VERSION ""

NS_ :

BS_:

BU_: TM

BO_ 1158 BRAKE_SF: 8 Vector__XXX
 SG_ EPAS_Invalid_Failure_Status : 33|2@0+ (1,0) [0|3] ""  TM
 SG_ SAS_MTO_Failure_Status : 29|2@0+ (1,0) [0|3] ""  TM
 SG_ EPAS_MRC_Failure_Status : 63|2@0+ (1,0) [0|3] ""  TM
 SG_ EPAS_CRC_Failure_Status : 49|2@0+ (1,0) [0|3] ""  TM
 SG_ EPAS_MTO_Failure_Status : 53|2@0+ (1,0) [0|3] ""  TM
 SG_ ESP_SW_Version : 7|8@0+ (1,0) [0|255] ""  TM
 SG_ ESP_Err_State_Trans_Cntr : 15|8@0+ (1,0) [0|255] ""  TM
 SG_ BattVolt_ESP : 23|8@0+ (0.1,0) [0|25] "V"  TM
 SG_ ESP_BO_Failure_Status : 25|2@0+ (1,0) [0|3] ""  TM
 SG_ ESP_EP_Failure_Status : 27|2@0+ (1,0) [0|3] ""  TM
 SG_ DCS_MTO_Failure_Status : 31|2@0+ (1,0) [0|3] ""  TM
 SG_ AMT_AT_DCT_MTO_Failure_Status : 35|2@0+ (1,0) [0|3] ""  TM
 SG_ DCS_Invalid_Failure_Status : 37|2@0+ (1,0) [0|3] ""  TM
 SG_ AMT_AT_DCT_Invalid_Failure__0000 : 39|2@0+ (1,0) [0|3] ""  TM
 SG_ EMsMToFailureStatus : 41|2@0+ (1,0) [0|3] ""  TM
 SG_ ESClMToFailureStatus : 43|2@0+ (1,0) [0|3] ""  TM
 SG_ EMsInvalidFailureStatus : 45|2@0+ (1,0) [0|3] ""  TM
 SG_ BCmMToFailureStatus : 47|2@0+ (1,0) [0|3] ""  TM
 SG_ BCM_Invalid_Status_Failure : 51|2@0+ (1,0) [0|3] ""  TM
 SG_ IPcInvalidFailureStatus : 55|2@0+ (1,0) [0|3] ""  TM
 SG_ IPcMToFailureStatus : 57|2@0+ (1,0) [0|3] ""  TM
 SG_ EMsCRcFailureStatus : 59|2@0+ (1,0) [0|3] ""  TM
 SG_ EMsMRcFailureStatus : 61|2@0+ (1,0) [0|3] ""  TM

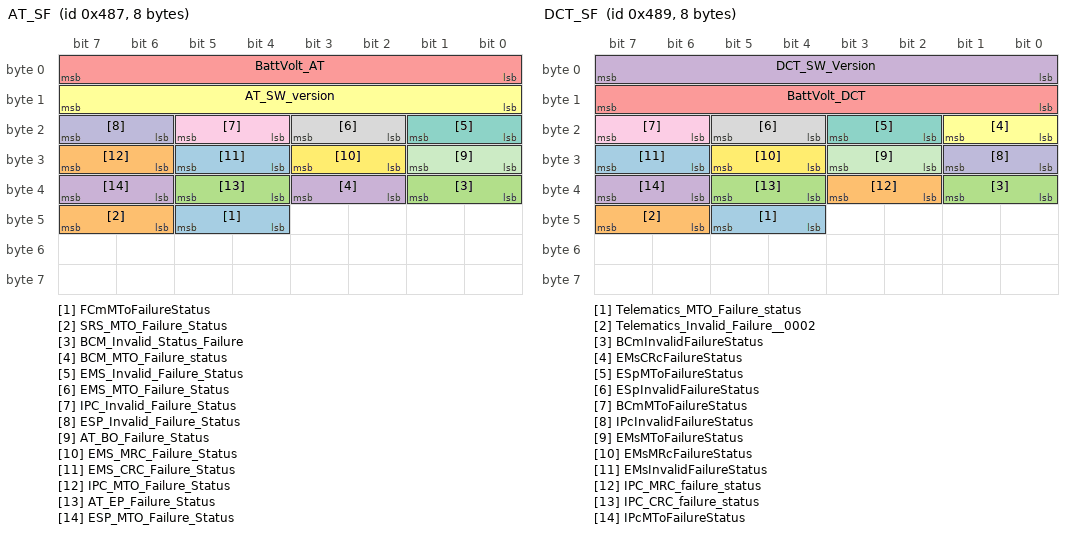
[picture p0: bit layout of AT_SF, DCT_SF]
BO_ 1159 AT_SF: 8 Vector__XXX
 SG_ FCmMToFailureStatus : 45|2@0+ (1,0) [0|3] ""  TM
 SG_ SRS_MTO_Failure_Status : 47|2@0+ (1,0) [0|3] ""  TM
 SG_ BCM_Invalid_Status_Failure : 33|2@0+ (1,0) [0|3] ""  TM
 SG_ BCM_MTO_Failure_status : 35|2@0+ (1,0) [0|3] ""  TM
 SG_ BattVolt_AT : 7|8@0+ (0.1,0) [0|25] ""  TM
 SG_ AT_SW_version : 15|8@0+ (1,0) [0|255] ""  TM
 SG_ EMS_Invalid_Failure_Status : 17|2@0+ (1,0) [0|3] ""  TM
 SG_ EMS_MTO_Failure_Status : 19|2@0+ (1,0) [0|3] ""  TM
 SG_ IPC_Invalid_Failure_Status : 21|2@0+ (1,0) [0|3] ""  TM
 SG_ ESP_Invalid_Failure_Status : 23|2@0+ (1,0) [0|3] ""  TM
 SG_ AT_BO_Failure_Status : 25|2@0+ (1,0) [0|3] ""  TM
 SG_ EMS_MRC_Failure_Status : 27|2@0+ (1,0) [0|3] ""  TM
 SG_ EMS_CRC_Failure_Status : 29|2@0+ (1,0) [0|3] ""  TM
 SG_ IPC_MTO_Failure_Status : 31|2@0+ (1,0) [0|3] ""  TM
 SG_ AT_EP_Failure_Status : 37|2@0+ (1,0) [0|3] ""  TM
 SG_ ESP_MTO_Failure_Status : 39|2@0+ (1,0) [0|3] ""  TM

BO_ 1160 AMT_SF: 8 Vector__XXX
 SG_ Telematics_MTO_Failure_status : 21|2@0+ (1,0) [0|3] ""  TM
 SG_ Telematics_Invalid_Failure__0001 : 23|2@0+ (1,0) [0|3] ""  TM
 SG_ BCmMToFailureStatus : 29|2@0+ (1,0) [0|3] ""  TM
 SG_ BCmInvalidFailureStatus : 31|2@0+ (1,0) [0|3] ""  TM
 SG_ AMT_DCT_SW_Version : 7|8@0+ (1,0) [0|255] ""  TM
 SG_ AMT_DCT_HW_Version : 15|8@0+ (1,0) [0|255] ""  TM
 SG_ DCS_MTO_Failure_Status : 25|2@0+ (1,0) [0|3] ""  TM
 SG_ DCS_Invalid_Failure_Status : 27|2@0+ (1,0) [0|3] ""  TM
 SG_ AMT_DCT_EP_Failure_Status : 33|2@0+ (1,0) [0|3] ""  TM
 SG_ AMT_DCT_BO_Failure_Status : 35|2@0+ (1,0) [0|3] ""  TM
 SG_ EMsMToFailureStatus : 37|2@0+ (1,0) [0|3] ""  TM
 SG_ EMsInvalidFailureStatus : 39|2@0+ (1,0) [0|3] ""  TM
 SG_ BattVolt_TCU : 47|8@0+ (0.1,0) [0|25] "v"  TM
 SG_ IPC_MRC_failure_status : 49|2@0+ (1,0) [0|3] ""  TM
 SG_ IPcMToFailureStatus : 51|2@0+ (1,0) [0|3] ""  TM
 SG_ IPcInvalidFailureStatus : 53|2@0+ (1,0) [0|3] ""  TM
 SG_ ESP_Invalid_Failure_Status : 55|2@0+ (1,0) [0|3] ""  TM
 SG_ EMsMRcFailureStatus : 57|2@0+ (1,0) [0|3] ""  TM
 SG_ EMsCRcFailureStatus : 59|2@0+ (1,0) [0|3] ""  TM
 SG_ IPC_CRC_failure_status : 61|2@0+ (1,0) [0|3] ""  TM
 SG_ ESpMToFailureStatus : 63|2@0+ (1,0) [0|3] ""  TM

BO_ 1161 DCT_SF: 8 Vector__XXX
 SG_ Telematics_MTO_Failure_status : 45|2@0+ (1,0) [0|3] ""  TM
 SG_ Telematics_Invalid_Failure__0002 : 47|2@0+ (1,0) [0|3] ""  TM
 SG_ BCmInvalidFailureStatus : 33|2@0+ (1,0) [0|3] ""  TM
 SG_ DCT_SW_Version : 7|8@0+ (1,0) [0|255] ""  TM
 SG_ BattVolt_DCT : 15|8@0+ (0.1,0) [0|25] "V"  TM
 SG_ EMsCRcFailureStatus : 17|2@0+ (1,0) [0|3] ""  TM
 SG_ ESpMToFailureStatus : 19|2@0+ (1,0) [0|3] ""  TM
 SG_ ESpInvalidFailureStatus : 21|2@0+ (1,0) [0|3] ""  TM
 SG_ BCmMToFailureStatus : 23|2@0+ (1,0) [0|3] ""  TM
 SG_ IPcInvalidFailureStatus : 25|2@0+ (1,0) [0|3] ""  TM
 SG_ EMsMToFailureStatus : 27|2@0+ (1,0) [0|3] ""  TM
 SG_ EMsMRcFailureStatus : 29|2@0+ (1,0) [0|3] ""  TM
 SG_ EMsInvalidFailureStatus : 31|2@0+ (1,0) [0|3] ""  TM
 SG_ IPC_MRC_failure_status : 35|2@0+ (1,0) [0|3] ""  TM
 SG_ IPC_CRC_failure_status : 37|2@0+ (1,0) [0|3] ""  TM
 SG_ IPcMToFailureStatus : 39|2@0+ (1,0) [0|3] ""  TM

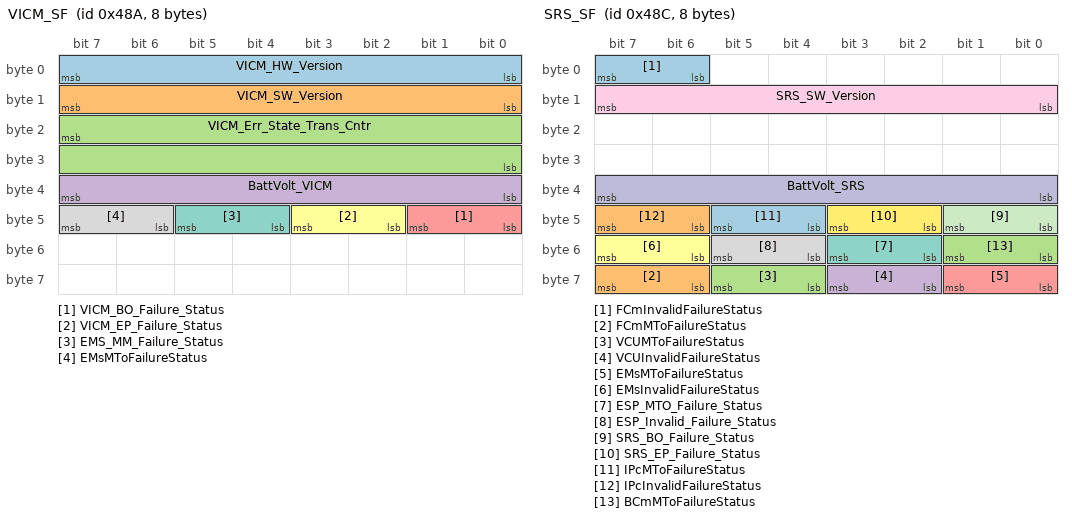
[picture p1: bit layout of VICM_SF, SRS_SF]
BO_ 1162 VICM_SF: 8 Vector__XXX
 SG_ VICM_HW_Version : 7|8@0+ (1,0) [0|255] ""  TM
 SG_ VICM_SW_Version : 15|8@0+ (1,0) [0|99] ""  TM
 SG_ VICM_Err_State_Trans_Cntr : 23|16@0+ (1,0) [0|65535] ""  TM
 SG_ BattVolt_VICM : 39|8@0+ (0.1,0) [0|25] "Volts"  TM
 SG_ VICM_BO_Failure_Status : 41|2@0+ (1,0) [0|3] ""  TM
 SG_ VICM_EP_Failure_Status : 43|2@0+ (1,0) [0|3] ""  TM
 SG_ EMS_MM_Failure_Status : 45|2@0+ (1,0) [0|3] ""  TM
 SG_ EMsMToFailureStatus : 47|2@0+ (1,0) [0|3] ""  TM

BO_ 1164 SRS_SF: 8 Vector__XXX
 SG_ FCmInvalidFailureStatus : 7|2@0+ (1,0) [0|3] ""  TM
 SG_ FCmMToFailureStatus : 63|2@0+ (1,0) [0|3] ""  TM
 SG_ VCUMToFailureStatus : 61|2@0+ (1,0) [0|3] ""  TM
 SG_ VCUInvalidFailureStatus : 59|2@0+ (1,0) [0|3] ""  TM
 SG_ EMsMToFailureStatus : 57|2@0+ (1,0) [0|3] ""  TM
 SG_ EMsInvalidFailureStatus : 55|2@0+ (1,0) [0|3] ""  TM
 SG_ ESP_MTO_Failure_Status : 51|2@0+ (1,0) [0|3] ""  TM
 SG_ ESP_Invalid_Failure_Status : 53|2@0+ (1,0) [0|3] ""  TM
 SG_ SRS_SW_Version : 15|8@0+ (1,0) [0|255] ""  TM
 SG_ BattVolt_SRS : 39|8@0+ (0.1,0) [0|25] "Volts"  TM
 SG_ SRS_BO_Failure_Status : 41|2@0+ (1,0) [0|3] ""  TM
 SG_ SRS_EP_Failure_Status : 43|2@0+ (1,0) [0|3] ""  TM
 SG_ IPcMToFailureStatus : 45|2@0+ (1,0) [0|3] ""  TM
 SG_ IPcInvalidFailureStatus : 47|2@0+ (1,0) [0|3] ""  TM
 SG_ BCmMToFailureStatus : 49|2@0+ (1,0) [0|3] ""  TM

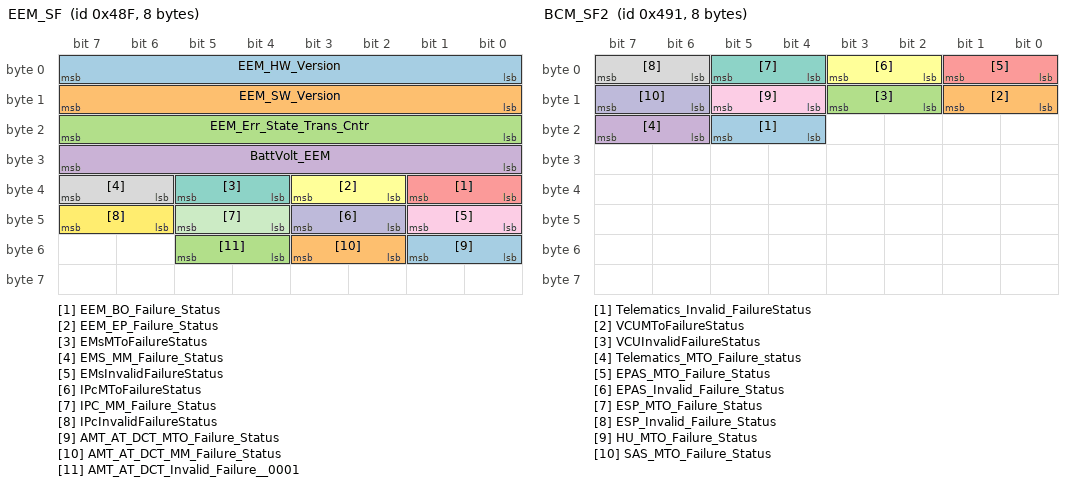
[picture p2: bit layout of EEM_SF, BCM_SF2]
BO_ 1167 EEM_SF: 8 Vector__XXX
 SG_ EEM_HW_Version : 7|8@0+ (1,0) [0|99] ""  TM
 SG_ EEM_SW_Version : 15|8@0+ (1,0) [0|255] ""  TM
 SG_ EEM_Err_State_Trans_Cntr : 23|8@0+ (1,0) [0|255] ""  TM
 SG_ BattVolt_EEM : 31|8@0+ (0.1,0) [0|25] "Volts"  TM
 SG_ EEM_BO_Failure_Status : 33|2@0+ (1,0) [0|3] ""  TM
 SG_ EEM_EP_Failure_Status : 35|2@0+ (1,0) [0|3] ""  TM
 SG_ EMsMToFailureStatus : 37|2@0+ (1,0) [0|3] ""  TM
 SG_ EMS_MM_Failure_Status : 39|2@0+ (1,0) [0|3] ""  TM
 SG_ EMsInvalidFailureStatus : 41|2@0+ (1,0) [0|3] ""  TM
 SG_ IPcMToFailureStatus : 43|2@0+ (1,0) [0|3] ""  TM
 SG_ IPC_MM_Failure_Status : 45|2@0+ (1,0) [0|3] ""  TM
 SG_ IPcInvalidFailureStatus : 47|2@0+ (1,0) [0|3] ""  TM
 SG_ AMT_AT_DCT_MTO_Failure_Status : 49|2@0+ (1,0) [0|3] ""  TM
 SG_ AMT_AT_DCT_MM_Failure_Status : 51|2@0+ (1,0) [0|3] ""  TM
 SG_ AMT_AT_DCT_Invalid_Failure__0001 : 53|2@0+ (1,0) [0|3] ""  TM

BO_ 1168 BCM_SF: 8 Vector__XXX
 SG_ SRR_MTO_Failure_Status : 35|2@0+ (1,0) [0|3] ""  TM
 SG_ FCmMToFailureStatus : 31|2@0+ (1,0) [0|3] ""  TM
 SG_ BCM_SW_Version : 7|8@0+ (1,0) [0|255] ""  TM
 SG_ AMT_AT_DCT_MTO_Failure_Status : 9|2@0+ (1,0) [0|3] ""  TM
 SG_ PEPS_MRC_Failure_Status : 11|2@0+ (1,0) [0|3] ""  TM
 SG_ AMT_AT_DCT_Invalid_Failure__0002 : 13|2@0+ (1,0) [0|3] ""  TM
 SG_ PEPS_CRC_Failure_Status : 15|2@0+ (1,0) [0|3] ""  TM
 SG_ BCM_Err_State_Trans_Cntr : 23|8@0+ (1,0) [0|255] ""  TM
 SG_ BCM_EP_Failure_Status : 25|2@0+ (1,0) [0|3] ""  TM
 SG_ EMsInvalidFailureStatus : 27|2@0+ (1,0) [0|3] ""  TM
 SG_ EMsMToFailureStatus : 29|2@0+ (1,0) [0|3] ""  TM
 SG_ BCM_BO_Failure_Status : 33|2@0+ (1,0) [0|3] ""  TM
 SG_ IPcMToFailureStatus : 37|2@0+ (1,0) [0|3] ""  TM
 SG_ IPcInvalidFailureStatus : 39|2@0+ (1,0) [0|3] ""  TM
 SG_ SRS_MTO_Failure_Status : 41|2@0+ (1,0) [0|3] ""  TM
 SG_ VICM_Invalid_Failure_Status : 45|2@0+ (1,0) [0|3] ""  TM
 SG_ CCM_MTO_Failure_Status : 49|2@0+ (1,0) [0|3] ""  TM
 SG_ CCM_Invalid_Failure_Status : 51|2@0+ (1,0) [0|3] ""  TM
 SG_ VICM_MTO_Failure_Status : 53|2@0+ (1,0) [0|3] ""  TM
 SG_ PEPS_Invalid_failure_status : 57|2@0+ (1,0) [0|3] ""  TM
 SG_ PEPS_MTO_Failure_Status : 59|2@0+ (1,0) [0|3] ""  TM
 SG_ Trailer_MTO_Failure_Status : 61|2@0+ (1,0) [0|3] ""  TM
 SG_ TPMS_MTO_Failure_status : 63|2@0+ (1,0) [0|3] ""  TM

BO_ 1169 BCM_SF2: 8 Vector__XXX
 SG_ Telematics_Invalid_FailureStatus : 21|2@0+ (1,0) [0|3] ""  TM
 SG_ VCUMToFailureStatus : 9|2@0+ (1,0) [0|3] ""  TM
 SG_ VCUInvalidFailureStatus : 11|2@0+ (1,0) [0|3] ""  TM
 SG_ Telematics_MTO_Failure_status : 23|2@0+ (1,0) [0|3] ""  TM
 SG_ EPAS_MTO_Failure_Status : 1|2@0+ (1,0) [0|3] ""  TM
 SG_ EPAS_Invalid_Failure_Status : 3|2@0+ (1,0) [0|3] ""  TM
 SG_ ESP_MTO_Failure_Status : 5|2@0+ (1,0) [0|3] ""  TM
 SG_ ESP_Invalid_Failure_Status : 7|2@0+ (1,0) [0|3] ""  TM
 SG_ HU_MTO_Failure_Status : 13|2@0+ (1,0) [0|3] ""  TM
 SG_ SAS_MTO_Failure_Status : 15|2@0+ (1,0) [0|3] ""  TM

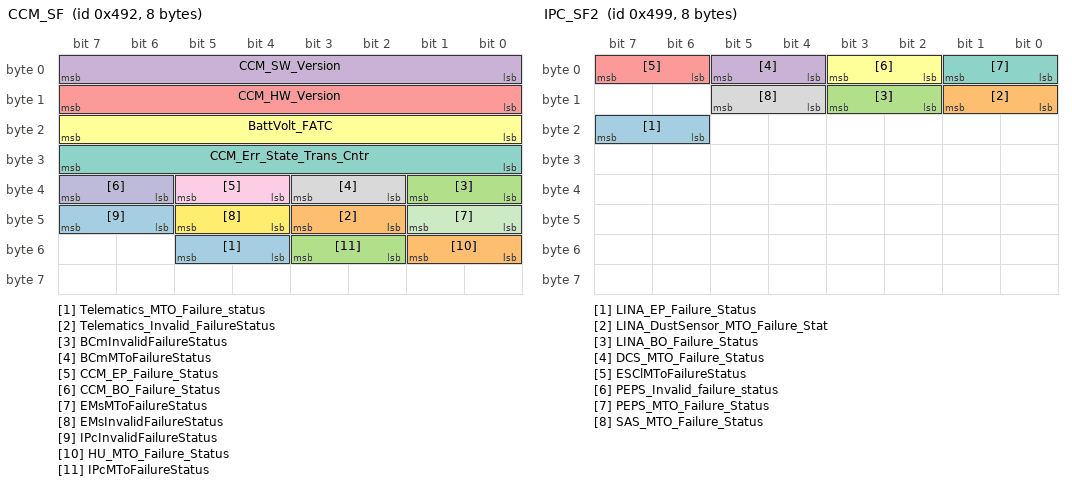
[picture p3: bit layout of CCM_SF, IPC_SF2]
BO_ 1170 CCM_SF: 8 Vector__XXX
 SG_ Telematics_MTO_Failure_status : 53|2@0+ (1,0) [0|3] ""  TM
 SG_ Telematics_Invalid_FailureStatus : 43|2@0+ (1,0) [0|3] ""  TM
 SG_ BCmInvalidFailureStatus : 33|2@0+ (1,0) [0|3] ""  TM
 SG_ CCM_SW_Version : 7|8@0+ (1,0) [0|255] ""  TM
 SG_ CCM_HW_Version : 15|8@0+ (1,0) [0|255] ""  TM
 SG_ BattVolt_FATC : 23|8@0+ (0.1,0) [0|25] "Volts"  TM
 SG_ CCM_Err_State_Trans_Cntr : 31|8@0+ (1,0) [0|255] ""  TM
 SG_ BCmMToFailureStatus : 35|2@0+ (1,0) [0|3] ""  TM
 SG_ CCM_EP_Failure_Status : 37|2@0+ (1,0) [0|3] ""  TM
 SG_ CCM_BO_Failure_Status : 39|2@0+ (1,0) [0|3] ""  TM
 SG_ EMsMToFailureStatus : 41|2@0+ (1,0) [0|3] ""  TM
 SG_ EMsInvalidFailureStatus : 45|2@0+ (1,0) [0|3] ""  TM
 SG_ IPcInvalidFailureStatus : 47|2@0+ (1,0) [0|3] ""  TM
 SG_ HU_MTO_Failure_Status : 49|2@0+ (1,0) [0|3] ""  TM
 SG_ IPcMToFailureStatus : 51|2@0+ (1,0) [0|3] ""  TM

BO_ 1173 HU_SF: 8 Vector__XXX
 SG_ SRR_MTO_Failure_Status : 63|2@0+ (1,0) [0|3] ""  TM
 SG_ FCmMToFailureStatus : 35|2@0+ (1,0) [0|3] ""  TM
 SG_ Telematics_Invalid_FailureStatus : 29|2@0+ (1,0) [0|3] ""  TM
 SG_ VCUMToFailureStatus : 19|2@0+ (1,0) [0|3] ""  TM
 SG_ VCUInvalidFailureStatus : 23|2@0+ (1,0) [0|3] ""  TM
 SG_ Telematics_MTO_Failure_status : 13|2@0+ (1,0) [0|3] ""  TM
 SG_ HU_SW_Version : 7|8@0+ (1,0) [0|255] ""  TM
 SG_ EMsInvalidFailureStatus : 9|2@0+ (1,0) [0|3] ""  TM
 SG_ AMT_AT_DCT_MTO_Failure_Status : 11|2@0+ (1,0) [0|3] ""  TM
 SG_ AMT_AT_DCT_Invalid_Failure__0003 : 15|2@0+ (1,0) [0|3] ""  TM
 SG_ ESpMToFailureStatus : 17|2@0+ (1,0) [0|3] ""  TM
 SG_ ESpInvalidFailureStatus : 21|2@0+ (1,0) [0|3] ""  TM
 SG_ CCM_Invalid_Failure_Status : 25|2@0+ (1,0) [0|3] ""  TM
 SG_ SRS_MTO_Failure_Status : 27|2@0+ (1,0) [0|3] ""  TM
 SG_ EMsMToFailureStatus : 31|2@0+ (1,0) [0|3] ""  TM
 SG_ PDC_MTO_Failure_Status : 33|2@0+ (1,0) [0|3] ""  TM
 SG_ IPcMToFailureStatus : 37|2@0+ (1,0) [0|3] ""  TM
 SG_ IPcInvalidFailureStatus : 39|2@0+ (1,0) [0|3] ""  TM
 SG_ PDC_Invalid_Failure_Status : 41|2@0+ (1,0) [0|3] ""  TM
 SG_ SAS_Invalid_Failure_Status : 43|2@0+ (1,0) [0|3] ""  TM
 SG_ SAS_MTO_Failure_Status : 45|2@0+ (1,0) [0|3] ""  TM
 SG_ EPAS_MTO_Failure_Status : 47|2@0+ (1,0) [0|3] ""  TM
 SG_ EPAS_Invalid_Failure_Status : 49|2@0+ (1,0) [0|3] ""  TM
 SG_ TPMS_MTO_Failure_status : 51|2@0+ (1,0) [0|3] ""  TM
 SG_ CCM_MTO_Failure_Status : 53|2@0+ (1,0) [0|3] ""  TM
 SG_ HU_EP_Failure_Status : 55|2@0+ (1,0) [0|3] ""  TM
 SG_ PEPS_MTO_Failure_Status : 57|2@0+ (1,0) [0|3] ""  TM
 SG_ BCmMToFailureStatus : 59|2@0+ (1,0) [0|3] ""  TM
 SG_ HU_BO_Failure_Status : 61|2@0+ (1,0) [0|3] ""  TM

BO_ 1174 HU_SF2: 8 Vector__XXX
 SG_ PEPS_Invalid_failure_status : 5|2@0+ (1,0) [0|3] ""  TM
 SG_ BCM_Invalid_Status_Failure : 7|2@0+ (1,0) [0|3] ""  TM

BO_ 1176 IPC_SF: 8 Vector__XXX
 SG_ FCmInvalidFailureStatus : 31|2@0+ (1,0) [0|3] ""  TM
 SG_ SRR_MTO_Failure_Status : 17|2@0+ (1,0) [0|3] ""  TM
 SG_ FCmMToFailureStatus : 19|2@0+ (1,0) [0|3] ""  TM
 SG_ BCM_Invalid_Status_Failure : 29|2@0+ (1,0) [0|3] ""  TM
 SG_ BCmMToFailureStatus : 25|2@0+ (1,0) [0|3] ""  TM
 SG_ CCM_Invalid_Failure_Status : 15|2@0+ (1,0) [0|3] ""  TM
 SG_ CCM_MTO_Failure_Status : 59|2@0+ (1,0) [0|3] ""  TM
 SG_ EMsInvalidFailureStatus : 35|2@0+ (1,0) [0|3] ""  TM
 SG_ EMsMToFailureStatus : 33|2@0+ (1,0) [0|3] ""  TM
 SG_ EPAS_Invalid_Failure_Status : 11|2@0+ (1,0) [0|3] ""  TM
 SG_ EPAS_MTO_Failure_Status : 45|2@0+ (1,0) [0|3] ""  TM
 SG_ ESpInvalidFailureStatus : 55|2@0+ (1,0) [0|3] ""  TM
 SG_ ESpMToFailureStatus : 51|2@0+ (1,0) [0|3] ""  TM
 SG_ HU_MTO_Failure_Status : 39|2@0+ (1,0) [0|3] ""  TM
 SG_ IPC_BO_Failure_Status : 23|2@0+ (1,0) [0|3] ""  TM
 SG_ IPC_EP_Failure_Status : 21|2@0+ (1,0) [0|3] ""  TM
 SG_ IPC_Err_State_Trans_Cntr : 47|2@0+ (1,0) [0|3] ""  TM
 SG_ IPC_SW_Version : 7|8@0+ (1,0) [0|99] ""  TM
 SG_ SRS_MTO_Failure_Status : 61|2@0+ (1,0) [0|3] ""  TM
 SG_ AMT_AT_DCT_Invalid_Failure__0004 : 13|2@0+ (1,0) [0|3] ""  TM
 SG_ AMT_AT_DCT_MTO_Failure_Status : 9|2@0+ (1,0) [0|3] ""  TM
 SG_ TPMS_MTO_Failure_status : 63|2@0+ (1,0) [0|3] ""  TM

BO_ 1177 IPC_SF2: 8 Vector__XXX
 SG_ LINA_EP_Failure_Status : 23|2@0+ (1,0) [0|3] ""  TM
 SG_ LINA_DustSensor_MTO_Failure_Stat : 9|2@0+ (1,0) [0|3] ""  TM
 SG_ LINA_BO_Failure_Status : 11|2@0+ (1,0) [0|3] ""  TM
 SG_ DCS_MTO_Failure_Status : 5|2@0+ (1,0) [0|3] ""  TM
 SG_ ESClMToFailureStatus : 7|2@0+ (1,0) [0|3] ""  TM
 SG_ PEPS_Invalid_failure_status : 3|2@0+ (1,0) [0|3] ""  TM
 SG_ PEPS_MTO_Failure_Status : 1|2@0+ (1,0) [0|3] ""  TM
 SG_ SAS_MTO_Failure_Status : 13|2@0+ (1,0) [0|3] ""  TM

BO_ 1178 PEPS_SF: 8 Vector__XXX
 SG_ Telematics_Invalid_Failure__0003 : 61|2@0+ (1,0) [0|3] ""  TM
 SG_ Telematics_MTO_Failure : 49|2@0+ (1,0) [0|3] ""  TM
 SG_ VCUInvalidFailureStatus : 51|2@0+ (1,0) [0|3] ""  TM
 SG_ VCUMToFailureStatus : 63|2@0+ (1,0) [0|3] ""  TM
 SG_ PEPsSwVersion : 7|8@0+ (1,0) [0|255] ""  TM
 SG_ BattVoltPEPS : 15|8@0+ (0.1,0) [0|25] "Volts"  TM
 SG_ PEPsEpFailureStatus : 17|2@0+ (1,0) [0|3] ""  TM
 SG_ PEPsBoFailureStatus : 19|2@0+ (1,0) [0|3] ""  TM
 SG_ ESClInvalidFailureStatus : 21|2@0+ (1,0) [0|3] ""  TM
 SG_ ESClMToFailureStatus : 23|2@0+ (1,0) [0|3] ""  TM
 SG_ BCmCRcFailureStatus : 25|2@0+ (1,0) [0|3] ""  TM
 SG_ BCmMRcFailureStatus : 27|2@0+ (1,0) [0|3] ""  TM
 SG_ BCmInvalidFailureStatus : 29|2@0+ (1,0) [0|3] ""  TM
 SG_ BCmMToFailureStatus : 31|2@0+ (1,0) [0|3] ""  TM
 SG_ ESpCRcFailureStatus : 33|2@0+ (1,0) [0|3] ""  TM
 SG_ ESpMRcFailureStutus : 35|2@0+ (1,0) [0|3] ""  TM
 SG_ ESpInvalidFailureStatus : 37|2@0+ (1,0) [0|3] ""  TM
 SG_ ESpMToFailureStatus : 39|2@0+ (1,0) [0|3] ""  TM
 SG_ EMsCRcFailureStatus : 41|2@0+ (1,0) [0|3] ""  TM
 SG_ EMsMRcFailureStatus : 43|2@0+ (1,0) [0|3] ""  TM
 SG_ EMsInvalidFailureStatus : 45|2@0+ (1,0) [0|3] ""  TM
 SG_ EMsMToFailureStatus : 47|2@0+ (1,0) [0|3] ""  TM
 SG_ AMT_AT_DCT_MTO_Failure_Status : 53|2@0+ (1,0) [0|3] ""  TM
 SG_ AMT_AT_DCT_Invalid_Failure__0005 : 55|2@0+ (1,0) [0|3] ""  TM

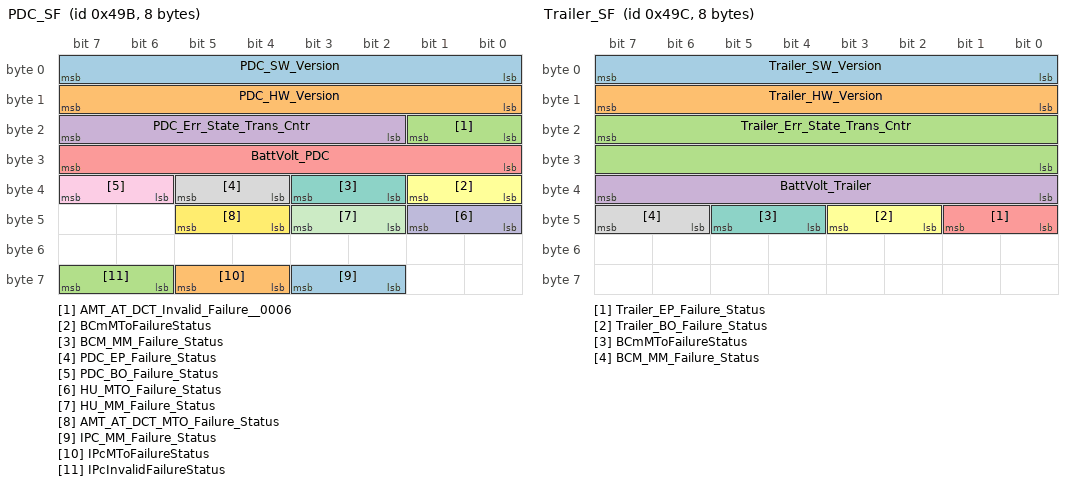
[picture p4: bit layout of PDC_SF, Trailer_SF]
BO_ 1179 PDC_SF: 8 Vector__XXX
 SG_ PDC_SW_Version : 7|8@0+ (1,0) [0|255] ""  TM
 SG_ PDC_HW_Version : 15|8@0+ (1,0) [0|255] ""  TM
 SG_ AMT_AT_DCT_Invalid_Failure__0006 : 17|2@0+ (1,0) [0|3] ""  TM
 SG_ PDC_Err_State_Trans_Cntr : 23|6@0+ (1,0) [0|63] ""  TM
 SG_ BattVolt_PDC : 31|8@0+ (1,0) [0|255] ""  TM
 SG_ BCmMToFailureStatus : 33|2@0+ (1,0) [0|3] ""  TM
 SG_ BCM_MM_Failure_Status : 35|2@0+ (1,0) [0|3] ""  TM
 SG_ PDC_EP_Failure_Status : 37|2@0+ (1,0) [0|3] ""  TM
 SG_ PDC_BO_Failure_Status : 39|2@0+ (1,0) [0|3] ""  TM
 SG_ HU_MTO_Failure_Status : 41|2@0+ (1,0) [0|3] ""  TM
 SG_ HU_MM_Failure_Status : 43|2@0+ (1,0) [0|3] ""  TM
 SG_ AMT_AT_DCT_MTO_Failure_Status : 45|2@0+ (1,0) [0|3] ""  TM
 SG_ IPC_MM_Failure_Status : 59|2@0+ (1,0) [0|3] ""  TM
 SG_ IPcMToFailureStatus : 61|2@0+ (1,0) [0|3] ""  TM
 SG_ IPcInvalidFailureStatus : 63|2@0+ (1,0) [0|3] ""  TM

BO_ 1180 Trailer_SF: 8 Vector__XXX
 SG_ Trailer_SW_Version : 7|8@0+ (1,0) [0|255] ""  TM
 SG_ Trailer_HW_Version : 15|8@0+ (1,0) [0|255] ""  TM
 SG_ Trailer_Err_State_Trans_Cntr : 23|16@0+ (1,0) [0|65535] ""  TM
 SG_ BattVolt_Trailer : 39|8@0+ (0.1,0) [0|25] "v"  TM
 SG_ Trailer_EP_Failure_Status : 41|2@0+ (1,0) [0|3] ""  TM
 SG_ Trailer_BO_Failure_Status : 43|2@0+ (1,0) [0|3] ""  TM
 SG_ BCmMToFailureStatus : 45|2@0+ (1,0) [0|3] ""  TM
 SG_ BCM_MM_Failure_Status : 47|2@0+ (1,0) [0|3] ""  TM

CM_ BO_ 1158 "Supervsion frame transmitted by ABS/ESP";
CM_ SG_ 1158 EPAS_Invalid_Failure_Status "Status of the EPAS signal implausible  failure detected    as per  communication layer spec";
CM_ SG_ 1158 SAS_MTO_Failure_Status "Status of the SAS  Message timeout  failure detected as per Tata-IVN_Specification_Network_Management.";
CM_ SG_ 1158 EPAS_MTO_Failure_Status "Status of the EPAS  Message timeout failure detected as per Tata-IVN_Specification_Network_Management.";
CM_ SG_ 1158 ESP_SW_Version "SW Version of ESP ECU";
CM_ SG_ 1158 ESP_Err_State_Trans_Cntr "Number of state transitions from bus ON to bus OFF state. Reset this value to Zero in each new Ignition cycle. Freeze this value to 255 if number of state transitions are more than this value in a given Ignition cycle. ";
CM_ SG_ 1158 BattVolt_ESP "Battery voltage of EPAS.";
CM_ SG_ 1158 ESP_BO_Failure_Status "Bus off failure flag of ESP ECU";
CM_ SG_ 1158 ESP_EP_Failure_Status "Status of the error-passive failure detected by  ESPECU as per Tata-IVN_Specification_Network_Management.  ";
CM_ SG_ 1158 DCS_MTO_Failure_Status "Status of the DCS messege timeout";
CM_ SG_ 1158 AMT_AT_DCT_MTO_Failure_Status "Status of the TCM Message Timeout  failure detected as per Tata-IVN_Specification_Network_Management.";
CM_ SG_ 1158 DCS_Invalid_Failure_Status "Status of the  DCS Invalid  signal  failure detected as per Tata-IVN_Specification_Network_Management.Status of the  DCS Invalid  signal  failure detected as per Tata-IVN_Specification_Network_Management.";
CM_ SG_ 1158 AMT_AT_DCT_Invalid_Failure__0000 "Status of the TCM invalid failure detected as per Tata-IVN_Specification_Network_Management.";
CM_ SG_ 1158 EMsMToFailureStatus "Status of the EMS message timeout failure detected as per Tata-IVN_Specification_Network_Management.";
CM_ SG_ 1158 EMsInvalidFailureStatus "status of the EMS Invalid  signal  failure detected as per Tata-IVN_Specification_Network_Management.";
CM_ SG_ 1158 BCmMToFailureStatus "Status of the BCM Message timeout  failure detected as per Tata-IVN_Specification_Network_Management.";
CM_ SG_ 1158 BCM_Invalid_Status_Failure "Invalid data reception from BCM ECU failure flag";
CM_ SG_ 1158 IPcInvalidFailureStatus "Status of the IC Invalid  signal  failure detected as per Tata-IVN_Specification_Network_Management.";
CM_ SG_ 1158 IPcMToFailureStatus "Status of the IPC Message Timeout  failure detected as per Tata-IVN_Specification_Network_Management.";
CM_ SG_ 1159 FCmMToFailureStatus "Status of the FCM Message timeout  failure detected as per Tata-IVN_Specification_Network_Management.";
CM_ SG_ 1159 SRS_MTO_Failure_Status "Status of the SRS  Message timeout  failure detected as per Tata-IVN_Specification_Network_Management.";
CM_ SG_ 1159 BCM_Invalid_Status_Failure "Invalid data reception from BCM ECU failure flag";
CM_ SG_ 1159 BCM_MTO_Failure_status "Message timeout failure flag against BCM ECU";
CM_ SG_ 1159 BattVolt_AT "Battery voltage evaluated by AT";
CM_ SG_ 1159 AT_SW_version "Software version of AT ECU";
CM_ SG_ 1159 EMS_Invalid_Failure_Status "status of the EMS Invalid  signal  failure detected as per Tata-IVN_Specification_Network_Management.";
CM_ SG_ 1159 EMS_MTO_Failure_Status "Status of the EMS message timeout failure detected as per Tata-IVN_Specification_Network_Management.";
CM_ SG_ 1159 IPC_Invalid_Failure_Status "Status of the IC Invalid  signal  failure detected ";
CM_ SG_ 1159 ESP_Invalid_Failure_Status "Status of the ESP  Message timeout failure detected as per Tata-IVN_Specification_Network_Management.";
CM_ SG_ 1159 AT_BO_Failure_Status "Status of the bus-off failure detected by AT ECU as per Tata-IVN_Specification_Network_Management.";
CM_ SG_ 1159 EMS_MRC_Failure_Status "Status of the message rolling counter failure detected by IC ECU as per communication layer spec";
CM_ SG_ 1159 EMS_CRC_Failure_Status "Status of the cyclic reduntancy failure detected by IC ECU as per communication layer spec.";
CM_ SG_ 1159 IPC_MTO_Failure_Status "Status of the IPC  messege timeout";
CM_ SG_ 1159 AT_EP_Failure_Status "Status of the error-passive failure detected by AT ECU as per Tata-IVN_Specification_Network_Management.";
CM_ SG_ 1159 ESP_MTO_Failure_Status "Status of the ESP  Message timeout failure detected as per Tata-IVN_Specification_Network_Management.";
CM_ BO_ 1160 "supervision frame transmitted by AMT";
CM_ SG_ 1160 Telematics_MTO_Failure_status "Status of the Telematics Message timeout failure detected as per Tata-IVN_Specification_Network_Management.";
CM_ SG_ 1160 Telematics_Invalid_Failure__0001 "Status of the Telematics Invalid failure detected as per Tata-IVN_Specification_Network_Management.";
CM_ SG_ 1160 BCmMToFailureStatus "Status of the BCM Message timeout  failure detected as per Tata-IVN_Specification_Network_Management.";
CM_ SG_ 1160 AMT_DCT_SW_Version "SW version of AMT ECU.
";
CM_ SG_ 1160 AMT_DCT_HW_Version "HW version of AMT ECU.
";
CM_ SG_ 1160 DCS_MTO_Failure_Status "Status of the DCS messege timeout";
CM_ SG_ 1160 DCS_Invalid_Failure_Status "Status of the  DCS Invalid  signal  failure detected as per Tata-IVN_Specification_Network_Management.Status of the  DCS Invalid  signal  failure detected as per Tata-IVN_Specification_Network_Management.";
CM_ SG_ 1160 AMT_DCT_EP_Failure_Status "Status of the error-passive failure detected by AMT ECU as per Tata-IVN_Specification_Network_Management.
";
CM_ SG_ 1160 AMT_DCT_BO_Failure_Status "Status of the bus-off failure detected by AMT ECU as per Tata-IVN_Specification_Network_Management.

";
CM_ SG_ 1160 EMsMToFailureStatus "Status of the EMS message timeout failure detected as per Tata-IVN_Specification_Network_Management.";
CM_ SG_ 1160 EMsInvalidFailureStatus "status of the EMS Invalid  signal  failure detected as per Tata-IVN_Specification_Network_Management.";
CM_ SG_ 1160 BattVolt_TCU "Battery voltage evaluated by AMT

";
CM_ SG_ 1160 IPcMToFailureStatus "Status of the IPC Message Timeout  failure detected as per Tata-IVN_Specification_Network_Management.";
CM_ SG_ 1160 IPcInvalidFailureStatus "Status of the IC Invalid  signal  failure detected as per Tata-IVN_Specification_Network_Management.";
CM_ SG_ 1160 ESP_Invalid_Failure_Status "Status of the ESP signal implausible  failure detected  by EPAS  as per  communication layer spec";
CM_ SG_ 1160 ESpMToFailureStatus "Status of the ESP  Message timeout failure detected as per Tata-IVN_Specification_Network_Management.";
CM_ BO_ 1161 "2nd Supervision Frame for TCU";
CM_ SG_ 1161 Telematics_MTO_Failure_status "Status of the Telematics Message timeout failure detected as per Tata-IVN_Specification_Network_Management.";
CM_ SG_ 1161 Telematics_Invalid_Failure__0002 "Status of the Telematics Invalid failure detected as per Tata-IVN_Specification_Network_Management.";
CM_ SG_ 1161 DCT_SW_Version "SW version of DCT ECU.
";
CM_ SG_ 1161 BattVolt_DCT "Battery voltage evaluated by DCT

";
CM_ SG_ 1161 ESpMToFailureStatus "Status of the ESP  Message timeout failure detected as per Tata-IVN_Specification_Network_Management.";
CM_ SG_ 1161 ESpInvalidFailureStatus "Status of the ESP signal implausible  failure detected  by EPAS  as per  communication layer spec";
CM_ SG_ 1161 BCmMToFailureStatus "Status of the BCM Message timeout  failure detected as per Tata-IVN_Specification_Network_Management.";
CM_ SG_ 1161 IPcInvalidFailureStatus "Status of the IC Invalid  signal  failure detected as per Tata-IVN_Specification_Network_Management.";
CM_ SG_ 1161 EMsMToFailureStatus "Status of the EMS message timeout failure detected as per Tata-IVN_Specification_Network_Management.";
CM_ SG_ 1161 EMsInvalidFailureStatus "status of the EMS Invalid  signal  failure detected as per Tata-IVN_Specification_Network_Management.";
CM_ SG_ 1161 IPcMToFailureStatus "Status of the IPC Message Timeout  failure detected as per Tata-IVN_Specification_Network_Management.";
CM_ BO_ 1162 "Supervision frame transmitted by VICM";
CM_ SG_ 1162 VICM_HW_Version "HW Version of the VICM  ECU";
CM_ SG_ 1162 VICM_SW_Version "SW version of VICM ECU.";
CM_ SG_ 1162 VICM_Err_State_Trans_Cntr "Number of state transitions from bus ON to bus OFF state. Reset this value to Zero in each new Ignition cycle. Freeze this value to 65535 if number of state transitions are more than this value in a given Ignition cycle.
";
CM_ SG_ 1162 BattVolt_VICM "Battery voltage evaluated by BCM";
CM_ SG_ 1162 VICM_BO_Failure_Status "Status of the bus-off failure detected by VICM ECU as per Tata-IVN_Specification_Network_Management.

";
CM_ SG_ 1162 VICM_EP_Failure_Status "Status of the error-passive failure detected by VICM ECU as per Tata-IVN_Specification_Network_Management.
";
CM_ SG_ 1162 EMS_MM_Failure_Status "Status of the EMS missing message failure detected as per Tata-IVN_Specification_Network_Management.";
CM_ SG_ 1162 EMsMToFailureStatus "Status of the EMS message timeout failure detected as per Tata-IVN_Specification_Network_Management.";
CM_ BO_ 1164 "Supervision frame transmitted by SRS";
CM_ SG_ 1164 FCmInvalidFailureStatus "Status of the FCM signal implausible  failure detected  by SRS  as per  communication layer spec";
CM_ SG_ 1164 FCmMToFailureStatus "Status of the FCM Message timeout  failure detected as per Tata-IVN_Specification_Network_Management.";
CM_ SG_ 1164 VCUMToFailureStatus "VCUMTO failure status";
CM_ SG_ 1164 VCUInvalidFailureStatus "VCU invalid failure status";
CM_ SG_ 1164 EMsMToFailureStatus "Status of the EMS message timeout failure detected as per Tata-IVN_Specification_Network_Management.";
CM_ SG_ 1164 EMsInvalidFailureStatus "status of the EMS Invalid  signal  failure detected as per Tata-IVN_Specification_Network_Management.";
CM_ SG_ 1164 ESP_MTO_Failure_Status "Status of the ESP  Message timeout failure detected as per Tata-IVN_Specification_Network_Management.";
CM_ SG_ 1164 ESP_Invalid_Failure_Status "Status of the ESP signal implausible  failure as per Tata-IVN_Specification_Network_Management.";
CM_ SG_ 1164 SRS_SW_Version "SW version of SRS ECU.
";
CM_ SG_ 1164 BattVolt_SRS "Battery voltage evaluated by SRS";
CM_ SG_ 1164 SRS_BO_Failure_Status "Status of the bus-off failure detected by SRS ECU as per Tata-IVN_Specification_Network_Management.

";
CM_ SG_ 1164 SRS_EP_Failure_Status "Status of the error-passive failure detected by SRS ECU as per Tata-IVN_Specification_Network_Management.
";
CM_ SG_ 1164 IPcMToFailureStatus "Status of the IPC Message Timeout  failure detected as per Tata-IVN_Specification_Network_Management.";
CM_ SG_ 1164 IPcInvalidFailureStatus "Status of the IC Invalid  signal  failure detected as per Tata-IVN_Specification_Network_Management.";
CM_ SG_ 1164 BCmMToFailureStatus "Status of the BCM Message timeout  failure detected as per Tata-IVN_Specification_Network_Management.";
CM_ BO_ 1167 "Supervision frame transmitted by EEM";
CM_ SG_ 1167 EEM_HW_Version "SW version of EEM ECU.";
CM_ SG_ 1167 EEM_SW_Version "SW version of EEM ECU.
";
CM_ SG_ 1167 EEM_Err_State_Trans_Cntr "Number of state transitions from bus ON to bus OFF state. Reset this value to Zero in each new Ignition cycle. Freeze this value to 65535 if number of state transitions are more than this value in a given Ignition cycle.
";
CM_ SG_ 1167 BattVolt_EEM "Battery voltage evaluated by BCM";
CM_ SG_ 1167 EEM_BO_Failure_Status "Status of the bus-off failure detected by EEM ECU as per Tata-IVN_Specification_Network_Management.

";
CM_ SG_ 1167 EEM_EP_Failure_Status "Status of the error-passive failure detected by EEM ECU as per Tata-IVN_Specification_Network_Management.
";
CM_ SG_ 1167 EMsMToFailureStatus "Status of the EMS message timeout failure detected as per Tata-IVN_Specification_Network_Management.";
CM_ SG_ 1167 EMS_MM_Failure_Status "Status of the EMS missing message failure detected as per Tata-IVN_Specification_Network_Management.";
CM_ SG_ 1167 EMsInvalidFailureStatus "status of the EMS Invalid  signal  failure detected as per Tata-IVN_Specification_Network_Management.";
CM_ SG_ 1167 IPcMToFailureStatus "Status of the IPC Message Timeout  failure detected as per Tata-IVN_Specification_Network_Management.";
CM_ SG_ 1167 IPC_MM_Failure_Status "Status of the IPC Missing Message failure detected as per Tata-IVN_Specification_Network_Management.Status of the IPC Missing Message failure detected as per Tata-IVN_Specification_Network_Management.Status of the IPC Missing Message failure detected as per Tata-IVN_Specification_Network_Management.Status of the IPC Missing Message failure detected as per Tata-IVN_Specification_Network_Management.Status of the IPC Missing Message failure detected as per Tata-IVN_Specification_Network_Management.";
CM_ SG_ 1167 IPcInvalidFailureStatus "Status of the IC Invalid  signal  failure detected as per Tata-IVN_Specification_Network_Management.";
CM_ SG_ 1167 AMT_AT_DCT_MTO_Failure_Status "Status of the TCM Message Timeout  failure detected as per Tata-IVN_Specification_Network_Management.";
CM_ SG_ 1167 AMT_AT_DCT_MM_Failure_Status "Status of the TCM Missing Message failure detected as per Tata-IVN_Specification_Network_Management.";
CM_ SG_ 1167 AMT_AT_DCT_Invalid_Failure__0001 "Status of the TCM invalid failure detected as per Tata-IVN_Specification_Network_Management.";
CM_ BO_ 1168 "Supervision frame transmitted by BCM";
CM_ SG_ 1168 SRR_MTO_Failure_Status "Status of the SRR  Message timeout  failure detected as per Tata-IVN_Specification_Network_Management.";
CM_ SG_ 1168 FCmMToFailureStatus "Status of the FCM Message timeout  failure detected as per Tata-IVN_Specification_Network_Management.";
CM_ SG_ 1168 BCM_SW_Version "SW version of BCM ECU.  ";
CM_ SG_ 1168 AMT_AT_DCT_MTO_Failure_Status "Status of the TCM Message Timeout  failure detected as per Tata-IVN_Specification_Network_Management.";
CM_ SG_ 1168 PEPS_MRC_Failure_Status "Status of the message rolling counter failure detected by IC ECU as per communication layer spec";
CM_ SG_ 1168 AMT_AT_DCT_Invalid_Failure__0002 "Status of the TCM invalid failure detected as per Tata-IVN_Specification_Network_Management.";
CM_ SG_ 1168 PEPS_CRC_Failure_Status "Status of the cyclic reduntancy failure detected by IC ECU as per communication layer spec.";
CM_ SG_ 1168 BCM_Err_State_Trans_Cntr "Number of state transitions from bus ON to bus OFF state. Reset this value to Zero in each new Ignition cycle. Freeze this value to 255 if number of state transitions are more than this value in a given Ignition cycle. ";
CM_ SG_ 1168 BCM_EP_Failure_Status "Status of the error-passive failure detected by BCM ECU as per Tata-IVN_Specification_Network_Management.  ";
CM_ SG_ 1168 EMsInvalidFailureStatus "status of the EMS Invalid  signal  failure detected as per Tata-IVN_Specification_Network_Management.";
CM_ SG_ 1168 EMsMToFailureStatus "Status of the EMS message timeout failure detected as per Tata-IVN_Specification_Network_Management.";
CM_ SG_ 1168 BCM_BO_Failure_Status "Status of the bus-off failure detected by BCM ECU as per Tata-IVN_Specification_Network_Management.";
CM_ SG_ 1168 IPcMToFailureStatus "Status of the IPC Message Timeout  failure detected as per Tata-IVN_Specification_Network_Management.";
CM_ SG_ 1168 IPcInvalidFailureStatus "Status of the IC Invalid  signal  failure detected as per Tata-IVN_Specification_Network_Management.";
CM_ SG_ 1168 SRS_MTO_Failure_Status "Status of the SRS  Message timeout  failure detected as per Tata-IVN_Specification_Network_Management.";
CM_ SG_ 1168 VICM_Invalid_Failure_Status "Status of the VICM  invalid failure detected as per Tata-IVN_Specification_Network_Management.";
CM_ SG_ 1168 CCM_MTO_Failure_Status "Status of the FATC Message timeout failure detected as per Tata-IVN_Specification_Network_Management.";
CM_ SG_ 1168 CCM_Invalid_Failure_Status "Status of the  FATC Invalid  signal  failure detected as per Tata-IVN_Specification_Network_Management.";
CM_ SG_ 1168 VICM_MTO_Failure_Status "Status of the VICM  Message timeout  failure detected as per Tata-IVN_Specification_Network_Management.";
CM_ SG_ 1168 PEPS_Invalid_failure_status "Status of the PEPS invalid failure detected as per Tata-IVN_Specification_Network_Management.";
CM_ SG_ 1168 PEPS_MTO_Failure_Status "Status of the PEPS  Message timeout  failure detected as per Tata-IVN_Specification_Network_Management.";
CM_ SG_ 1168 Trailer_MTO_Failure_Status "Status of the Trailer  Message timeout  failure detected as per Tata-IVN_Specification_Network_Management.";
CM_ SG_ 1168 TPMS_MTO_Failure_status "Message timeout failure flag against TPMS ECU";
CM_ SG_ 1169 Telematics_Invalid_FailureStatus "Status of the Telematics Invalid failure detected as per Tata-IVN_Specification_Network_Management.";
CM_ SG_ 1169 VCUMToFailureStatus "VCUMTO failure status";
CM_ SG_ 1169 VCUInvalidFailureStatus "VCU invalid failure status";
CM_ SG_ 1169 Telematics_MTO_Failure_status "Status of the Telematics Message timeout failure detected as per Tata-IVN_Specification_Network_Management.";
CM_ SG_ 1169 EPAS_MTO_Failure_Status "Status of the EPAS  Message timeout failure detected as per Tata-IVN_Specification_Network_Management.";
CM_ SG_ 1169 EPAS_Invalid_Failure_Status "Status of the EPAS signal implausible  failure detected    as per  communication layer spec";
CM_ SG_ 1169 ESP_MTO_Failure_Status "Status of the ESP  Message timeout failure detected as per Tata-IVN_Specification_Network_Management.";
CM_ SG_ 1169 ESP_Invalid_Failure_Status "Status of the ESP signal implausible  failure detected  by EPAS  as per  communication layer spec";
CM_ SG_ 1169 HU_MTO_Failure_Status "Status of the HU Message timeout failure detected as per Tata-IVN_Specification_Network_Management.";
CM_ SG_ 1169 SAS_MTO_Failure_Status "Status of the SAS  Message timeout  failure detected as per Tata-IVN_Specification_Network_Management.";
CM_ BO_ 1170 "Supervision frame transmitted by FATC";
CM_ SG_ 1170 Telematics_MTO_Failure_status "Status of the Telematics Message timeout failure detected as per Tata-IVN_Specification_Network_Management.";
CM_ SG_ 1170 Telematics_Invalid_FailureStatus "Status of the Telematics Invalid failure detected as per Tata-IVN_Specification_Network_Management.";
CM_ SG_ 1170 CCM_SW_Version "SW Version of the FATC ECU";
CM_ SG_ 1170 CCM_HW_Version "HW Version of the FATC  ECU";
CM_ SG_ 1170 BattVolt_FATC "Battery voltage evaluated by FATC";
CM_ SG_ 1170 CCM_Err_State_Trans_Cntr "Number of state transitions from bus ON to bus OFF state. Reset this value to Zero in each new Ignition cycle. Freeze this value to 255 if number of state transitions are more than this value in a given Ignition cycle.";
CM_ SG_ 1170 BCmMToFailureStatus "Status of the BCM Message timeout  failure detected as per Tata-IVN_Specification_Network_Management.";
CM_ SG_ 1170 CCM_EP_Failure_Status "Status of the error passive detected by FATC ECU as per Tata-IVN_Specification_Network_Management.";
CM_ SG_ 1170 CCM_BO_Failure_Status "Status of the bus-off failure detected by FATC ECU as per Tata-IVN_Specification_Network_Management";
CM_ SG_ 1170 EMsMToFailureStatus "Status of the EMS message timeout failure detected as per Tata-IVN_Specification_Network_Management.";
CM_ SG_ 1170 EMsInvalidFailureStatus "status of the EMS Invalid  signal  failure detected as per Tata-IVN_Specification_Network_Management.";
CM_ SG_ 1170 IPcInvalidFailureStatus "Status of the IC Invalid  signal  failure detected as per Tata-IVN_Specification_Network_Management.";
CM_ SG_ 1170 HU_MTO_Failure_Status "Status of the HU Message timeout failure detected as per Tata-IVN_Specification_Network_Management.";
CM_ SG_ 1170 IPcMToFailureStatus "Status of the IPC Message Timeout  failure detected as per Tata-IVN_Specification_Network_Management.";
CM_ BO_ 1173 "Supervision frame transmitted by HU";
CM_ SG_ 1173 SRR_MTO_Failure_Status "Status of the SRR  Message timeout  failure detected as per Tata-IVN_Specification_Network_Management.";
CM_ SG_ 1173 FCmMToFailureStatus "Status of the FCM Message timeout  failure detected as per Tata-IVN_Specification_Network_Management.";
CM_ SG_ 1173 Telematics_Invalid_FailureStatus "Status of the Telematics Invalid failure detected as per Tata-IVN_Specification_Network_Management.";
CM_ SG_ 1173 VCUMToFailureStatus "VCUMTO failure status";
CM_ SG_ 1173 VCUInvalidFailureStatus "VCU invalid failure status";
CM_ SG_ 1173 Telematics_MTO_Failure_status "Status of the Telematics Message timeout failure detected as per Tata-IVN_Specification_Network_Management.";
CM_ SG_ 1173 HU_SW_Version "SW Version of the HU ECU";
CM_ SG_ 1173 EMsInvalidFailureStatus "status of the EMS Invalid  signal  failure detected as per Tata-IVN_Specification_Network_Management.";
CM_ SG_ 1173 AMT_AT_DCT_MTO_Failure_Status "Status of the TCM Message Timeout  failure detected as per Tata-IVN_Specification_Network_Management.";
CM_ SG_ 1173 AMT_AT_DCT_Invalid_Failure__0003 "Status of the TCM invalid failure detected as per Tata-IVN_Specification_Network_Management.";
CM_ SG_ 1173 ESpMToFailureStatus "Status of the ESP  Message timeout failure detected as per Tata-IVN_Specification_Network_Management.";
CM_ SG_ 1173 ESpInvalidFailureStatus "Status of the ESP signal implausible  failure detected  by EPAS  as per  communication layer spec";
CM_ SG_ 1173 CCM_Invalid_Failure_Status "Status of the  FATC Invalid  signal  failure detected as per Tata-IVN_Specification_Network_Management.";
CM_ SG_ 1173 SRS_MTO_Failure_Status "Status of the SRS  Message timeout  failure detected as per Tata-IVN_Specification_Network_Management.";
CM_ SG_ 1173 EMsMToFailureStatus "Status of the EMS message timeout failure detected as per Tata-IVN_Specification_Network_Management.";
CM_ SG_ 1173 PDC_MTO_Failure_Status "Status of the PDC Message timeout failure detected as per Tata-IVN_Specification_Network_Management.";
CM_ SG_ 1173 IPcMToFailureStatus "Status of the IPC Message Timeout  failure detected as per Tata-IVN_Specification_Network_Management.";
CM_ SG_ 1173 IPcInvalidFailureStatus "Status of the IC Invalid  signal  failure detected as per Tata-IVN_Specification_Network_Management.";
CM_ SG_ 1173 PDC_Invalid_Failure_Status "status of the PDC Invalid  signal  failure detected as per communication layer specification.";
CM_ SG_ 1173 SAS_Invalid_Failure_Status "status of the SAS Invalid  signal  failure detected as per Tata-IVN_Specification_Network_Management.";
CM_ SG_ 1173 SAS_MTO_Failure_Status "Status of the SAS  Message timeout  failure detected as per Tata-IVN_Specification_Network_Management.";
CM_ SG_ 1173 EPAS_MTO_Failure_Status "Status of the EPAS  Message timeout failure detected as per Tata-IVN_Specification_Network_Management.";
CM_ SG_ 1173 EPAS_Invalid_Failure_Status "Status of the EPAS signal implausible  failure detected    as per  communication layer spec";
CM_ SG_ 1173 TPMS_MTO_Failure_status "Message timeout failure flag against TPMS ECU";
CM_ SG_ 1173 CCM_MTO_Failure_Status "Status of the FATC Message timeout failure detected as per Tata-IVN_Specification_Network_Management.";
CM_ SG_ 1173 HU_EP_Failure_Status "Status of the error passive detected by HU ECU as per Tata-IVN_Specification_Network_Management.";
CM_ SG_ 1173 PEPS_MTO_Failure_Status "Status of the PEPS  Message timeout  failure detected as per Tata-IVN_Specification_Network_Management.";
CM_ SG_ 1173 BCmMToFailureStatus "Status of the BCM Message timeout  failure detected as per Tata-IVN_Specification_Network_Management.";
CM_ SG_ 1173 HU_BO_Failure_Status "Status of the bus-off failure detected by HU ECU as per Tata-IVN_Specification_Network_Management";
CM_ SG_ 1174 PEPS_Invalid_failure_status "Status of the PEPS invalid failure detected as per Tata-IVN_Specification_Network_Management.";
CM_ SG_ 1174 BCM_Invalid_Status_Failure "Invalid data reception from BCM ECU failure flag";
CM_ BO_ 1176 "Supervision frame transmitted by IPC";
CM_ SG_ 1176 FCmInvalidFailureStatus "Status of the FCM signal implausible  failure detected  by CDC as per  communication layer spec";
CM_ SG_ 1176 SRR_MTO_Failure_Status "Status of the SRR  Message timeout  failure detected as per Tata-IVN_Specification_Network_Management.";
CM_ SG_ 1176 FCmMToFailureStatus "Status of the FCM Message timeout  failure detected as per Tata-IVN_Specification_Network_Management.";
CM_ SG_ 1176 BCM_Invalid_Status_Failure "Invalid data reception from BCM ECU failure flag";
CM_ SG_ 1176 BCmMToFailureStatus "Status of the BCM Message timeout  failure detected as per Tata-IVN_Specification_Network_Management.";
CM_ SG_ 1176 CCM_Invalid_Failure_Status "Status of the  FATC Invalid  signal  failure detected as per Tata-IVN_Specification_Network_Management.";
CM_ SG_ 1176 CCM_MTO_Failure_Status "Status of the FATC Message timeout failure detected as per Tata-IVN_Specification_Network_Management.";
CM_ SG_ 1176 EMsInvalidFailureStatus "status of the EMS Invalid  signal  failure detected as per Tata-IVN_Specification_Network_Management.";
CM_ SG_ 1176 EMsMToFailureStatus "Status of the EMS message timeout failure detected as per Tata-IVN_Specification_Network_Management.";
CM_ SG_ 1176 EPAS_Invalid_Failure_Status "Status of the EPAS signal implausible  failure detected    as per  communication layer spec";
CM_ SG_ 1176 EPAS_MTO_Failure_Status "Status of the EPAS  Message timeout failure detected as per Tata-IVN_Specification_Network_Management.";
CM_ SG_ 1176 ESpInvalidFailureStatus "Status of the ESP signal implausible  failure detected  by EPAS  as per  communication layer spec";
CM_ SG_ 1176 ESpMToFailureStatus "Status of the ESP  Message timeout failure detected as per Tata-IVN_Specification_Network_Management.";
CM_ SG_ 1176 HU_MTO_Failure_Status "Status of the HU Message timeout failure detected as per Tata-IVN_Specification_Network_Management.";
CM_ SG_ 1176 IPC_BO_Failure_Status "Status of the bus-off failure detected by IC ECU as per Tata-IVN_Specification_Network_Management";
CM_ SG_ 1176 IPC_EP_Failure_Status "Status of the error-passive failure detected by IC ECU as per Tata-IVN_Specification_Network_Management";
CM_ SG_ 1176 IPC_Err_State_Trans_Cntr "Number of state transitions from bus ON to bus OFF state. Reset this value to Zero in each new Ignition cycle. Freeze this value to 3 if number of state transitions are more than this value in a given Ignition cycle.";
CM_ SG_ 1176 IPC_SW_Version "SW version of IC ECU.";
CM_ SG_ 1176 SRS_MTO_Failure_Status "Status of the SRS  Message timeout  failure detected as per Tata-IVN_Specification_Network_Management.";
CM_ SG_ 1176 AMT_AT_DCT_Invalid_Failure__0004 "Status of the TCM invalid failure detected as per Tata-IVN_Specification_Network_Management.";
CM_ SG_ 1176 AMT_AT_DCT_MTO_Failure_Status "Status of the TCM Message Timeout  failure detected as per Tata-IVN_Specification_Network_Management.";
CM_ SG_ 1176 TPMS_MTO_Failure_status "Message timeout failure flag against TPMS ECU";
CM_ SG_ 1177 LINA_EP_Failure_Status "Status of the error-passive failure detected by  IPC LINA as per Tata-IVN_Specification_Network_Management.  ";
CM_ SG_ 1177 LINA_DustSensor_MTO_Failure_Stat "Status of the DustSensor Message timeout  failure detected as per Tata-IVN_Specification_Network_Management.";
CM_ SG_ 1177 LINA_BO_Failure_Status "Bus off failure flag of IPC LINA";
CM_ SG_ 1177 DCS_MTO_Failure_Status "Status of the DCS messege timeout";
CM_ SG_ 1177 PEPS_Invalid_failure_status "Status of the PEPS invalid failure detected as per Tata-IVN_Specification_Network_Management.";
CM_ SG_ 1177 PEPS_MTO_Failure_Status "Status of the PEPS  Message timeout  failure detected as per Tata-IVN_Specification_Network_Management.";
CM_ SG_ 1177 SAS_MTO_Failure_Status "Status of the SAS  Message timeout  failure detected as per Tata-IVN_Specification_Network_Management.";
CM_ SG_ 1178 Telematics_Invalid_Failure__0003 "Status of the Telematics Invalid failure detected as per Tata-IVN_Specification_Network_Management.";
CM_ SG_ 1178 Telematics_MTO_Failure "Status of the Telematics Message timeout failure detected as per Tata-IVN_Specification_Network_Management.";
CM_ SG_ 1178 VCUInvalidFailureStatus "VCU invalid failure status";
CM_ SG_ 1178 VCUMToFailureStatus "VCUMTO failure status";
CM_ SG_ 1178 PEPsSwVersion "SW version of PEPS ECU.
";
CM_ SG_ 1178 BattVoltPEPS "Battery voltage evaluated by PEPS";
CM_ SG_ 1178 PEPsEpFailureStatus "Status of the error-passive failure detected by AMT ECU as per Tata-IVN_Specification_Network_Management.
";
CM_ SG_ 1178 PEPsBoFailureStatus "Status of the bus-off failure detected by PEPS ECU as per Tata-IVN_Specification_Network_Management.

";
CM_ SG_ 1178 BCmMToFailureStatus "Status of the BCM Message timeout  failure detected as per Tata-IVN_Specification_Network_Management.";
CM_ SG_ 1178 ESpInvalidFailureStatus "Status of the ESP signal implausible  failure detected  by EPAS  as per  communication layer spec";
CM_ SG_ 1178 ESpMToFailureStatus "Status of the ESP  Message timeout failure detected as per Tata-IVN_Specification_Network_Management.";
CM_ SG_ 1178 EMsInvalidFailureStatus "status of the EMS Invalid  signal  failure detected as per Tata-IVN_Specification_Network_Management.";
CM_ SG_ 1178 EMsMToFailureStatus "Status of the EMS message timeout failure detected as per Tata-IVN_Specification_Network_Management.";
CM_ SG_ 1178 AMT_AT_DCT_MTO_Failure_Status "Status of the TCM Message Timeout  failure detected as per Tata-IVN_Specification_Network_Management.";
CM_ SG_ 1178 AMT_AT_DCT_Invalid_Failure__0005 "Status of the TCM invalid failure detected as per Tata-IVN_Specification_Network_Management.";
CM_ BO_ 1179 "Supervision frame transmitted by PDC";
CM_ SG_ 1179 PDC_SW_Version "SW Version of the PDC ECU";
CM_ SG_ 1179 PDC_HW_Version "HW Version of the PDC ECU";
CM_ SG_ 1179 AMT_AT_DCT_Invalid_Failure__0006 "Status of the TCM invalid failure detected as per Tata-IVN_Specification_Network_Management.";
CM_ SG_ 1179 PDC_Err_State_Trans_Cntr "Number of state transitions from bus ON to bus OFF state. Reset this value to Zero in each new Ignition cycle. Freeze this value to 63 if number of state transitions are more than this value in a given Ignition cycle.";
CM_ SG_ 1179 BattVolt_PDC "Battery voltage of PDC.";
CM_ SG_ 1179 BCmMToFailureStatus "Status of the BCM Message timeout  failure detected as per Tata-IVN_Specification_Network_Management.";
CM_ SG_ 1179 BCM_MM_Failure_Status "Status of the BCM Missing Message failure detected as per Tata-IVN_Specification_Network_Management.";
CM_ SG_ 1179 PDC_EP_Failure_Status "Status of the error passive detected by PDC ECU as per Tata-IVN_Specification_Network_Management.";
CM_ SG_ 1179 PDC_BO_Failure_Status "Status of the bus-off failure detected by PDC ECU as per Tata-IVN_Specification_Network_Management";
CM_ SG_ 1179 HU_MTO_Failure_Status "Status of the HU Message timeout failure detected as per Tata-IVN_Specification_Network_Management.";
CM_ SG_ 1179 HU_MM_Failure_Status "Status of the HU Missing message failure detected by  as per Tata-IVN_Specification_Network_Management.  ";
CM_ SG_ 1179 AMT_AT_DCT_MTO_Failure_Status "Status of the TCM Message Timeout  failure detected as per Tata-IVN_Specification_Network_Management.";
CM_ SG_ 1179 IPC_MM_Failure_Status "Status of the IPC Missing Message failure detected as per Tata-IVN_Specification_Network_Management.Status of the IPC Missing Message failure detected as per Tata-IVN_Specification_Network_Management.Status of the IPC Missing Message failure detected as per Tata-IVN_Specification_Network_Management.Status of the IPC Missing Message failure detected as per Tata-IVN_Specification_Network_Management.Status of the IPC Missing Message failure detected as per Tata-IVN_Specification_Network_Management.";
CM_ SG_ 1179 IPcMToFailureStatus "Status of the IPC Message Timeout  failure detected as per Tata-IVN_Specification_Network_Management.";
CM_ SG_ 1179 IPcInvalidFailureStatus "Status of the IC Invalid  signal  failure detected as per Tata-IVN_Specification_Network_Management.";
CM_ BO_ 1180 "Supervision frame transmitted by trailer";
CM_ SG_ 1180 Trailer_SW_Version "SW Version of the trailer  ECU";
CM_ SG_ 1180 Trailer_HW_Version "HW version of trailer  ECU.
";
CM_ SG_ 1180 Trailer_Err_State_Trans_Cntr "Number of state transitions from bus ON to bus OFF state. Reset this value to Zero in each new Ignition cycle. Freeze this value to 65535 if number of state transitions are more than this value in a given Ignition cycle.
";
CM_ SG_ 1180 BattVolt_Trailer "Battery voltage evaluated by Trailer

";
CM_ SG_ 1180 Trailer_EP_Failure_Status "Status of the error-passive failure detected by Trailer ECU as per Tata-IVN_Specification_Network_Management.
";
CM_ SG_ 1180 Trailer_BO_Failure_Status "Status of the bus-off failure detected by Trailer ECU as per Tata-IVN_Specification_Network_Management.

";
CM_ SG_ 1180 BCmMToFailureStatus "Status of the BCM Message timeout  failure detected as per Tata-IVN_Specification_Network_Management.";
CM_ SG_ 1180 BCM_MM_Failure_Status "Status of the BCM Missing Message failure detected as per Tata-IVN_Specification_Network_Management.";
BA_DEF_ SG_  "Remarks" STRING ;
BA_DEF_ SG_  "NWM_WakeupAllowed" ENUM  "No","Yes";
BA_DEF_ SG_  "GenSigTimeoutTime_HU_Mid_X451" INT 0 65535;
BA_DEF_ SG_  "GenSigTimeoutTime_HU_High_X451" INT 0 65535;
BA_DEF_ SG_  "GenSigTimeoutTime_HU_B" INT 0 65535;
BA_DEF_ SG_  "GenSigTimeoutTime_HU_A" INT 0 65535;
BA_DEF_ SG_  "GenSigTimeoutTime_BCM_Mid" INT 0 65535;
BA_DEF_ SG_  "GenSigTimeoutMsg_HU_Mid_X451" INT 0 65535;
BA_DEF_ SG_  "GenSigTimeoutMsg_HU_High_X451" INT 0 65535;
BA_DEF_ SG_  "GenSigTimeoutMsg_HU_B" INT 0 65535;
BA_DEF_ SG_  "GenSigTimeoutMsg_HU_A" INT 0 65535;
BA_DEF_ SG_  "GenSigStartValue" INT 0 0;
BA_DEF_ SG_  "GenSigSendType" ENUM  "Cyclic","OnWrite","OnWriteWithRepetition","OnChange","OnChangeWithRepetition","IfActive","IfActiveWithRepetition","NoSigSendType","NotUsed","NotUsed","NotUsed","NotUsed","NotUsed";
BA_DEF_ SG_  "GenSigInactiveValue" INT 0 0;
BA_DEF_ SG_  "GenSigEnvVarType" ENUM  "int","float","undef";
BA_DEF_ SG_  "GenSigCycleTimeActive" INT 0 0;
BA_DEF_ SG_  "GenSigCycleTime" INT 0 0;
BA_DEF_ SG_  "GenSigTimeoutMsg_HU_High_X445" INT 0 65535;
BA_DEF_ SG_  "GenSigTimeoutMsg_HU_Mid_X445" INT 0 65535;
BA_DEF_ SG_  "GenSigTimeoutTime_HU_High_X445" INT 0 65535;
BA_DEF_ SG_  "GenSigTimeoutTime_HU_Mid_X445" INT 0 65535;
BA_DEF_ SG_  "GenSigTimeoutMsg_IVI" INT 0 65535;
BA_DEF_ SG_  "GenSigTimeoutTime_IVI" INT 0 65535;
BA_DEF_ BO_  "NmMessage" ENUM  "no","yes";
BA_DEF_ BO_  "NmAsrMessage" ENUM  "<n.a.>","No","Yes";
BA_DEF_ BO_  "MessageTimeout" INT 0 65535;
BA_DEF_ BO_  "Me" INT 0 0;
BA_DEF_ BO_  "GenMsgStartDelayTime" INT 0 0;
BA_DEF_ BO_  "GenMsgSendType" ENUM  "Cyclic","NotUsed","NotUsed","NotUsed","NotUsed","NotUsed","NotUsed","IfActive","NoMsgSendType","NotUsed";
BA_DEF_ BO_  "GenMsgNrOfRepetition" INT 0 0;
BA_DEF_ BO_  "GenMsgILSupport" ENUM  "No","Yes";
BA_DEF_ BO_  "GenMsgDelayTime" INT 0 0;
BA_DEF_ BO_  "GenMsgCycleTimeFast" INT 0 0;
BA_DEF_ BO_  "GenMsgCycleTime" INT 0 0;
BA_DEF_ BO_  "DiagUudtResponse" ENUM  "false","true";
BA_DEF_ BO_  "DiagUsdtResponse" ENUM  "false","true";
BA_DEF_ BO_  "DiagState" ENUM  "No","Yes";
BA_DEF_ BO_  "DiagResponse" ENUM  "No","Yes";
BA_DEF_ BO_  "DiagRequest" ENUM  "No","Yes";
BA_DEF_ BO_  "MsgType" ENUM  "Application","NM","NMH";
BA_DEF_ SG_  "SystemSignalLongSymbol" STRING ;
BA_DEF_DEF_  "Remarks" "null";
BA_DEF_DEF_  "NWM_WakeupAllowed" "No";
BA_DEF_DEF_  "GenSigTimeoutTime_HU_Mid_X451" 500;
BA_DEF_DEF_  "GenSigTimeoutTime_HU_High_X451" 500;
BA_DEF_DEF_  "GenSigTimeoutTime_HU_B" 500;
BA_DEF_DEF_  "GenSigTimeoutTime_HU_A" 500;
BA_DEF_DEF_  "GenSigTimeoutTime_BCM_Mid" 0;
BA_DEF_DEF_  "GenSigTimeoutMsg_HU_Mid_X451" 500;
BA_DEF_DEF_  "GenSigTimeoutMsg_HU_High_X451" 500;
BA_DEF_DEF_  "GenSigTimeoutMsg_HU_B" 500;
BA_DEF_DEF_  "GenSigTimeoutMsg_HU_A" 500;
BA_DEF_DEF_  "GenSigStartValue" 0;
BA_DEF_DEF_  "GenSigSendType" "Cyclic";
BA_DEF_DEF_  "GenSigInactiveValue" 0;
BA_DEF_DEF_  "GenSigEnvVarType" "undef";
BA_DEF_DEF_  "GenSigCycleTimeActive" 0;
BA_DEF_DEF_  "GenSigCycleTime" 0;
BA_DEF_DEF_  "GenSigTimeoutMsg_HU_High_X445" 500;
BA_DEF_DEF_  "GenSigTimeoutMsg_HU_Mid_X445" 500;
BA_DEF_DEF_  "GenSigTimeoutTime_HU_High_X445" 500;
BA_DEF_DEF_  "GenSigTimeoutTime_HU_Mid_X445" 500;
BA_DEF_DEF_  "GenSigTimeoutMsg_IVI" 500;
BA_DEF_DEF_  "GenSigTimeoutTime_IVI" 500;
BA_DEF_DEF_  "NmMessage" "no";
BA_DEF_DEF_  "NmAsrMessage" "<n.a.>";
BA_DEF_DEF_  "MessageTimeout" 500;
BA_DEF_DEF_  "Me" 0;
BA_DEF_DEF_  "GenMsgStartDelayTime" 0;
BA_DEF_DEF_  "GenMsgSendType" "Cyclic";
BA_DEF_DEF_  "GenMsgNrOfRepetition" 0;
BA_DEF_DEF_  "GenMsgILSupport" "Yes";
BA_DEF_DEF_  "GenMsgDelayTime" 0;
BA_DEF_DEF_  "GenMsgCycleTimeFast" 0;
BA_DEF_DEF_  "GenMsgCycleTime" 0;
BA_DEF_DEF_  "DiagUudtResponse" "false";
BA_DEF_DEF_  "DiagUsdtResponse" "false";
BA_DEF_DEF_  "DiagState" "No";
BA_DEF_DEF_  "DiagResponse" "No";
BA_DEF_DEF_  "DiagRequest" "No";
BA_DEF_DEF_  "MsgType" "Application";
BA_DEF_DEF_  "SystemSignalLongSymbol" "";
BA_ "MessageTimeout" BO_ 1158 0;
BA_ "GenMsgCycleTime" BO_ 1158 100;
BA_ "MessageTimeout" BO_ 1159 0;
BA_ "GenMsgCycleTime" BO_ 1159 100;
BA_ "MessageTimeout" BO_ 1160 0;
BA_ "GenMsgStartDelayTime" BO_ 1160 15;
BA_ "GenMsgCycleTime" BO_ 1160 100;
BA_ "MessageTimeout" BO_ 1161 0;
BA_ "GenMsgCycleTime" BO_ 1161 100;
BA_ "MessageTimeout" BO_ 1162 0;
BA_ "GenMsgCycleTime" BO_ 1162 100;
BA_ "MessageTimeout" BO_ 1164 0;
BA_ "GenMsgCycleTime" BO_ 1164 100;
BA_ "MessageTimeout" BO_ 1167 0;
BA_ "GenMsgCycleTime" BO_ 1167 100;
BA_ "MessageTimeout" BO_ 1168 0;
BA_ "GenMsgCycleTime" BO_ 1168 100;
BA_ "MessageTimeout" BO_ 1169 0;
BA_ "GenMsgCycleTime" BO_ 1169 100;
BA_ "MessageTimeout" BO_ 1170 0;
BA_ "GenMsgCycleTime" BO_ 1170 100;
BA_ "MessageTimeout" BO_ 1173 0;
BA_ "GenMsgCycleTime" BO_ 1173 100;
BA_ "MessageTimeout" BO_ 1174 0;
BA_ "GenMsgCycleTime" BO_ 1174 100;
BA_ "MessageTimeout" BO_ 1176 0;
BA_ "GenMsgStartDelayTime" BO_ 1176 35;
BA_ "GenMsgCycleTime" BO_ 1176 100;
BA_ "MessageTimeout" BO_ 1177 0;
BA_ "GenMsgCycleTime" BO_ 1177 100;
BA_ "MessageTimeout" BO_ 1178 0;
BA_ "GenMsgStartDelayTime" BO_ 1178 15;
BA_ "GenMsgCycleTime" BO_ 1178 100;
BA_ "MessageTimeout" BO_ 1179 0;
BA_ "GenMsgStartDelayTime" BO_ 1179 20;
BA_ "GenMsgCycleTime" BO_ 1179 100;
BA_ "MessageTimeout" BO_ 1180 0;
BA_ "GenMsgCycleTime" BO_ 1180 100;
BA_ "GenSigSendType" SG_ 1158 EPAS_Invalid_Failure_Status 7;
BA_ "GenSigCycleTimeActive" SG_ 1158 EPAS_Invalid_Failure_Status 100;
BA_ "GenSigCycleTime" SG_ 1158 EPAS_Invalid_Failure_Status 100;
BA_ "GenSigTimeoutTime_HU_B" SG_ 1158 SAS_MTO_Failure_Status 0;
BA_ "GenSigTimeoutTime_HU_A" SG_ 1158 SAS_MTO_Failure_Status 0;
BA_ "GenSigTimeoutMsg_HU_B" SG_ 1158 SAS_MTO_Failure_Status 0;
BA_ "GenSigTimeoutMsg_HU_A" SG_ 1158 SAS_MTO_Failure_Status 0;
BA_ "GenSigSendType" SG_ 1158 SAS_MTO_Failure_Status 7;
BA_ "GenSigCycleTimeActive" SG_ 1158 SAS_MTO_Failure_Status 100;
BA_ "GenSigCycleTime" SG_ 1158 SAS_MTO_Failure_Status 100;
BA_ "GenSigTimeoutTime_HU_B" SG_ 1158 EPAS_MRC_Failure_Status 0;
BA_ "GenSigTimeoutTime_HU_A" SG_ 1158 EPAS_MRC_Failure_Status 0;
BA_ "GenSigTimeoutMsg_HU_B" SG_ 1158 EPAS_MRC_Failure_Status 0;
BA_ "GenSigTimeoutMsg_HU_A" SG_ 1158 EPAS_MRC_Failure_Status 0;
BA_ "GenSigSendType" SG_ 1158 EPAS_MRC_Failure_Status 7;
BA_ "GenSigCycleTimeActive" SG_ 1158 EPAS_MRC_Failure_Status 100;
BA_ "GenSigCycleTime" SG_ 1158 EPAS_MRC_Failure_Status 100;
BA_ "GenSigTimeoutTime_HU_B" SG_ 1158 EPAS_CRC_Failure_Status 0;
BA_ "GenSigTimeoutTime_HU_A" SG_ 1158 EPAS_CRC_Failure_Status 0;
BA_ "GenSigTimeoutMsg_HU_B" SG_ 1158 EPAS_CRC_Failure_Status 0;
BA_ "GenSigTimeoutMsg_HU_A" SG_ 1158 EPAS_CRC_Failure_Status 0;
BA_ "GenSigSendType" SG_ 1158 EPAS_CRC_Failure_Status 7;
BA_ "GenSigCycleTimeActive" SG_ 1158 EPAS_CRC_Failure_Status 100;
BA_ "GenSigCycleTime" SG_ 1158 EPAS_CRC_Failure_Status 100;
BA_ "GenSigTimeoutTime_HU_B" SG_ 1158 EPAS_MTO_Failure_Status 0;
BA_ "GenSigTimeoutTime_HU_A" SG_ 1158 EPAS_MTO_Failure_Status 0;
BA_ "GenSigTimeoutMsg_HU_B" SG_ 1158 EPAS_MTO_Failure_Status 0;
BA_ "GenSigTimeoutMsg_HU_A" SG_ 1158 EPAS_MTO_Failure_Status 0;
BA_ "GenSigSendType" SG_ 1158 EPAS_MTO_Failure_Status 7;
BA_ "GenSigCycleTimeActive" SG_ 1158 EPAS_MTO_Failure_Status 100;
BA_ "GenSigCycleTime" SG_ 1158 EPAS_MTO_Failure_Status 100;
BA_ "GenSigTimeoutTime_HU_B" SG_ 1158 ESP_SW_Version 0;
BA_ "GenSigTimeoutTime_HU_A" SG_ 1158 ESP_SW_Version 0;
BA_ "GenSigTimeoutMsg_HU_B" SG_ 1158 ESP_SW_Version 0;
BA_ "GenSigTimeoutMsg_HU_A" SG_ 1158 ESP_SW_Version 0;
BA_ "GenSigSendType" SG_ 1158 ESP_SW_Version 7;
BA_ "GenSigCycleTimeActive" SG_ 1158 ESP_SW_Version 100;
BA_ "GenSigCycleTime" SG_ 1158 ESP_SW_Version 100;
BA_ "GenSigTimeoutTime_HU_B" SG_ 1158 ESP_Err_State_Trans_Cntr 0;
BA_ "GenSigTimeoutTime_HU_A" SG_ 1158 ESP_Err_State_Trans_Cntr 0;
BA_ "GenSigTimeoutMsg_HU_B" SG_ 1158 ESP_Err_State_Trans_Cntr 0;
BA_ "GenSigTimeoutMsg_HU_A" SG_ 1158 ESP_Err_State_Trans_Cntr 0;
BA_ "GenSigSendType" SG_ 1158 ESP_Err_State_Trans_Cntr 7;
BA_ "GenSigCycleTimeActive" SG_ 1158 ESP_Err_State_Trans_Cntr 100;
BA_ "GenSigCycleTime" SG_ 1158 ESP_Err_State_Trans_Cntr 100;
BA_ "GenSigTimeoutTime_HU_B" SG_ 1158 BattVolt_ESP 0;
BA_ "GenSigTimeoutTime_HU_A" SG_ 1158 BattVolt_ESP 0;
BA_ "GenSigTimeoutMsg_HU_B" SG_ 1158 BattVolt_ESP 0;
BA_ "GenSigTimeoutMsg_HU_A" SG_ 1158 BattVolt_ESP 0;
BA_ "GenSigSendType" SG_ 1158 BattVolt_ESP 7;
BA_ "GenSigCycleTimeActive" SG_ 1158 BattVolt_ESP 100;
BA_ "GenSigCycleTime" SG_ 1158 BattVolt_ESP 100;
BA_ "GenSigTimeoutTime_HU_B" SG_ 1158 ESP_BO_Failure_Status 0;
BA_ "GenSigTimeoutTime_HU_A" SG_ 1158 ESP_BO_Failure_Status 0;
BA_ "GenSigTimeoutMsg_HU_B" SG_ 1158 ESP_BO_Failure_Status 0;
BA_ "GenSigTimeoutMsg_HU_A" SG_ 1158 ESP_BO_Failure_Status 0;
BA_ "GenSigSendType" SG_ 1158 ESP_BO_Failure_Status 7;
BA_ "GenSigCycleTimeActive" SG_ 1158 ESP_BO_Failure_Status 100;
BA_ "GenSigCycleTime" SG_ 1158 ESP_BO_Failure_Status 100;
BA_ "GenSigTimeoutTime_HU_B" SG_ 1158 ESP_EP_Failure_Status 0;
BA_ "GenSigTimeoutTime_HU_A" SG_ 1158 ESP_EP_Failure_Status 0;
BA_ "GenSigTimeoutMsg_HU_B" SG_ 1158 ESP_EP_Failure_Status 0;
BA_ "GenSigTimeoutMsg_HU_A" SG_ 1158 ESP_EP_Failure_Status 0;
BA_ "GenSigSendType" SG_ 1158 ESP_EP_Failure_Status 7;
BA_ "GenSigCycleTimeActive" SG_ 1158 ESP_EP_Failure_Status 100;
BA_ "GenSigCycleTime" SG_ 1158 ESP_EP_Failure_Status 100;
BA_ "GenSigTimeoutTime_HU_B" SG_ 1158 DCS_MTO_Failure_Status 0;
BA_ "GenSigTimeoutTime_HU_A" SG_ 1158 DCS_MTO_Failure_Status 0;
BA_ "GenSigTimeoutMsg_HU_B" SG_ 1158 DCS_MTO_Failure_Status 0;
BA_ "GenSigTimeoutMsg_HU_A" SG_ 1158 DCS_MTO_Failure_Status 0;
BA_ "GenSigSendType" SG_ 1158 DCS_MTO_Failure_Status 7;
BA_ "GenSigCycleTimeActive" SG_ 1158 DCS_MTO_Failure_Status 100;
BA_ "GenSigCycleTime" SG_ 1158 DCS_MTO_Failure_Status 100;
BA_ "GenSigTimeoutTime_HU_B" SG_ 1158 AMT_AT_DCT_MTO_Failure_Status 0;
BA_ "GenSigTimeoutTime_HU_A" SG_ 1158 AMT_AT_DCT_MTO_Failure_Status 0;
BA_ "GenSigTimeoutMsg_HU_B" SG_ 1158 AMT_AT_DCT_MTO_Failure_Status 0;
BA_ "GenSigTimeoutMsg_HU_A" SG_ 1158 AMT_AT_DCT_MTO_Failure_Status 0;
BA_ "GenSigSendType" SG_ 1158 AMT_AT_DCT_MTO_Failure_Status 7;
BA_ "GenSigCycleTimeActive" SG_ 1158 AMT_AT_DCT_MTO_Failure_Status 100;
BA_ "GenSigCycleTime" SG_ 1158 AMT_AT_DCT_MTO_Failure_Status 100;
BA_ "GenSigTimeoutTime_HU_B" SG_ 1158 DCS_Invalid_Failure_Status 0;
BA_ "GenSigTimeoutTime_HU_A" SG_ 1158 DCS_Invalid_Failure_Status 0;
BA_ "GenSigTimeoutMsg_HU_B" SG_ 1158 DCS_Invalid_Failure_Status 0;
BA_ "GenSigTimeoutMsg_HU_A" SG_ 1158 DCS_Invalid_Failure_Status 0;
BA_ "GenSigSendType" SG_ 1158 DCS_Invalid_Failure_Status 7;
BA_ "GenSigCycleTimeActive" SG_ 1158 DCS_Invalid_Failure_Status 100;
BA_ "GenSigCycleTime" SG_ 1158 DCS_Invalid_Failure_Status 100;
BA_ "GenSigTimeoutTime_HU_B" SG_ 1158 AMT_AT_DCT_Invalid_Failure__0000 0;
BA_ "GenSigTimeoutTime_HU_A" SG_ 1158 AMT_AT_DCT_Invalid_Failure__0000 0;
BA_ "GenSigTimeoutMsg_HU_B" SG_ 1158 AMT_AT_DCT_Invalid_Failure__0000 0;
BA_ "GenSigTimeoutMsg_HU_A" SG_ 1158 AMT_AT_DCT_Invalid_Failure__0000 0;
BA_ "GenSigSendType" SG_ 1158 AMT_AT_DCT_Invalid_Failure__0000 7;
BA_ "GenSigCycleTimeActive" SG_ 1158 AMT_AT_DCT_Invalid_Failure__0000 100;
BA_ "GenSigCycleTime" SG_ 1158 AMT_AT_DCT_Invalid_Failure__0000 100;
BA_ "SystemSignalLongSymbol" SG_ 1158 AMT_AT_DCT_Invalid_Failure__0000 "AMT_AT_DCT_Invalid_Failure_Status";
BA_ "GenSigTimeoutTime_HU_B" SG_ 1158 EMsMToFailureStatus 0;
BA_ "GenSigTimeoutTime_HU_A" SG_ 1158 EMsMToFailureStatus 0;
BA_ "GenSigTimeoutMsg_HU_B" SG_ 1158 EMsMToFailureStatus 0;
BA_ "GenSigTimeoutMsg_HU_A" SG_ 1158 EMsMToFailureStatus 0;
BA_ "GenSigSendType" SG_ 1158 EMsMToFailureStatus 7;
BA_ "GenSigCycleTimeActive" SG_ 1158 EMsMToFailureStatus 100;
BA_ "GenSigCycleTime" SG_ 1158 EMsMToFailureStatus 100;
BA_ "GenSigTimeoutTime_HU_B" SG_ 1158 ESClMToFailureStatus 0;
BA_ "GenSigTimeoutTime_HU_A" SG_ 1158 ESClMToFailureStatus 0;
BA_ "GenSigTimeoutMsg_HU_B" SG_ 1158 ESClMToFailureStatus 0;
BA_ "GenSigTimeoutMsg_HU_A" SG_ 1158 ESClMToFailureStatus 0;
BA_ "GenSigSendType" SG_ 1158 ESClMToFailureStatus 7;
BA_ "GenSigCycleTimeActive" SG_ 1158 ESClMToFailureStatus 100;
BA_ "GenSigCycleTime" SG_ 1158 ESClMToFailureStatus 100;
BA_ "GenSigTimeoutTime_HU_B" SG_ 1158 EMsInvalidFailureStatus 0;
BA_ "GenSigTimeoutTime_HU_A" SG_ 1158 EMsInvalidFailureStatus 0;
BA_ "GenSigTimeoutMsg_HU_B" SG_ 1158 EMsInvalidFailureStatus 0;
BA_ "GenSigTimeoutMsg_HU_A" SG_ 1158 EMsInvalidFailureStatus 0;
BA_ "GenSigSendType" SG_ 1158 EMsInvalidFailureStatus 7;
BA_ "GenSigCycleTimeActive" SG_ 1158 EMsInvalidFailureStatus 100;
BA_ "GenSigCycleTime" SG_ 1158 EMsInvalidFailureStatus 100;
BA_ "GenSigTimeoutTime_HU_B" SG_ 1158 BCmMToFailureStatus 0;
BA_ "GenSigTimeoutTime_HU_A" SG_ 1158 BCmMToFailureStatus 0;
BA_ "GenSigTimeoutMsg_HU_B" SG_ 1158 BCmMToFailureStatus 0;
BA_ "GenSigTimeoutMsg_HU_A" SG_ 1158 BCmMToFailureStatus 0;
BA_ "GenSigSendType" SG_ 1158 BCmMToFailureStatus 7;
BA_ "GenSigCycleTimeActive" SG_ 1158 BCmMToFailureStatus 100;
BA_ "GenSigCycleTime" SG_ 1158 BCmMToFailureStatus 100;
BA_ "GenSigTimeoutTime_HU_B" SG_ 1158 BCM_Invalid_Status_Failure 0;
BA_ "GenSigTimeoutTime_HU_A" SG_ 1158 BCM_Invalid_Status_Failure 0;
BA_ "GenSigTimeoutMsg_HU_B" SG_ 1158 BCM_Invalid_Status_Failure 0;
BA_ "GenSigTimeoutMsg_HU_A" SG_ 1158 BCM_Invalid_Status_Failure 0;
BA_ "GenSigSendType" SG_ 1158 BCM_Invalid_Status_Failure 7;
BA_ "GenSigCycleTimeActive" SG_ 1158 BCM_Invalid_Status_Failure 100;
BA_ "GenSigCycleTime" SG_ 1158 BCM_Invalid_Status_Failure 100;
BA_ "GenSigTimeoutTime_HU_B" SG_ 1158 IPcInvalidFailureStatus 0;
BA_ "GenSigTimeoutTime_HU_A" SG_ 1158 IPcInvalidFailureStatus 0;
BA_ "GenSigTimeoutMsg_HU_B" SG_ 1158 IPcInvalidFailureStatus 0;
BA_ "GenSigTimeoutMsg_HU_A" SG_ 1158 IPcInvalidFailureStatus 0;
BA_ "GenSigSendType" SG_ 1158 IPcInvalidFailureStatus 7;
BA_ "GenSigCycleTimeActive" SG_ 1158 IPcInvalidFailureStatus 100;
BA_ "GenSigCycleTime" SG_ 1158 IPcInvalidFailureStatus 100;
BA_ "GenSigTimeoutTime_HU_B" SG_ 1158 IPcMToFailureStatus 0;
BA_ "GenSigTimeoutTime_HU_A" SG_ 1158 IPcMToFailureStatus 0;
BA_ "GenSigTimeoutMsg_HU_B" SG_ 1158 IPcMToFailureStatus 0;
BA_ "GenSigTimeoutMsg_HU_A" SG_ 1158 IPcMToFailureStatus 0;
BA_ "GenSigSendType" SG_ 1158 IPcMToFailureStatus 7;
BA_ "GenSigCycleTimeActive" SG_ 1158 IPcMToFailureStatus 100;
BA_ "GenSigCycleTime" SG_ 1158 IPcMToFailureStatus 100;
BA_ "GenSigTimeoutTime_HU_B" SG_ 1158 EMsCRcFailureStatus 0;
BA_ "GenSigTimeoutTime_HU_A" SG_ 1158 EMsCRcFailureStatus 0;
BA_ "GenSigTimeoutMsg_HU_B" SG_ 1158 EMsCRcFailureStatus 0;
BA_ "GenSigTimeoutMsg_HU_A" SG_ 1158 EMsCRcFailureStatus 0;
BA_ "GenSigSendType" SG_ 1158 EMsCRcFailureStatus 7;
BA_ "GenSigCycleTimeActive" SG_ 1158 EMsCRcFailureStatus 100;
BA_ "GenSigCycleTime" SG_ 1158 EMsCRcFailureStatus 100;
BA_ "GenSigTimeoutTime_HU_B" SG_ 1158 EMsMRcFailureStatus 0;
BA_ "GenSigTimeoutTime_HU_A" SG_ 1158 EMsMRcFailureStatus 0;
BA_ "GenSigTimeoutMsg_HU_B" SG_ 1158 EMsMRcFailureStatus 0;
BA_ "GenSigTimeoutMsg_HU_A" SG_ 1158 EMsMRcFailureStatus 0;
BA_ "GenSigSendType" SG_ 1158 EMsMRcFailureStatus 7;
BA_ "GenSigCycleTimeActive" SG_ 1158 EMsMRcFailureStatus 100;
BA_ "GenSigCycleTime" SG_ 1158 EMsMRcFailureStatus 100;
BA_ "GenSigTimeoutTime_HU_B" SG_ 1159 FCmMToFailureStatus 0;
BA_ "GenSigTimeoutTime_HU_A" SG_ 1159 FCmMToFailureStatus 0;
BA_ "GenSigTimeoutMsg_HU_B" SG_ 1159 FCmMToFailureStatus 0;
BA_ "GenSigTimeoutMsg_HU_A" SG_ 1159 FCmMToFailureStatus 0;
BA_ "GenSigSendType" SG_ 1159 FCmMToFailureStatus 7;
BA_ "GenSigCycleTimeActive" SG_ 1159 FCmMToFailureStatus 100;
BA_ "GenSigCycleTime" SG_ 1159 FCmMToFailureStatus 100;
BA_ "GenSigSendType" SG_ 1159 SRS_MTO_Failure_Status 7;
BA_ "GenSigCycleTimeActive" SG_ 1159 SRS_MTO_Failure_Status 100;
BA_ "GenSigCycleTime" SG_ 1159 SRS_MTO_Failure_Status 100;
BA_ "GenSigTimeoutTime_HU_B" SG_ 1159 BCM_Invalid_Status_Failure 0;
BA_ "GenSigTimeoutTime_HU_A" SG_ 1159 BCM_Invalid_Status_Failure 0;
BA_ "GenSigTimeoutMsg_HU_B" SG_ 1159 BCM_Invalid_Status_Failure 0;
BA_ "GenSigTimeoutMsg_HU_A" SG_ 1159 BCM_Invalid_Status_Failure 0;
BA_ "GenSigSendType" SG_ 1159 BCM_Invalid_Status_Failure 7;
BA_ "GenSigCycleTimeActive" SG_ 1159 BCM_Invalid_Status_Failure 100;
BA_ "GenSigCycleTime" SG_ 1159 BCM_Invalid_Status_Failure 100;
BA_ "GenSigTimeoutTime_HU_B" SG_ 1159 BCM_MTO_Failure_status 0;
BA_ "GenSigTimeoutTime_HU_A" SG_ 1159 BCM_MTO_Failure_status 0;
BA_ "GenSigTimeoutMsg_HU_B" SG_ 1159 BCM_MTO_Failure_status 0;
BA_ "GenSigTimeoutMsg_HU_A" SG_ 1159 BCM_MTO_Failure_status 0;
BA_ "GenSigSendType" SG_ 1159 BCM_MTO_Failure_status 7;
BA_ "GenSigCycleTimeActive" SG_ 1159 BCM_MTO_Failure_status 100;
BA_ "GenSigCycleTime" SG_ 1159 BCM_MTO_Failure_status 100;
BA_ "GenSigTimeoutTime_HU_Mid_X451" SG_ 1159 BattVolt_AT 0;
BA_ "GenSigTimeoutTime_HU_High_X451" SG_ 1159 BattVolt_AT 0;
BA_ "GenSigTimeoutTime_HU_B" SG_ 1159 BattVolt_AT 0;
BA_ "GenSigTimeoutTime_HU_A" SG_ 1159 BattVolt_AT 0;
BA_ "GenSigTimeoutMsg_HU_Mid_X451" SG_ 1159 BattVolt_AT 0;
BA_ "GenSigTimeoutMsg_HU_High_X451" SG_ 1159 BattVolt_AT 0;
BA_ "GenSigTimeoutMsg_HU_B" SG_ 1159 BattVolt_AT 0;
BA_ "GenSigTimeoutMsg_HU_A" SG_ 1159 BattVolt_AT 0;
BA_ "GenSigSendType" SG_ 1159 BattVolt_AT 7;
BA_ "GenSigCycleTimeActive" SG_ 1159 BattVolt_AT 100;
BA_ "GenSigCycleTime" SG_ 1159 BattVolt_AT 100;
BA_ "GenSigTimeoutTime_HU_Mid_X451" SG_ 1159 AT_SW_version 0;
BA_ "GenSigTimeoutTime_HU_High_X451" SG_ 1159 AT_SW_version 0;
BA_ "GenSigTimeoutTime_HU_B" SG_ 1159 AT_SW_version 0;
BA_ "GenSigTimeoutTime_HU_A" SG_ 1159 AT_SW_version 0;
BA_ "GenSigTimeoutMsg_HU_Mid_X451" SG_ 1159 AT_SW_version 0;
BA_ "GenSigTimeoutMsg_HU_High_X451" SG_ 1159 AT_SW_version 0;
BA_ "GenSigTimeoutMsg_HU_B" SG_ 1159 AT_SW_version 0;
BA_ "GenSigTimeoutMsg_HU_A" SG_ 1159 AT_SW_version 0;
BA_ "GenSigSendType" SG_ 1159 AT_SW_version 7;
BA_ "GenSigCycleTimeActive" SG_ 1159 AT_SW_version 100;
BA_ "GenSigCycleTime" SG_ 1159 AT_SW_version 100;
BA_ "GenSigTimeoutTime_HU_Mid_X451" SG_ 1159 EMS_Invalid_Failure_Status 0;
BA_ "GenSigTimeoutTime_HU_High_X451" SG_ 1159 EMS_Invalid_Failure_Status 0;
BA_ "GenSigTimeoutTime_HU_B" SG_ 1159 EMS_Invalid_Failure_Status 0;
BA_ "GenSigTimeoutTime_HU_A" SG_ 1159 EMS_Invalid_Failure_Status 0;
BA_ "GenSigTimeoutMsg_HU_Mid_X451" SG_ 1159 EMS_Invalid_Failure_Status 0;
BA_ "GenSigTimeoutMsg_HU_High_X451" SG_ 1159 EMS_Invalid_Failure_Status 0;
BA_ "GenSigTimeoutMsg_HU_B" SG_ 1159 EMS_Invalid_Failure_Status 0;
BA_ "GenSigTimeoutMsg_HU_A" SG_ 1159 EMS_Invalid_Failure_Status 0;
BA_ "GenSigSendType" SG_ 1159 EMS_Invalid_Failure_Status 7;
BA_ "GenSigCycleTimeActive" SG_ 1159 EMS_Invalid_Failure_Status 100;
BA_ "GenSigCycleTime" SG_ 1159 EMS_Invalid_Failure_Status 100;
BA_ "GenSigTimeoutTime_HU_Mid_X451" SG_ 1159 EMS_MTO_Failure_Status 0;
BA_ "GenSigTimeoutTime_HU_High_X451" SG_ 1159 EMS_MTO_Failure_Status 0;
BA_ "GenSigTimeoutTime_HU_B" SG_ 1159 EMS_MTO_Failure_Status 0;
BA_ "GenSigTimeoutTime_HU_A" SG_ 1159 EMS_MTO_Failure_Status 0;
BA_ "GenSigTimeoutMsg_HU_Mid_X451" SG_ 1159 EMS_MTO_Failure_Status 0;
BA_ "GenSigTimeoutMsg_HU_High_X451" SG_ 1159 EMS_MTO_Failure_Status 0;
BA_ "GenSigTimeoutMsg_HU_B" SG_ 1159 EMS_MTO_Failure_Status 0;
BA_ "GenSigTimeoutMsg_HU_A" SG_ 1159 EMS_MTO_Failure_Status 0;
BA_ "GenSigSendType" SG_ 1159 EMS_MTO_Failure_Status 7;
BA_ "GenSigCycleTimeActive" SG_ 1159 EMS_MTO_Failure_Status 100;
BA_ "GenSigCycleTime" SG_ 1159 EMS_MTO_Failure_Status 100;
BA_ "GenSigTimeoutTime_HU_Mid_X451" SG_ 1159 IPC_Invalid_Failure_Status 0;
BA_ "GenSigTimeoutTime_HU_High_X451" SG_ 1159 IPC_Invalid_Failure_Status 0;
BA_ "GenSigTimeoutTime_HU_B" SG_ 1159 IPC_Invalid_Failure_Status 0;
BA_ "GenSigTimeoutTime_HU_A" SG_ 1159 IPC_Invalid_Failure_Status 0;
BA_ "GenSigTimeoutMsg_HU_Mid_X451" SG_ 1159 IPC_Invalid_Failure_Status 0;
BA_ "GenSigTimeoutMsg_HU_High_X451" SG_ 1159 IPC_Invalid_Failure_Status 0;
BA_ "GenSigTimeoutMsg_HU_B" SG_ 1159 IPC_Invalid_Failure_Status 0;
BA_ "GenSigTimeoutMsg_HU_A" SG_ 1159 IPC_Invalid_Failure_Status 0;
BA_ "GenSigSendType" SG_ 1159 IPC_Invalid_Failure_Status 7;
BA_ "GenSigCycleTimeActive" SG_ 1159 IPC_Invalid_Failure_Status 100;
BA_ "GenSigCycleTime" SG_ 1159 IPC_Invalid_Failure_Status 100;
BA_ "GenSigTimeoutTime_HU_Mid_X451" SG_ 1159 ESP_Invalid_Failure_Status 0;
BA_ "GenSigTimeoutTime_HU_High_X451" SG_ 1159 ESP_Invalid_Failure_Status 0;
BA_ "GenSigTimeoutTime_HU_B" SG_ 1159 ESP_Invalid_Failure_Status 0;
BA_ "GenSigTimeoutTime_HU_A" SG_ 1159 ESP_Invalid_Failure_Status 0;
BA_ "GenSigTimeoutMsg_HU_Mid_X451" SG_ 1159 ESP_Invalid_Failure_Status 0;
BA_ "GenSigTimeoutMsg_HU_High_X451" SG_ 1159 ESP_Invalid_Failure_Status 0;
BA_ "GenSigTimeoutMsg_HU_B" SG_ 1159 ESP_Invalid_Failure_Status 0;
BA_ "GenSigTimeoutMsg_HU_A" SG_ 1159 ESP_Invalid_Failure_Status 0;
BA_ "GenSigSendType" SG_ 1159 ESP_Invalid_Failure_Status 7;
BA_ "GenSigCycleTimeActive" SG_ 1159 ESP_Invalid_Failure_Status 100;
BA_ "GenSigCycleTime" SG_ 1159 ESP_Invalid_Failure_Status 100;
BA_ "GenSigTimeoutTime_HU_Mid_X451" SG_ 1159 AT_BO_Failure_Status 0;
BA_ "GenSigTimeoutTime_HU_High_X451" SG_ 1159 AT_BO_Failure_Status 0;
BA_ "GenSigTimeoutTime_HU_B" SG_ 1159 AT_BO_Failure_Status 0;
BA_ "GenSigTimeoutTime_HU_A" SG_ 1159 AT_BO_Failure_Status 0;
BA_ "GenSigTimeoutMsg_HU_Mid_X451" SG_ 1159 AT_BO_Failure_Status 0;
BA_ "GenSigTimeoutMsg_HU_High_X451" SG_ 1159 AT_BO_Failure_Status 0;
BA_ "GenSigTimeoutMsg_HU_B" SG_ 1159 AT_BO_Failure_Status 0;
BA_ "GenSigTimeoutMsg_HU_A" SG_ 1159 AT_BO_Failure_Status 0;
BA_ "GenSigSendType" SG_ 1159 AT_BO_Failure_Status 7;
BA_ "GenSigCycleTimeActive" SG_ 1159 AT_BO_Failure_Status 100;
BA_ "GenSigCycleTime" SG_ 1159 AT_BO_Failure_Status 100;
BA_ "GenSigTimeoutTime_HU_Mid_X451" SG_ 1159 EMS_MRC_Failure_Status 0;
BA_ "GenSigTimeoutTime_HU_High_X451" SG_ 1159 EMS_MRC_Failure_Status 0;
BA_ "GenSigTimeoutTime_HU_B" SG_ 1159 EMS_MRC_Failure_Status 0;
BA_ "GenSigTimeoutTime_HU_A" SG_ 1159 EMS_MRC_Failure_Status 0;
BA_ "GenSigTimeoutMsg_HU_Mid_X451" SG_ 1159 EMS_MRC_Failure_Status 0;
BA_ "GenSigTimeoutMsg_HU_High_X451" SG_ 1159 EMS_MRC_Failure_Status 0;
BA_ "GenSigTimeoutMsg_HU_B" SG_ 1159 EMS_MRC_Failure_Status 0;
BA_ "GenSigTimeoutMsg_HU_A" SG_ 1159 EMS_MRC_Failure_Status 0;
BA_ "GenSigSendType" SG_ 1159 EMS_MRC_Failure_Status 7;
BA_ "GenSigCycleTimeActive" SG_ 1159 EMS_MRC_Failure_Status 100;
BA_ "GenSigCycleTime" SG_ 1159 EMS_MRC_Failure_Status 100;
BA_ "GenSigTimeoutTime_HU_Mid_X451" SG_ 1159 EMS_CRC_Failure_Status 0;
BA_ "GenSigTimeoutTime_HU_High_X451" SG_ 1159 EMS_CRC_Failure_Status 0;
BA_ "GenSigTimeoutTime_HU_B" SG_ 1159 EMS_CRC_Failure_Status 0;
BA_ "GenSigTimeoutTime_HU_A" SG_ 1159 EMS_CRC_Failure_Status 0;
BA_ "GenSigTimeoutMsg_HU_Mid_X451" SG_ 1159 EMS_CRC_Failure_Status 0;
BA_ "GenSigTimeoutMsg_HU_High_X451" SG_ 1159 EMS_CRC_Failure_Status 0;
BA_ "GenSigTimeoutMsg_HU_B" SG_ 1159 EMS_CRC_Failure_Status 0;
BA_ "GenSigTimeoutMsg_HU_A" SG_ 1159 EMS_CRC_Failure_Status 0;
BA_ "GenSigSendType" SG_ 1159 EMS_CRC_Failure_Status 7;
BA_ "GenSigCycleTimeActive" SG_ 1159 EMS_CRC_Failure_Status 100;
BA_ "GenSigCycleTime" SG_ 1159 EMS_CRC_Failure_Status 100;
BA_ "GenSigTimeoutTime_HU_Mid_X451" SG_ 1159 IPC_MTO_Failure_Status 0;
BA_ "GenSigTimeoutTime_HU_High_X451" SG_ 1159 IPC_MTO_Failure_Status 0;
BA_ "GenSigTimeoutTime_HU_B" SG_ 1159 IPC_MTO_Failure_Status 0;
BA_ "GenSigTimeoutTime_HU_A" SG_ 1159 IPC_MTO_Failure_Status 0;
BA_ "GenSigTimeoutMsg_HU_Mid_X451" SG_ 1159 IPC_MTO_Failure_Status 0;
BA_ "GenSigTimeoutMsg_HU_High_X451" SG_ 1159 IPC_MTO_Failure_Status 0;
BA_ "GenSigTimeoutMsg_HU_B" SG_ 1159 IPC_MTO_Failure_Status 0;
BA_ "GenSigTimeoutMsg_HU_A" SG_ 1159 IPC_MTO_Failure_Status 0;
BA_ "GenSigSendType" SG_ 1159 IPC_MTO_Failure_Status 7;
BA_ "GenSigCycleTimeActive" SG_ 1159 IPC_MTO_Failure_Status 100;
BA_ "GenSigCycleTime" SG_ 1159 IPC_MTO_Failure_Status 100;
BA_ "GenSigTimeoutTime_HU_Mid_X451" SG_ 1159 AT_EP_Failure_Status 0;
BA_ "GenSigTimeoutTime_HU_High_X451" SG_ 1159 AT_EP_Failure_Status 0;
BA_ "GenSigTimeoutTime_HU_B" SG_ 1159 AT_EP_Failure_Status 0;
BA_ "GenSigTimeoutTime_HU_A" SG_ 1159 AT_EP_Failure_Status 0;
BA_ "GenSigTimeoutMsg_HU_Mid_X451" SG_ 1159 AT_EP_Failure_Status 0;
BA_ "GenSigTimeoutMsg_HU_High_X451" SG_ 1159 AT_EP_Failure_Status 0;
BA_ "GenSigTimeoutMsg_HU_B" SG_ 1159 AT_EP_Failure_Status 0;
BA_ "GenSigTimeoutMsg_HU_A" SG_ 1159 AT_EP_Failure_Status 0;
BA_ "GenSigSendType" SG_ 1159 AT_EP_Failure_Status 7;
BA_ "GenSigCycleTimeActive" SG_ 1159 AT_EP_Failure_Status 100;
BA_ "GenSigCycleTime" SG_ 1159 AT_EP_Failure_Status 100;
BA_ "GenSigTimeoutTime_HU_Mid_X451" SG_ 1159 ESP_MTO_Failure_Status 0;
BA_ "GenSigTimeoutTime_HU_High_X451" SG_ 1159 ESP_MTO_Failure_Status 0;
BA_ "GenSigTimeoutTime_HU_B" SG_ 1159 ESP_MTO_Failure_Status 0;
BA_ "GenSigTimeoutTime_HU_A" SG_ 1159 ESP_MTO_Failure_Status 0;
BA_ "GenSigTimeoutMsg_HU_Mid_X451" SG_ 1159 ESP_MTO_Failure_Status 0;
BA_ "GenSigTimeoutMsg_HU_High_X451" SG_ 1159 ESP_MTO_Failure_Status 0;
BA_ "GenSigTimeoutMsg_HU_B" SG_ 1159 ESP_MTO_Failure_Status 0;
BA_ "GenSigTimeoutMsg_HU_A" SG_ 1159 ESP_MTO_Failure_Status 0;
BA_ "GenSigSendType" SG_ 1159 ESP_MTO_Failure_Status 7;
BA_ "GenSigCycleTimeActive" SG_ 1159 ESP_MTO_Failure_Status 100;
BA_ "GenSigCycleTime" SG_ 1159 ESP_MTO_Failure_Status 100;
BA_ "GenSigSendType" SG_ 1160 Telematics_MTO_Failure_status 7;
BA_ "GenSigCycleTimeActive" SG_ 1160 Telematics_MTO_Failure_status 100;
BA_ "GenSigCycleTime" SG_ 1160 Telematics_MTO_Failure_status 100;
BA_ "GenSigSendType" SG_ 1160 Telematics_Invalid_Failure__0001 7;
BA_ "GenSigCycleTimeActive" SG_ 1160 Telematics_Invalid_Failure__0001 100;
BA_ "GenSigCycleTime" SG_ 1160 Telematics_Invalid_Failure__0001 100;
BA_ "SystemSignalLongSymbol" SG_ 1160 Telematics_Invalid_Failure__0001 "Telematics_Invalid_Failure_Status";
BA_ "GenSigTimeoutTime_HU_B" SG_ 1160 BCmMToFailureStatus 0;
BA_ "GenSigTimeoutTime_HU_A" SG_ 1160 BCmMToFailureStatus 0;
BA_ "GenSigTimeoutMsg_HU_B" SG_ 1160 BCmMToFailureStatus 0;
BA_ "GenSigTimeoutMsg_HU_A" SG_ 1160 BCmMToFailureStatus 0;
BA_ "GenSigSendType" SG_ 1160 BCmMToFailureStatus 7;
BA_ "GenSigCycleTimeActive" SG_ 1160 BCmMToFailureStatus 100;
BA_ "GenSigCycleTime" SG_ 1160 BCmMToFailureStatus 100;
BA_ "GenSigTimeoutTime_HU_B" SG_ 1160 BCmInvalidFailureStatus 0;
BA_ "GenSigTimeoutTime_HU_A" SG_ 1160 BCmInvalidFailureStatus 0;
BA_ "GenSigTimeoutMsg_HU_B" SG_ 1160 BCmInvalidFailureStatus 0;
BA_ "GenSigTimeoutMsg_HU_A" SG_ 1160 BCmInvalidFailureStatus 0;
BA_ "GenSigSendType" SG_ 1160 BCmInvalidFailureStatus 7;
BA_ "GenSigCycleTimeActive" SG_ 1160 BCmInvalidFailureStatus 100;
BA_ "GenSigCycleTime" SG_ 1160 BCmInvalidFailureStatus 100;
BA_ "GenSigTimeoutTime_HU_B" SG_ 1160 AMT_DCT_SW_Version 0;
BA_ "GenSigTimeoutTime_HU_A" SG_ 1160 AMT_DCT_SW_Version 0;
BA_ "GenSigTimeoutMsg_HU_B" SG_ 1160 AMT_DCT_SW_Version 0;
BA_ "GenSigTimeoutMsg_HU_A" SG_ 1160 AMT_DCT_SW_Version 0;
BA_ "GenSigSendType" SG_ 1160 AMT_DCT_SW_Version 7;
BA_ "GenSigCycleTimeActive" SG_ 1160 AMT_DCT_SW_Version 100;
BA_ "GenSigCycleTime" SG_ 1160 AMT_DCT_SW_Version 100;
BA_ "GenSigTimeoutTime_HU_B" SG_ 1160 AMT_DCT_HW_Version 0;
BA_ "GenSigTimeoutTime_HU_A" SG_ 1160 AMT_DCT_HW_Version 0;
BA_ "GenSigTimeoutMsg_HU_B" SG_ 1160 AMT_DCT_HW_Version 0;
BA_ "GenSigTimeoutMsg_HU_A" SG_ 1160 AMT_DCT_HW_Version 0;
BA_ "GenSigSendType" SG_ 1160 AMT_DCT_HW_Version 7;
BA_ "GenSigCycleTimeActive" SG_ 1160 AMT_DCT_HW_Version 100;
BA_ "GenSigCycleTime" SG_ 1160 AMT_DCT_HW_Version 100;
BA_ "GenSigTimeoutTime_HU_B" SG_ 1160 DCS_MTO_Failure_Status 0;
BA_ "GenSigTimeoutTime_HU_A" SG_ 1160 DCS_MTO_Failure_Status 0;
BA_ "GenSigTimeoutMsg_HU_B" SG_ 1160 DCS_MTO_Failure_Status 0;
BA_ "GenSigTimeoutMsg_HU_A" SG_ 1160 DCS_MTO_Failure_Status 0;
BA_ "GenSigSendType" SG_ 1160 DCS_MTO_Failure_Status 7;
BA_ "GenSigCycleTimeActive" SG_ 1160 DCS_MTO_Failure_Status 100;
BA_ "GenSigCycleTime" SG_ 1160 DCS_MTO_Failure_Status 100;
BA_ "GenSigTimeoutTime_HU_B" SG_ 1160 DCS_Invalid_Failure_Status 0;
BA_ "GenSigTimeoutTime_HU_A" SG_ 1160 DCS_Invalid_Failure_Status 0;
BA_ "GenSigTimeoutMsg_HU_B" SG_ 1160 DCS_Invalid_Failure_Status 0;
BA_ "GenSigTimeoutMsg_HU_A" SG_ 1160 DCS_Invalid_Failure_Status 0;
BA_ "GenSigSendType" SG_ 1160 DCS_Invalid_Failure_Status 7;
BA_ "GenSigCycleTimeActive" SG_ 1160 DCS_Invalid_Failure_Status 100;
BA_ "GenSigCycleTime" SG_ 1160 DCS_Invalid_Failure_Status 100;
BA_ "GenSigTimeoutTime_HU_B" SG_ 1160 AMT_DCT_EP_Failure_Status 0;
BA_ "GenSigTimeoutTime_HU_A" SG_ 1160 AMT_DCT_EP_Failure_Status 0;
BA_ "GenSigTimeoutMsg_HU_B" SG_ 1160 AMT_DCT_EP_Failure_Status 0;
BA_ "GenSigTimeoutMsg_HU_A" SG_ 1160 AMT_DCT_EP_Failure_Status 0;
BA_ "GenSigSendType" SG_ 1160 AMT_DCT_EP_Failure_Status 7;
BA_ "GenSigCycleTimeActive" SG_ 1160 AMT_DCT_EP_Failure_Status 100;
BA_ "GenSigCycleTime" SG_ 1160 AMT_DCT_EP_Failure_Status 100;
BA_ "GenSigTimeoutTime_HU_B" SG_ 1160 AMT_DCT_BO_Failure_Status 0;
BA_ "GenSigTimeoutTime_HU_A" SG_ 1160 AMT_DCT_BO_Failure_Status 0;
BA_ "GenSigTimeoutMsg_HU_B" SG_ 1160 AMT_DCT_BO_Failure_Status 0;
BA_ "GenSigTimeoutMsg_HU_A" SG_ 1160 AMT_DCT_BO_Failure_Status 0;
BA_ "GenSigSendType" SG_ 1160 AMT_DCT_BO_Failure_Status 7;
BA_ "GenSigCycleTimeActive" SG_ 1160 AMT_DCT_BO_Failure_Status 100;
BA_ "GenSigCycleTime" SG_ 1160 AMT_DCT_BO_Failure_Status 100;
BA_ "GenSigTimeoutTime_HU_B" SG_ 1160 EMsMToFailureStatus 0;
BA_ "GenSigTimeoutTime_HU_A" SG_ 1160 EMsMToFailureStatus 0;
BA_ "GenSigTimeoutMsg_HU_B" SG_ 1160 EMsMToFailureStatus 0;
BA_ "GenSigTimeoutMsg_HU_A" SG_ 1160 EMsMToFailureStatus 0;
BA_ "GenSigSendType" SG_ 1160 EMsMToFailureStatus 7;
BA_ "GenSigCycleTimeActive" SG_ 1160 EMsMToFailureStatus 100;
BA_ "GenSigCycleTime" SG_ 1160 EMsMToFailureStatus 100;
BA_ "GenSigTimeoutTime_HU_B" SG_ 1160 EMsInvalidFailureStatus 0;
BA_ "GenSigTimeoutTime_HU_A" SG_ 1160 EMsInvalidFailureStatus 0;
BA_ "GenSigTimeoutMsg_HU_B" SG_ 1160 EMsInvalidFailureStatus 0;
BA_ "GenSigTimeoutMsg_HU_A" SG_ 1160 EMsInvalidFailureStatus 0;
BA_ "GenSigSendType" SG_ 1160 EMsInvalidFailureStatus 7;
BA_ "GenSigCycleTimeActive" SG_ 1160 EMsInvalidFailureStatus 100;
BA_ "GenSigCycleTime" SG_ 1160 EMsInvalidFailureStatus 100;
BA_ "GenSigTimeoutTime_HU_B" SG_ 1160 BattVolt_TCU 0;
BA_ "GenSigTimeoutTime_HU_A" SG_ 1160 BattVolt_TCU 0;
BA_ "GenSigTimeoutMsg_HU_B" SG_ 1160 BattVolt_TCU 0;
BA_ "GenSigTimeoutMsg_HU_A" SG_ 1160 BattVolt_TCU 0;
BA_ "GenSigSendType" SG_ 1160 BattVolt_TCU 7;
BA_ "GenSigCycleTimeActive" SG_ 1160 BattVolt_TCU 100;
BA_ "GenSigCycleTime" SG_ 1160 BattVolt_TCU 100;
BA_ "GenSigTimeoutTime_HU_B" SG_ 1160 IPC_MRC_failure_status 0;
BA_ "GenSigTimeoutTime_HU_A" SG_ 1160 IPC_MRC_failure_status 0;
BA_ "GenSigTimeoutMsg_HU_B" SG_ 1160 IPC_MRC_failure_status 0;
BA_ "GenSigTimeoutMsg_HU_A" SG_ 1160 IPC_MRC_failure_status 0;
BA_ "GenSigSendType" SG_ 1160 IPC_MRC_failure_status 7;
BA_ "GenSigCycleTimeActive" SG_ 1160 IPC_MRC_failure_status 100;
BA_ "GenSigCycleTime" SG_ 1160 IPC_MRC_failure_status 100;
BA_ "GenSigTimeoutTime_HU_B" SG_ 1160 IPcMToFailureStatus 0;
BA_ "GenSigTimeoutTime_HU_A" SG_ 1160 IPcMToFailureStatus 0;
BA_ "GenSigTimeoutMsg_HU_B" SG_ 1160 IPcMToFailureStatus 0;
BA_ "GenSigTimeoutMsg_HU_A" SG_ 1160 IPcMToFailureStatus 0;
BA_ "GenSigSendType" SG_ 1160 IPcMToFailureStatus 7;
BA_ "GenSigCycleTimeActive" SG_ 1160 IPcMToFailureStatus 100;
BA_ "GenSigCycleTime" SG_ 1160 IPcMToFailureStatus 100;
BA_ "GenSigTimeoutTime_HU_B" SG_ 1160 IPcInvalidFailureStatus 0;
BA_ "GenSigTimeoutTime_HU_A" SG_ 1160 IPcInvalidFailureStatus 0;
BA_ "GenSigTimeoutMsg_HU_B" SG_ 1160 IPcInvalidFailureStatus 0;
BA_ "GenSigTimeoutMsg_HU_A" SG_ 1160 IPcInvalidFailureStatus 0;
BA_ "GenSigSendType" SG_ 1160 IPcInvalidFailureStatus 7;
BA_ "GenSigCycleTimeActive" SG_ 1160 IPcInvalidFailureStatus 100;
BA_ "GenSigCycleTime" SG_ 1160 IPcInvalidFailureStatus 100;
BA_ "GenSigTimeoutTime_HU_B" SG_ 1160 ESP_Invalid_Failure_Status 0;
BA_ "GenSigTimeoutTime_HU_A" SG_ 1160 ESP_Invalid_Failure_Status 0;
BA_ "GenSigTimeoutMsg_HU_B" SG_ 1160 ESP_Invalid_Failure_Status 0;
BA_ "GenSigTimeoutMsg_HU_A" SG_ 1160 ESP_Invalid_Failure_Status 0;
BA_ "GenSigSendType" SG_ 1160 ESP_Invalid_Failure_Status 7;
BA_ "GenSigCycleTimeActive" SG_ 1160 ESP_Invalid_Failure_Status 100;
BA_ "GenSigCycleTime" SG_ 1160 ESP_Invalid_Failure_Status 100;
BA_ "GenSigTimeoutTime_HU_B" SG_ 1160 EMsMRcFailureStatus 0;
BA_ "GenSigTimeoutTime_HU_A" SG_ 1160 EMsMRcFailureStatus 0;
BA_ "GenSigTimeoutMsg_HU_B" SG_ 1160 EMsMRcFailureStatus 0;
BA_ "GenSigTimeoutMsg_HU_A" SG_ 1160 EMsMRcFailureStatus 0;
BA_ "GenSigSendType" SG_ 1160 EMsMRcFailureStatus 7;
BA_ "GenSigCycleTimeActive" SG_ 1160 EMsMRcFailureStatus 100;
BA_ "GenSigCycleTime" SG_ 1160 EMsMRcFailureStatus 100;
BA_ "GenSigTimeoutTime_HU_B" SG_ 1160 EMsCRcFailureStatus 0;
BA_ "GenSigTimeoutTime_HU_A" SG_ 1160 EMsCRcFailureStatus 0;
BA_ "GenSigTimeoutMsg_HU_B" SG_ 1160 EMsCRcFailureStatus 0;
BA_ "GenSigTimeoutMsg_HU_A" SG_ 1160 EMsCRcFailureStatus 0;
BA_ "GenSigSendType" SG_ 1160 EMsCRcFailureStatus 7;
BA_ "GenSigCycleTimeActive" SG_ 1160 EMsCRcFailureStatus 100;
BA_ "GenSigCycleTime" SG_ 1160 EMsCRcFailureStatus 100;
BA_ "GenSigTimeoutTime_HU_B" SG_ 1160 IPC_CRC_failure_status 0;
BA_ "GenSigTimeoutTime_HU_A" SG_ 1160 IPC_CRC_failure_status 0;
BA_ "GenSigTimeoutMsg_HU_B" SG_ 1160 IPC_CRC_failure_status 0;
BA_ "GenSigTimeoutMsg_HU_A" SG_ 1160 IPC_CRC_failure_status 0;
BA_ "GenSigSendType" SG_ 1160 IPC_CRC_failure_status 7;
BA_ "GenSigCycleTimeActive" SG_ 1160 IPC_CRC_failure_status 100;
BA_ "GenSigCycleTime" SG_ 1160 IPC_CRC_failure_status 100;
BA_ "GenSigTimeoutTime_HU_B" SG_ 1160 ESpMToFailureStatus 0;
BA_ "GenSigTimeoutTime_HU_A" SG_ 1160 ESpMToFailureStatus 0;
BA_ "GenSigTimeoutMsg_HU_B" SG_ 1160 ESpMToFailureStatus 0;
BA_ "GenSigTimeoutMsg_HU_A" SG_ 1160 ESpMToFailureStatus 0;
BA_ "GenSigSendType" SG_ 1160 ESpMToFailureStatus 7;
BA_ "GenSigCycleTimeActive" SG_ 1160 ESpMToFailureStatus 100;
BA_ "GenSigCycleTime" SG_ 1160 ESpMToFailureStatus 100;
BA_ "GenSigSendType" SG_ 1161 Telematics_MTO_Failure_status 7;
BA_ "GenSigCycleTimeActive" SG_ 1161 Telematics_MTO_Failure_status 100;
BA_ "GenSigCycleTime" SG_ 1161 Telematics_MTO_Failure_status 100;
BA_ "GenSigSendType" SG_ 1161 Telematics_Invalid_Failure__0002 7;
BA_ "GenSigCycleTimeActive" SG_ 1161 Telematics_Invalid_Failure__0002 100;
BA_ "GenSigCycleTime" SG_ 1161 Telematics_Invalid_Failure__0002 100;
BA_ "SystemSignalLongSymbol" SG_ 1161 Telematics_Invalid_Failure__0002 "Telematics_Invalid_Failure_Status";
BA_ "GenSigTimeoutTime_HU_B" SG_ 1161 BCmInvalidFailureStatus 0;
BA_ "GenSigTimeoutTime_HU_A" SG_ 1161 BCmInvalidFailureStatus 0;
BA_ "GenSigTimeoutMsg_HU_B" SG_ 1161 BCmInvalidFailureStatus 0;
BA_ "GenSigTimeoutMsg_HU_A" SG_ 1161 BCmInvalidFailureStatus 0;
BA_ "GenSigSendType" SG_ 1161 BCmInvalidFailureStatus 7;
BA_ "GenSigCycleTimeActive" SG_ 1161 BCmInvalidFailureStatus 100;
BA_ "GenSigCycleTime" SG_ 1161 BCmInvalidFailureStatus 100;
BA_ "GenSigTimeoutTime_HU_B" SG_ 1161 DCT_SW_Version 0;
BA_ "GenSigTimeoutTime_HU_A" SG_ 1161 DCT_SW_Version 0;
BA_ "GenSigTimeoutMsg_HU_B" SG_ 1161 DCT_SW_Version 0;
BA_ "GenSigTimeoutMsg_HU_A" SG_ 1161 DCT_SW_Version 0;
BA_ "GenSigSendType" SG_ 1161 DCT_SW_Version 7;
BA_ "GenSigCycleTimeActive" SG_ 1161 DCT_SW_Version 100;
BA_ "GenSigCycleTime" SG_ 1161 DCT_SW_Version 100;
BA_ "GenSigTimeoutTime_HU_B" SG_ 1161 BattVolt_DCT 0;
BA_ "GenSigTimeoutTime_HU_A" SG_ 1161 BattVolt_DCT 0;
BA_ "GenSigTimeoutMsg_HU_B" SG_ 1161 BattVolt_DCT 0;
BA_ "GenSigTimeoutMsg_HU_A" SG_ 1161 BattVolt_DCT 0;
BA_ "GenSigSendType" SG_ 1161 BattVolt_DCT 7;
BA_ "GenSigCycleTimeActive" SG_ 1161 BattVolt_DCT 100;
BA_ "GenSigCycleTime" SG_ 1161 BattVolt_DCT 100;
BA_ "GenSigTimeoutTime_HU_B" SG_ 1161 EMsCRcFailureStatus 0;
BA_ "GenSigTimeoutTime_HU_A" SG_ 1161 EMsCRcFailureStatus 0;
BA_ "GenSigTimeoutMsg_HU_B" SG_ 1161 EMsCRcFailureStatus 0;
BA_ "GenSigTimeoutMsg_HU_A" SG_ 1161 EMsCRcFailureStatus 0;
BA_ "GenSigSendType" SG_ 1161 EMsCRcFailureStatus 7;
BA_ "GenSigCycleTimeActive" SG_ 1161 EMsCRcFailureStatus 100;
BA_ "GenSigCycleTime" SG_ 1161 EMsCRcFailureStatus 100;
BA_ "GenSigTimeoutTime_HU_B" SG_ 1161 ESpMToFailureStatus 0;
BA_ "GenSigTimeoutTime_HU_A" SG_ 1161 ESpMToFailureStatus 0;
BA_ "GenSigTimeoutMsg_HU_B" SG_ 1161 ESpMToFailureStatus 0;
BA_ "GenSigTimeoutMsg_HU_A" SG_ 1161 ESpMToFailureStatus 0;
BA_ "GenSigSendType" SG_ 1161 ESpMToFailureStatus 7;
BA_ "GenSigCycleTimeActive" SG_ 1161 ESpMToFailureStatus 100;
BA_ "GenSigCycleTime" SG_ 1161 ESpMToFailureStatus 100;
BA_ "GenSigTimeoutTime_HU_B" SG_ 1161 ESpInvalidFailureStatus 0;
BA_ "GenSigTimeoutTime_HU_A" SG_ 1161 ESpInvalidFailureStatus 0;
BA_ "GenSigTimeoutMsg_HU_B" SG_ 1161 ESpInvalidFailureStatus 0;
BA_ "GenSigTimeoutMsg_HU_A" SG_ 1161 ESpInvalidFailureStatus 0;
BA_ "GenSigSendType" SG_ 1161 ESpInvalidFailureStatus 7;
BA_ "GenSigCycleTimeActive" SG_ 1161 ESpInvalidFailureStatus 100;
BA_ "GenSigCycleTime" SG_ 1161 ESpInvalidFailureStatus 100;
BA_ "GenSigTimeoutTime_HU_B" SG_ 1161 BCmMToFailureStatus 0;
BA_ "GenSigTimeoutTime_HU_A" SG_ 1161 BCmMToFailureStatus 0;
BA_ "GenSigTimeoutMsg_HU_B" SG_ 1161 BCmMToFailureStatus 0;
BA_ "GenSigTimeoutMsg_HU_A" SG_ 1161 BCmMToFailureStatus 0;
BA_ "GenSigSendType" SG_ 1161 BCmMToFailureStatus 7;
BA_ "GenSigCycleTimeActive" SG_ 1161 BCmMToFailureStatus 100;
BA_ "GenSigCycleTime" SG_ 1161 BCmMToFailureStatus 100;
BA_ "GenSigTimeoutTime_HU_B" SG_ 1161 IPcInvalidFailureStatus 0;
BA_ "GenSigTimeoutTime_HU_A" SG_ 1161 IPcInvalidFailureStatus 0;
BA_ "GenSigTimeoutMsg_HU_B" SG_ 1161 IPcInvalidFailureStatus 0;
BA_ "GenSigTimeoutMsg_HU_A" SG_ 1161 IPcInvalidFailureStatus 0;
BA_ "GenSigSendType" SG_ 1161 IPcInvalidFailureStatus 7;
BA_ "GenSigCycleTimeActive" SG_ 1161 IPcInvalidFailureStatus 100;
BA_ "GenSigCycleTime" SG_ 1161 IPcInvalidFailureStatus 100;
BA_ "GenSigTimeoutTime_HU_B" SG_ 1161 EMsMToFailureStatus 0;
BA_ "GenSigTimeoutTime_HU_A" SG_ 1161 EMsMToFailureStatus 0;
BA_ "GenSigTimeoutMsg_HU_B" SG_ 1161 EMsMToFailureStatus 0;
BA_ "GenSigTimeoutMsg_HU_A" SG_ 1161 EMsMToFailureStatus 0;
BA_ "GenSigSendType" SG_ 1161 EMsMToFailureStatus 7;
BA_ "GenSigCycleTimeActive" SG_ 1161 EMsMToFailureStatus 100;
BA_ "GenSigCycleTime" SG_ 1161 EMsMToFailureStatus 100;
BA_ "GenSigTimeoutTime_HU_B" SG_ 1161 EMsMRcFailureStatus 0;
BA_ "GenSigTimeoutTime_HU_A" SG_ 1161 EMsMRcFailureStatus 0;
BA_ "GenSigTimeoutMsg_HU_B" SG_ 1161 EMsMRcFailureStatus 0;
BA_ "GenSigTimeoutMsg_HU_A" SG_ 1161 EMsMRcFailureStatus 0;
BA_ "GenSigSendType" SG_ 1161 EMsMRcFailureStatus 7;
BA_ "GenSigCycleTimeActive" SG_ 1161 EMsMRcFailureStatus 100;
BA_ "GenSigCycleTime" SG_ 1161 EMsMRcFailureStatus 100;
BA_ "GenSigTimeoutTime_HU_B" SG_ 1161 EMsInvalidFailureStatus 0;
BA_ "GenSigTimeoutTime_HU_A" SG_ 1161 EMsInvalidFailureStatus 0;
BA_ "GenSigTimeoutMsg_HU_B" SG_ 1161 EMsInvalidFailureStatus 0;
BA_ "GenSigTimeoutMsg_HU_A" SG_ 1161 EMsInvalidFailureStatus 0;
BA_ "GenSigSendType" SG_ 1161 EMsInvalidFailureStatus 7;
BA_ "GenSigCycleTimeActive" SG_ 1161 EMsInvalidFailureStatus 100;
BA_ "GenSigCycleTime" SG_ 1161 EMsInvalidFailureStatus 100;
BA_ "GenSigTimeoutTime_HU_B" SG_ 1161 IPC_MRC_failure_status 0;
BA_ "GenSigTimeoutTime_HU_A" SG_ 1161 IPC_MRC_failure_status 0;
BA_ "GenSigTimeoutMsg_HU_B" SG_ 1161 IPC_MRC_failure_status 0;
BA_ "GenSigTimeoutMsg_HU_A" SG_ 1161 IPC_MRC_failure_status 0;
BA_ "GenSigSendType" SG_ 1161 IPC_MRC_failure_status 7;
BA_ "GenSigCycleTimeActive" SG_ 1161 IPC_MRC_failure_status 100;
BA_ "GenSigCycleTime" SG_ 1161 IPC_MRC_failure_status 100;
BA_ "GenSigTimeoutTime_HU_B" SG_ 1161 IPC_CRC_failure_status 0;
BA_ "GenSigTimeoutTime_HU_A" SG_ 1161 IPC_CRC_failure_status 0;
BA_ "GenSigTimeoutMsg_HU_B" SG_ 1161 IPC_CRC_failure_status 0;
BA_ "GenSigTimeoutMsg_HU_A" SG_ 1161 IPC_CRC_failure_status 0;
BA_ "GenSigSendType" SG_ 1161 IPC_CRC_failure_status 7;
BA_ "GenSigCycleTimeActive" SG_ 1161 IPC_CRC_failure_status 100;
BA_ "GenSigCycleTime" SG_ 1161 IPC_CRC_failure_status 100;
BA_ "GenSigTimeoutTime_HU_B" SG_ 1161 IPcMToFailureStatus 0;
BA_ "GenSigTimeoutTime_HU_A" SG_ 1161 IPcMToFailureStatus 0;
BA_ "GenSigTimeoutMsg_HU_B" SG_ 1161 IPcMToFailureStatus 0;
BA_ "GenSigTimeoutMsg_HU_A" SG_ 1161 IPcMToFailureStatus 0;
BA_ "GenSigSendType" SG_ 1161 IPcMToFailureStatus 7;
BA_ "GenSigCycleTimeActive" SG_ 1161 IPcMToFailureStatus 100;
BA_ "GenSigCycleTime" SG_ 1161 IPcMToFailureStatus 100;
BA_ "GenSigTimeoutTime_HU_B" SG_ 1162 VICM_HW_Version 0;
BA_ "GenSigTimeoutTime_HU_A" SG_ 1162 VICM_HW_Version 0;
BA_ "GenSigTimeoutMsg_HU_B" SG_ 1162 VICM_HW_Version 0;
BA_ "GenSigTimeoutMsg_HU_A" SG_ 1162 VICM_HW_Version 0;
BA_ "GenSigSendType" SG_ 1162 VICM_HW_Version 7;
BA_ "GenSigCycleTimeActive" SG_ 1162 VICM_HW_Version 100;
BA_ "GenSigCycleTime" SG_ 1162 VICM_HW_Version 100;
BA_ "GenSigTimeoutTime_HU_B" SG_ 1162 VICM_SW_Version 0;
BA_ "GenSigTimeoutTime_HU_A" SG_ 1162 VICM_SW_Version 0;
BA_ "GenSigTimeoutMsg_HU_B" SG_ 1162 VICM_SW_Version 0;
BA_ "GenSigTimeoutMsg_HU_A" SG_ 1162 VICM_SW_Version 0;
BA_ "GenSigSendType" SG_ 1162 VICM_SW_Version 7;
BA_ "GenSigCycleTimeActive" SG_ 1162 VICM_SW_Version 100;
BA_ "GenSigCycleTime" SG_ 1162 VICM_SW_Version 100;
BA_ "GenSigTimeoutTime_HU_B" SG_ 1162 VICM_Err_State_Trans_Cntr 0;
BA_ "GenSigTimeoutTime_HU_A" SG_ 1162 VICM_Err_State_Trans_Cntr 0;
BA_ "GenSigTimeoutMsg_HU_B" SG_ 1162 VICM_Err_State_Trans_Cntr 0;
BA_ "GenSigTimeoutMsg_HU_A" SG_ 1162 VICM_Err_State_Trans_Cntr 0;
BA_ "GenSigSendType" SG_ 1162 VICM_Err_State_Trans_Cntr 7;
BA_ "GenSigCycleTimeActive" SG_ 1162 VICM_Err_State_Trans_Cntr 100;
BA_ "GenSigCycleTime" SG_ 1162 VICM_Err_State_Trans_Cntr 100;
BA_ "GenSigTimeoutTime_HU_B" SG_ 1162 BattVolt_VICM 0;
BA_ "GenSigTimeoutTime_HU_A" SG_ 1162 BattVolt_VICM 0;
BA_ "GenSigTimeoutMsg_HU_B" SG_ 1162 BattVolt_VICM 0;
BA_ "GenSigTimeoutMsg_HU_A" SG_ 1162 BattVolt_VICM 0;
BA_ "GenSigSendType" SG_ 1162 BattVolt_VICM 7;
BA_ "GenSigCycleTimeActive" SG_ 1162 BattVolt_VICM 100;
BA_ "GenSigCycleTime" SG_ 1162 BattVolt_VICM 100;
BA_ "GenSigTimeoutTime_HU_B" SG_ 1162 VICM_BO_Failure_Status 0;
BA_ "GenSigTimeoutTime_HU_A" SG_ 1162 VICM_BO_Failure_Status 0;
BA_ "GenSigTimeoutMsg_HU_B" SG_ 1162 VICM_BO_Failure_Status 0;
BA_ "GenSigTimeoutMsg_HU_A" SG_ 1162 VICM_BO_Failure_Status 0;
BA_ "GenSigSendType" SG_ 1162 VICM_BO_Failure_Status 7;
BA_ "GenSigCycleTimeActive" SG_ 1162 VICM_BO_Failure_Status 100;
BA_ "GenSigCycleTime" SG_ 1162 VICM_BO_Failure_Status 100;
BA_ "GenSigTimeoutTime_HU_B" SG_ 1162 VICM_EP_Failure_Status 0;
BA_ "GenSigTimeoutTime_HU_A" SG_ 1162 VICM_EP_Failure_Status 0;
BA_ "GenSigTimeoutMsg_HU_B" SG_ 1162 VICM_EP_Failure_Status 0;
BA_ "GenSigTimeoutMsg_HU_A" SG_ 1162 VICM_EP_Failure_Status 0;
BA_ "GenSigSendType" SG_ 1162 VICM_EP_Failure_Status 7;
BA_ "GenSigCycleTimeActive" SG_ 1162 VICM_EP_Failure_Status 100;
BA_ "GenSigCycleTime" SG_ 1162 VICM_EP_Failure_Status 100;
BA_ "GenSigTimeoutTime_HU_B" SG_ 1162 EMS_MM_Failure_Status 0;
BA_ "GenSigTimeoutTime_HU_A" SG_ 1162 EMS_MM_Failure_Status 0;
BA_ "GenSigTimeoutMsg_HU_B" SG_ 1162 EMS_MM_Failure_Status 0;
BA_ "GenSigTimeoutMsg_HU_A" SG_ 1162 EMS_MM_Failure_Status 0;
BA_ "GenSigSendType" SG_ 1162 EMS_MM_Failure_Status 7;
BA_ "GenSigCycleTimeActive" SG_ 1162 EMS_MM_Failure_Status 100;
BA_ "GenSigCycleTime" SG_ 1162 EMS_MM_Failure_Status 100;
BA_ "GenSigTimeoutTime_HU_B" SG_ 1162 EMsMToFailureStatus 0;
BA_ "GenSigTimeoutTime_HU_A" SG_ 1162 EMsMToFailureStatus 0;
BA_ "GenSigTimeoutMsg_HU_B" SG_ 1162 EMsMToFailureStatus 0;
BA_ "GenSigTimeoutMsg_HU_A" SG_ 1162 EMsMToFailureStatus 0;
BA_ "GenSigSendType" SG_ 1162 EMsMToFailureStatus 7;
BA_ "GenSigCycleTimeActive" SG_ 1162 EMsMToFailureStatus 100;
BA_ "GenSigCycleTime" SG_ 1162 EMsMToFailureStatus 100;
BA_ "GenSigSendType" SG_ 1164 FCmInvalidFailureStatus 7;
BA_ "GenSigCycleTimeActive" SG_ 1164 FCmInvalidFailureStatus 100;
BA_ "GenSigCycleTime" SG_ 1164 FCmInvalidFailureStatus 100;
BA_ "GenSigSendType" SG_ 1164 FCmMToFailureStatus 7;
BA_ "GenSigCycleTimeActive" SG_ 1164 FCmMToFailureStatus 100;
BA_ "GenSigCycleTime" SG_ 1164 FCmMToFailureStatus 100;
BA_ "GenSigSendType" SG_ 1164 VCUMToFailureStatus 7;
BA_ "GenSigCycleTimeActive" SG_ 1164 VCUMToFailureStatus 100;
BA_ "GenSigCycleTime" SG_ 1164 VCUMToFailureStatus 100;
BA_ "GenSigSendType" SG_ 1164 VCUInvalidFailureStatus 7;
BA_ "GenSigCycleTimeActive" SG_ 1164 VCUInvalidFailureStatus 100;
BA_ "GenSigCycleTime" SG_ 1164 VCUInvalidFailureStatus 100;
BA_ "GenSigSendType" SG_ 1164 EMsMToFailureStatus 7;
BA_ "GenSigCycleTimeActive" SG_ 1164 EMsMToFailureStatus 100;
BA_ "GenSigCycleTime" SG_ 1164 EMsMToFailureStatus 100;
BA_ "GenSigSendType" SG_ 1164 EMsInvalidFailureStatus 7;
BA_ "GenSigCycleTimeActive" SG_ 1164 EMsInvalidFailureStatus 100;
BA_ "GenSigCycleTime" SG_ 1164 EMsInvalidFailureStatus 100;
BA_ "GenSigSendType" SG_ 1164 ESP_MTO_Failure_Status 7;
BA_ "GenSigCycleTimeActive" SG_ 1164 ESP_MTO_Failure_Status 100;
BA_ "GenSigCycleTime" SG_ 1164 ESP_MTO_Failure_Status 100;
BA_ "GenSigSendType" SG_ 1164 ESP_Invalid_Failure_Status 7;
BA_ "GenSigCycleTimeActive" SG_ 1164 ESP_Invalid_Failure_Status 100;
BA_ "GenSigCycleTime" SG_ 1164 ESP_Invalid_Failure_Status 100;
BA_ "GenSigSendType" SG_ 1164 SRS_SW_Version 7;
BA_ "GenSigCycleTimeActive" SG_ 1164 SRS_SW_Version 100;
BA_ "GenSigCycleTime" SG_ 1164 SRS_SW_Version 100;
BA_ "GenSigSendType" SG_ 1164 BattVolt_SRS 7;
BA_ "GenSigCycleTimeActive" SG_ 1164 BattVolt_SRS 100;
BA_ "GenSigCycleTime" SG_ 1164 BattVolt_SRS 100;
BA_ "GenSigSendType" SG_ 1164 SRS_BO_Failure_Status 7;
BA_ "GenSigCycleTimeActive" SG_ 1164 SRS_BO_Failure_Status 100;
BA_ "GenSigCycleTime" SG_ 1164 SRS_BO_Failure_Status 100;
BA_ "GenSigSendType" SG_ 1164 SRS_EP_Failure_Status 7;
BA_ "GenSigCycleTimeActive" SG_ 1164 SRS_EP_Failure_Status 100;
BA_ "GenSigCycleTime" SG_ 1164 SRS_EP_Failure_Status 100;
BA_ "GenSigSendType" SG_ 1164 IPcMToFailureStatus 7;
BA_ "GenSigCycleTimeActive" SG_ 1164 IPcMToFailureStatus 100;
BA_ "GenSigCycleTime" SG_ 1164 IPcMToFailureStatus 100;
BA_ "GenSigSendType" SG_ 1164 IPcInvalidFailureStatus 7;
BA_ "GenSigCycleTimeActive" SG_ 1164 IPcInvalidFailureStatus 100;
BA_ "GenSigCycleTime" SG_ 1164 IPcInvalidFailureStatus 100;
BA_ "GenSigSendType" SG_ 1164 BCmMToFailureStatus 7;
BA_ "GenSigCycleTimeActive" SG_ 1164 BCmMToFailureStatus 100;
BA_ "GenSigCycleTime" SG_ 1164 BCmMToFailureStatus 100;
BA_ "GenSigTimeoutTime_HU_B" SG_ 1167 EEM_HW_Version 0;
BA_ "GenSigTimeoutTime_HU_A" SG_ 1167 EEM_HW_Version 0;
BA_ "GenSigTimeoutMsg_HU_B" SG_ 1167 EEM_HW_Version 0;
BA_ "GenSigTimeoutMsg_HU_A" SG_ 1167 EEM_HW_Version 0;
BA_ "GenSigSendType" SG_ 1167 EEM_HW_Version 7;
BA_ "GenSigCycleTimeActive" SG_ 1167 EEM_HW_Version 100;
BA_ "GenSigCycleTime" SG_ 1167 EEM_HW_Version 100;
BA_ "GenSigTimeoutTime_HU_B" SG_ 1167 EEM_SW_Version 0;
BA_ "GenSigTimeoutTime_HU_A" SG_ 1167 EEM_SW_Version 0;
BA_ "GenSigTimeoutMsg_HU_B" SG_ 1167 EEM_SW_Version 0;
BA_ "GenSigTimeoutMsg_HU_A" SG_ 1167 EEM_SW_Version 0;
BA_ "GenSigSendType" SG_ 1167 EEM_SW_Version 7;
BA_ "GenSigCycleTimeActive" SG_ 1167 EEM_SW_Version 100;
BA_ "GenSigCycleTime" SG_ 1167 EEM_SW_Version 100;
BA_ "GenSigTimeoutTime_HU_B" SG_ 1167 EEM_Err_State_Trans_Cntr 0;
BA_ "GenSigTimeoutTime_HU_A" SG_ 1167 EEM_Err_State_Trans_Cntr 0;
BA_ "GenSigTimeoutMsg_HU_B" SG_ 1167 EEM_Err_State_Trans_Cntr 0;
BA_ "GenSigTimeoutMsg_HU_A" SG_ 1167 EEM_Err_State_Trans_Cntr 0;
BA_ "GenSigSendType" SG_ 1167 EEM_Err_State_Trans_Cntr 7;
BA_ "GenSigCycleTimeActive" SG_ 1167 EEM_Err_State_Trans_Cntr 100;
BA_ "GenSigCycleTime" SG_ 1167 EEM_Err_State_Trans_Cntr 100;
BA_ "GenSigTimeoutTime_HU_B" SG_ 1167 BattVolt_EEM 0;
BA_ "GenSigTimeoutTime_HU_A" SG_ 1167 BattVolt_EEM 0;
BA_ "GenSigTimeoutMsg_HU_B" SG_ 1167 BattVolt_EEM 0;
BA_ "GenSigTimeoutMsg_HU_A" SG_ 1167 BattVolt_EEM 0;
BA_ "GenSigSendType" SG_ 1167 BattVolt_EEM 7;
BA_ "GenSigCycleTimeActive" SG_ 1167 BattVolt_EEM 100;
BA_ "GenSigCycleTime" SG_ 1167 BattVolt_EEM 100;
BA_ "GenSigTimeoutTime_HU_B" SG_ 1167 EEM_BO_Failure_Status 0;
BA_ "GenSigTimeoutTime_HU_A" SG_ 1167 EEM_BO_Failure_Status 0;
BA_ "GenSigTimeoutMsg_HU_B" SG_ 1167 EEM_BO_Failure_Status 0;
BA_ "GenSigTimeoutMsg_HU_A" SG_ 1167 EEM_BO_Failure_Status 0;
BA_ "GenSigSendType" SG_ 1167 EEM_BO_Failure_Status 7;
BA_ "GenSigCycleTimeActive" SG_ 1167 EEM_BO_Failure_Status 100;
BA_ "GenSigCycleTime" SG_ 1167 EEM_BO_Failure_Status 100;
BA_ "GenSigTimeoutTime_HU_B" SG_ 1167 EEM_EP_Failure_Status 0;
BA_ "GenSigTimeoutTime_HU_A" SG_ 1167 EEM_EP_Failure_Status 0;
BA_ "GenSigTimeoutMsg_HU_B" SG_ 1167 EEM_EP_Failure_Status 0;
BA_ "GenSigTimeoutMsg_HU_A" SG_ 1167 EEM_EP_Failure_Status 0;
BA_ "GenSigSendType" SG_ 1167 EEM_EP_Failure_Status 7;
BA_ "GenSigCycleTimeActive" SG_ 1167 EEM_EP_Failure_Status 100;
BA_ "GenSigCycleTime" SG_ 1167 EEM_EP_Failure_Status 100;
BA_ "GenSigTimeoutTime_HU_B" SG_ 1167 EMsMToFailureStatus 0;
BA_ "GenSigTimeoutTime_HU_A" SG_ 1167 EMsMToFailureStatus 0;
BA_ "GenSigTimeoutMsg_HU_B" SG_ 1167 EMsMToFailureStatus 0;
BA_ "GenSigTimeoutMsg_HU_A" SG_ 1167 EMsMToFailureStatus 0;
BA_ "GenSigSendType" SG_ 1167 EMsMToFailureStatus 7;
BA_ "GenSigCycleTimeActive" SG_ 1167 EMsMToFailureStatus 100;
BA_ "GenSigCycleTime" SG_ 1167 EMsMToFailureStatus 100;
BA_ "GenSigTimeoutTime_HU_B" SG_ 1167 EMS_MM_Failure_Status 0;
BA_ "GenSigTimeoutTime_HU_A" SG_ 1167 EMS_MM_Failure_Status 0;
BA_ "GenSigTimeoutMsg_HU_B" SG_ 1167 EMS_MM_Failure_Status 0;
BA_ "GenSigTimeoutMsg_HU_A" SG_ 1167 EMS_MM_Failure_Status 0;
BA_ "GenSigSendType" SG_ 1167 EMS_MM_Failure_Status 7;
BA_ "GenSigCycleTimeActive" SG_ 1167 EMS_MM_Failure_Status 100;
BA_ "GenSigCycleTime" SG_ 1167 EMS_MM_Failure_Status 100;
BA_ "GenSigTimeoutTime_HU_B" SG_ 1167 EMsInvalidFailureStatus 0;
BA_ "GenSigTimeoutTime_HU_A" SG_ 1167 EMsInvalidFailureStatus 0;
BA_ "GenSigTimeoutMsg_HU_B" SG_ 1167 EMsInvalidFailureStatus 0;
BA_ "GenSigTimeoutMsg_HU_A" SG_ 1167 EMsInvalidFailureStatus 0;
BA_ "GenSigSendType" SG_ 1167 EMsInvalidFailureStatus 7;
BA_ "GenSigCycleTimeActive" SG_ 1167 EMsInvalidFailureStatus 100;
BA_ "GenSigCycleTime" SG_ 1167 EMsInvalidFailureStatus 100;
BA_ "GenSigTimeoutTime_HU_B" SG_ 1167 IPcMToFailureStatus 0;
BA_ "GenSigTimeoutTime_HU_A" SG_ 1167 IPcMToFailureStatus 0;
BA_ "GenSigTimeoutMsg_HU_B" SG_ 1167 IPcMToFailureStatus 0;
BA_ "GenSigTimeoutMsg_HU_A" SG_ 1167 IPcMToFailureStatus 0;
BA_ "GenSigSendType" SG_ 1167 IPcMToFailureStatus 7;
BA_ "GenSigCycleTimeActive" SG_ 1167 IPcMToFailureStatus 100;
BA_ "GenSigCycleTime" SG_ 1167 IPcMToFailureStatus 100;
BA_ "GenSigTimeoutTime_HU_B" SG_ 1167 IPC_MM_Failure_Status 0;
BA_ "GenSigTimeoutTime_HU_A" SG_ 1167 IPC_MM_Failure_Status 0;
BA_ "GenSigTimeoutMsg_HU_B" SG_ 1167 IPC_MM_Failure_Status 0;
BA_ "GenSigTimeoutMsg_HU_A" SG_ 1167 IPC_MM_Failure_Status 0;
BA_ "GenSigSendType" SG_ 1167 IPC_MM_Failure_Status 7;
BA_ "GenSigCycleTimeActive" SG_ 1167 IPC_MM_Failure_Status 100;
BA_ "GenSigCycleTime" SG_ 1167 IPC_MM_Failure_Status 100;
BA_ "GenSigTimeoutTime_HU_B" SG_ 1167 IPcInvalidFailureStatus 0;
BA_ "GenSigTimeoutTime_HU_A" SG_ 1167 IPcInvalidFailureStatus 0;
BA_ "GenSigTimeoutMsg_HU_B" SG_ 1167 IPcInvalidFailureStatus 0;
BA_ "GenSigTimeoutMsg_HU_A" SG_ 1167 IPcInvalidFailureStatus 0;
BA_ "GenSigSendType" SG_ 1167 IPcInvalidFailureStatus 7;
BA_ "GenSigCycleTimeActive" SG_ 1167 IPcInvalidFailureStatus 100;
BA_ "GenSigCycleTime" SG_ 1167 IPcInvalidFailureStatus 100;
BA_ "GenSigTimeoutTime_HU_B" SG_ 1167 AMT_AT_DCT_MTO_Failure_Status 0;
BA_ "GenSigTimeoutTime_HU_A" SG_ 1167 AMT_AT_DCT_MTO_Failure_Status 0;
BA_ "GenSigTimeoutMsg_HU_B" SG_ 1167 AMT_AT_DCT_MTO_Failure_Status 0;
BA_ "GenSigTimeoutMsg_HU_A" SG_ 1167 AMT_AT_DCT_MTO_Failure_Status 0;
BA_ "GenSigSendType" SG_ 1167 AMT_AT_DCT_MTO_Failure_Status 7;
BA_ "GenSigCycleTimeActive" SG_ 1167 AMT_AT_DCT_MTO_Failure_Status 100;
BA_ "GenSigCycleTime" SG_ 1167 AMT_AT_DCT_MTO_Failure_Status 100;
BA_ "GenSigTimeoutTime_HU_B" SG_ 1167 AMT_AT_DCT_MM_Failure_Status 0;
BA_ "GenSigTimeoutTime_HU_A" SG_ 1167 AMT_AT_DCT_MM_Failure_Status 0;
BA_ "GenSigTimeoutMsg_HU_B" SG_ 1167 AMT_AT_DCT_MM_Failure_Status 0;
BA_ "GenSigTimeoutMsg_HU_A" SG_ 1167 AMT_AT_DCT_MM_Failure_Status 0;
BA_ "GenSigSendType" SG_ 1167 AMT_AT_DCT_MM_Failure_Status 7;
BA_ "GenSigCycleTimeActive" SG_ 1167 AMT_AT_DCT_MM_Failure_Status 100;
BA_ "GenSigCycleTime" SG_ 1167 AMT_AT_DCT_MM_Failure_Status 100;
BA_ "GenSigTimeoutTime_HU_B" SG_ 1167 AMT_AT_DCT_Invalid_Failure__0001 0;
BA_ "GenSigTimeoutTime_HU_A" SG_ 1167 AMT_AT_DCT_Invalid_Failure__0001 0;
BA_ "GenSigTimeoutMsg_HU_B" SG_ 1167 AMT_AT_DCT_Invalid_Failure__0001 0;
BA_ "GenSigTimeoutMsg_HU_A" SG_ 1167 AMT_AT_DCT_Invalid_Failure__0001 0;
BA_ "GenSigSendType" SG_ 1167 AMT_AT_DCT_Invalid_Failure__0001 7;
BA_ "GenSigCycleTimeActive" SG_ 1167 AMT_AT_DCT_Invalid_Failure__0001 100;
BA_ "GenSigCycleTime" SG_ 1167 AMT_AT_DCT_Invalid_Failure__0001 100;
BA_ "SystemSignalLongSymbol" SG_ 1167 AMT_AT_DCT_Invalid_Failure__0001 "AMT_AT_DCT_Invalid_Failure_Status";
BA_ "GenSigSendType" SG_ 1168 SRR_MTO_Failure_Status 7;
BA_ "GenSigCycleTimeActive" SG_ 1168 SRR_MTO_Failure_Status 100;
BA_ "GenSigCycleTime" SG_ 1168 SRR_MTO_Failure_Status 100;
BA_ "GenSigTimeoutTime_HU_B" SG_ 1168 FCmMToFailureStatus 0;
BA_ "GenSigTimeoutTime_HU_A" SG_ 1168 FCmMToFailureStatus 0;
BA_ "GenSigTimeoutMsg_HU_B" SG_ 1168 FCmMToFailureStatus 0;
BA_ "GenSigTimeoutMsg_HU_A" SG_ 1168 FCmMToFailureStatus 0;
BA_ "GenSigSendType" SG_ 1168 FCmMToFailureStatus 7;
BA_ "GenSigCycleTimeActive" SG_ 1168 FCmMToFailureStatus 100;
BA_ "GenSigCycleTime" SG_ 1168 FCmMToFailureStatus 100;
BA_ "GenSigTimeoutTime_HU_B" SG_ 1168 BCM_SW_Version 0;
BA_ "GenSigTimeoutTime_HU_A" SG_ 1168 BCM_SW_Version 0;
BA_ "GenSigTimeoutMsg_HU_B" SG_ 1168 BCM_SW_Version 0;
BA_ "GenSigTimeoutMsg_HU_A" SG_ 1168 BCM_SW_Version 0;
BA_ "GenSigSendType" SG_ 1168 BCM_SW_Version 7;
BA_ "GenSigCycleTimeActive" SG_ 1168 BCM_SW_Version 100;
BA_ "GenSigCycleTime" SG_ 1168 BCM_SW_Version 100;
BA_ "GenSigTimeoutTime_HU_B" SG_ 1168 AMT_AT_DCT_MTO_Failure_Status 0;
BA_ "GenSigTimeoutTime_HU_A" SG_ 1168 AMT_AT_DCT_MTO_Failure_Status 0;
BA_ "GenSigTimeoutMsg_HU_B" SG_ 1168 AMT_AT_DCT_MTO_Failure_Status 0;
BA_ "GenSigTimeoutMsg_HU_A" SG_ 1168 AMT_AT_DCT_MTO_Failure_Status 0;
BA_ "GenSigSendType" SG_ 1168 AMT_AT_DCT_MTO_Failure_Status 7;
BA_ "GenSigCycleTimeActive" SG_ 1168 AMT_AT_DCT_MTO_Failure_Status 100;
BA_ "GenSigCycleTime" SG_ 1168 AMT_AT_DCT_MTO_Failure_Status 100;
BA_ "GenSigTimeoutTime_HU_Mid_X451" SG_ 1168 PEPS_MRC_Failure_Status 0;
BA_ "GenSigTimeoutTime_HU_High_X451" SG_ 1168 PEPS_MRC_Failure_Status 0;
BA_ "GenSigTimeoutTime_HU_B" SG_ 1168 PEPS_MRC_Failure_Status 0;
BA_ "GenSigTimeoutTime_HU_A" SG_ 1168 PEPS_MRC_Failure_Status 0;
BA_ "GenSigTimeoutMsg_HU_Mid_X451" SG_ 1168 PEPS_MRC_Failure_Status 0;
BA_ "GenSigTimeoutMsg_HU_High_X451" SG_ 1168 PEPS_MRC_Failure_Status 0;
BA_ "GenSigTimeoutMsg_HU_B" SG_ 1168 PEPS_MRC_Failure_Status 0;
BA_ "GenSigTimeoutMsg_HU_A" SG_ 1168 PEPS_MRC_Failure_Status 0;
BA_ "GenSigSendType" SG_ 1168 PEPS_MRC_Failure_Status 7;
BA_ "GenSigCycleTimeActive" SG_ 1168 PEPS_MRC_Failure_Status 100;
BA_ "GenSigCycleTime" SG_ 1168 PEPS_MRC_Failure_Status 100;
BA_ "GenSigTimeoutTime_HU_B" SG_ 1168 AMT_AT_DCT_Invalid_Failure__0002 0;
BA_ "GenSigTimeoutTime_HU_A" SG_ 1168 AMT_AT_DCT_Invalid_Failure__0002 0;
BA_ "GenSigTimeoutMsg_HU_B" SG_ 1168 AMT_AT_DCT_Invalid_Failure__0002 0;
BA_ "GenSigTimeoutMsg_HU_A" SG_ 1168 AMT_AT_DCT_Invalid_Failure__0002 0;
BA_ "GenSigSendType" SG_ 1168 AMT_AT_DCT_Invalid_Failure__0002 7;
BA_ "GenSigCycleTimeActive" SG_ 1168 AMT_AT_DCT_Invalid_Failure__0002 100;
BA_ "GenSigCycleTime" SG_ 1168 AMT_AT_DCT_Invalid_Failure__0002 100;
BA_ "SystemSignalLongSymbol" SG_ 1168 AMT_AT_DCT_Invalid_Failure__0002 "AMT_AT_DCT_Invalid_Failure_Status";
BA_ "GenSigTimeoutTime_HU_Mid_X451" SG_ 1168 PEPS_CRC_Failure_Status 0;
BA_ "GenSigTimeoutTime_HU_High_X451" SG_ 1168 PEPS_CRC_Failure_Status 0;
BA_ "GenSigTimeoutTime_HU_B" SG_ 1168 PEPS_CRC_Failure_Status 0;
BA_ "GenSigTimeoutTime_HU_A" SG_ 1168 PEPS_CRC_Failure_Status 0;
BA_ "GenSigTimeoutMsg_HU_Mid_X451" SG_ 1168 PEPS_CRC_Failure_Status 0;
BA_ "GenSigTimeoutMsg_HU_High_X451" SG_ 1168 PEPS_CRC_Failure_Status 0;
BA_ "GenSigTimeoutMsg_HU_B" SG_ 1168 PEPS_CRC_Failure_Status 0;
BA_ "GenSigTimeoutMsg_HU_A" SG_ 1168 PEPS_CRC_Failure_Status 0;
BA_ "GenSigSendType" SG_ 1168 PEPS_CRC_Failure_Status 7;
BA_ "GenSigCycleTimeActive" SG_ 1168 PEPS_CRC_Failure_Status 100;
BA_ "GenSigCycleTime" SG_ 1168 PEPS_CRC_Failure_Status 100;
BA_ "GenSigTimeoutTime_HU_B" SG_ 1168 BCM_Err_State_Trans_Cntr 0;
BA_ "GenSigTimeoutTime_HU_A" SG_ 1168 BCM_Err_State_Trans_Cntr 0;
BA_ "GenSigTimeoutMsg_HU_B" SG_ 1168 BCM_Err_State_Trans_Cntr 0;
BA_ "GenSigTimeoutMsg_HU_A" SG_ 1168 BCM_Err_State_Trans_Cntr 0;
BA_ "GenSigSendType" SG_ 1168 BCM_Err_State_Trans_Cntr 7;
BA_ "GenSigCycleTimeActive" SG_ 1168 BCM_Err_State_Trans_Cntr 100;
BA_ "GenSigCycleTime" SG_ 1168 BCM_Err_State_Trans_Cntr 100;
BA_ "GenSigTimeoutTime_HU_B" SG_ 1168 BCM_EP_Failure_Status 0;
BA_ "GenSigTimeoutTime_HU_A" SG_ 1168 BCM_EP_Failure_Status 0;
BA_ "GenSigTimeoutMsg_HU_B" SG_ 1168 BCM_EP_Failure_Status 0;
BA_ "GenSigTimeoutMsg_HU_A" SG_ 1168 BCM_EP_Failure_Status 0;
BA_ "GenSigSendType" SG_ 1168 BCM_EP_Failure_Status 7;
BA_ "GenSigCycleTimeActive" SG_ 1168 BCM_EP_Failure_Status 100;
BA_ "GenSigCycleTime" SG_ 1168 BCM_EP_Failure_Status 100;
BA_ "GenSigTimeoutTime_HU_B" SG_ 1168 EMsInvalidFailureStatus 0;
BA_ "GenSigTimeoutTime_HU_A" SG_ 1168 EMsInvalidFailureStatus 0;
BA_ "GenSigTimeoutMsg_HU_B" SG_ 1168 EMsInvalidFailureStatus 0;
BA_ "GenSigTimeoutMsg_HU_A" SG_ 1168 EMsInvalidFailureStatus 0;
BA_ "GenSigSendType" SG_ 1168 EMsInvalidFailureStatus 7;
BA_ "GenSigCycleTimeActive" SG_ 1168 EMsInvalidFailureStatus 100;
BA_ "GenSigCycleTime" SG_ 1168 EMsInvalidFailureStatus 100;
BA_ "GenSigTimeoutTime_HU_B" SG_ 1168 EMsMToFailureStatus 0;
BA_ "GenSigTimeoutTime_HU_A" SG_ 1168 EMsMToFailureStatus 0;
BA_ "GenSigTimeoutMsg_HU_B" SG_ 1168 EMsMToFailureStatus 0;
BA_ "GenSigTimeoutMsg_HU_A" SG_ 1168 EMsMToFailureStatus 0;
BA_ "GenSigSendType" SG_ 1168 EMsMToFailureStatus 7;
BA_ "GenSigCycleTimeActive" SG_ 1168 EMsMToFailureStatus 100;
BA_ "GenSigCycleTime" SG_ 1168 EMsMToFailureStatus 100;
BA_ "GenSigTimeoutTime_HU_B" SG_ 1168 BCM_BO_Failure_Status 0;
BA_ "GenSigTimeoutTime_HU_A" SG_ 1168 BCM_BO_Failure_Status 0;
BA_ "GenSigTimeoutMsg_HU_B" SG_ 1168 BCM_BO_Failure_Status 0;
BA_ "GenSigTimeoutMsg_HU_A" SG_ 1168 BCM_BO_Failure_Status 0;
BA_ "GenSigSendType" SG_ 1168 BCM_BO_Failure_Status 7;
BA_ "GenSigCycleTimeActive" SG_ 1168 BCM_BO_Failure_Status 100;
BA_ "GenSigCycleTime" SG_ 1168 BCM_BO_Failure_Status 100;
BA_ "GenSigTimeoutTime_HU_B" SG_ 1168 IPcMToFailureStatus 0;
BA_ "GenSigTimeoutTime_HU_A" SG_ 1168 IPcMToFailureStatus 0;
BA_ "GenSigTimeoutMsg_HU_B" SG_ 1168 IPcMToFailureStatus 0;
BA_ "GenSigTimeoutMsg_HU_A" SG_ 1168 IPcMToFailureStatus 0;
BA_ "GenSigSendType" SG_ 1168 IPcMToFailureStatus 7;
BA_ "GenSigCycleTimeActive" SG_ 1168 IPcMToFailureStatus 100;
BA_ "GenSigCycleTime" SG_ 1168 IPcMToFailureStatus 100;
BA_ "GenSigTimeoutTime_HU_B" SG_ 1168 IPcInvalidFailureStatus 0;
BA_ "GenSigTimeoutTime_HU_A" SG_ 1168 IPcInvalidFailureStatus 0;
BA_ "GenSigTimeoutMsg_HU_B" SG_ 1168 IPcInvalidFailureStatus 0;
BA_ "GenSigTimeoutMsg_HU_A" SG_ 1168 IPcInvalidFailureStatus 0;
BA_ "GenSigSendType" SG_ 1168 IPcInvalidFailureStatus 7;
BA_ "GenSigCycleTimeActive" SG_ 1168 IPcInvalidFailureStatus 100;
BA_ "GenSigCycleTime" SG_ 1168 IPcInvalidFailureStatus 100;
BA_ "GenSigTimeoutTime_HU_B" SG_ 1168 SRS_MTO_Failure_Status 0;
BA_ "GenSigTimeoutTime_HU_A" SG_ 1168 SRS_MTO_Failure_Status 0;
BA_ "GenSigTimeoutMsg_HU_B" SG_ 1168 SRS_MTO_Failure_Status 0;
BA_ "GenSigTimeoutMsg_HU_A" SG_ 1168 SRS_MTO_Failure_Status 0;
BA_ "GenSigSendType" SG_ 1168 SRS_MTO_Failure_Status 7;
BA_ "GenSigCycleTimeActive" SG_ 1168 SRS_MTO_Failure_Status 100;
BA_ "GenSigCycleTime" SG_ 1168 SRS_MTO_Failure_Status 100;
BA_ "GenSigTimeoutTime_HU_B" SG_ 1168 VICM_Invalid_Failure_Status 0;
BA_ "GenSigTimeoutTime_HU_A" SG_ 1168 VICM_Invalid_Failure_Status 0;
BA_ "GenSigTimeoutMsg_HU_B" SG_ 1168 VICM_Invalid_Failure_Status 0;
BA_ "GenSigTimeoutMsg_HU_A" SG_ 1168 VICM_Invalid_Failure_Status 0;
BA_ "GenSigSendType" SG_ 1168 VICM_Invalid_Failure_Status 7;
BA_ "GenSigCycleTimeActive" SG_ 1168 VICM_Invalid_Failure_Status 100;
BA_ "GenSigCycleTime" SG_ 1168 VICM_Invalid_Failure_Status 100;
BA_ "GenSigTimeoutTime_HU_B" SG_ 1168 CCM_MTO_Failure_Status 0;
BA_ "GenSigTimeoutTime_HU_A" SG_ 1168 CCM_MTO_Failure_Status 0;
BA_ "GenSigTimeoutMsg_HU_B" SG_ 1168 CCM_MTO_Failure_Status 0;
BA_ "GenSigTimeoutMsg_HU_A" SG_ 1168 CCM_MTO_Failure_Status 0;
BA_ "GenSigSendType" SG_ 1168 CCM_MTO_Failure_Status 7;
BA_ "GenSigCycleTimeActive" SG_ 1168 CCM_MTO_Failure_Status 100;
BA_ "GenSigCycleTime" SG_ 1168 CCM_MTO_Failure_Status 100;
BA_ "GenSigTimeoutTime_HU_B" SG_ 1168 CCM_Invalid_Failure_Status 0;
BA_ "GenSigTimeoutTime_HU_A" SG_ 1168 CCM_Invalid_Failure_Status 0;
BA_ "GenSigTimeoutMsg_HU_B" SG_ 1168 CCM_Invalid_Failure_Status 0;
BA_ "GenSigTimeoutMsg_HU_A" SG_ 1168 CCM_Invalid_Failure_Status 0;
BA_ "GenSigSendType" SG_ 1168 CCM_Invalid_Failure_Status 7;
BA_ "GenSigCycleTimeActive" SG_ 1168 CCM_Invalid_Failure_Status 100;
BA_ "GenSigCycleTime" SG_ 1168 CCM_Invalid_Failure_Status 100;
BA_ "GenSigTimeoutTime_HU_B" SG_ 1168 VICM_MTO_Failure_Status 0;
BA_ "GenSigTimeoutTime_HU_A" SG_ 1168 VICM_MTO_Failure_Status 0;
BA_ "GenSigTimeoutMsg_HU_B" SG_ 1168 VICM_MTO_Failure_Status 0;
BA_ "GenSigTimeoutMsg_HU_A" SG_ 1168 VICM_MTO_Failure_Status 0;
BA_ "GenSigSendType" SG_ 1168 VICM_MTO_Failure_Status 7;
BA_ "GenSigCycleTimeActive" SG_ 1168 VICM_MTO_Failure_Status 100;
BA_ "GenSigCycleTime" SG_ 1168 VICM_MTO_Failure_Status 100;
BA_ "GenSigTimeoutTime_HU_B" SG_ 1168 PEPS_Invalid_failure_status 0;
BA_ "GenSigTimeoutTime_HU_A" SG_ 1168 PEPS_Invalid_failure_status 0;
BA_ "GenSigTimeoutMsg_HU_B" SG_ 1168 PEPS_Invalid_failure_status 0;
BA_ "GenSigTimeoutMsg_HU_A" SG_ 1168 PEPS_Invalid_failure_status 0;
BA_ "GenSigSendType" SG_ 1168 PEPS_Invalid_failure_status 7;
BA_ "GenSigCycleTimeActive" SG_ 1168 PEPS_Invalid_failure_status 100;
BA_ "GenSigCycleTime" SG_ 1168 PEPS_Invalid_failure_status 100;
BA_ "GenSigTimeoutTime_HU_B" SG_ 1168 PEPS_MTO_Failure_Status 0;
BA_ "GenSigTimeoutTime_HU_A" SG_ 1168 PEPS_MTO_Failure_Status 0;
BA_ "GenSigTimeoutMsg_HU_B" SG_ 1168 PEPS_MTO_Failure_Status 0;
BA_ "GenSigTimeoutMsg_HU_A" SG_ 1168 PEPS_MTO_Failure_Status 0;
BA_ "GenSigSendType" SG_ 1168 PEPS_MTO_Failure_Status 7;
BA_ "GenSigCycleTimeActive" SG_ 1168 PEPS_MTO_Failure_Status 100;
BA_ "GenSigCycleTime" SG_ 1168 PEPS_MTO_Failure_Status 100;
BA_ "GenSigTimeoutTime_HU_B" SG_ 1168 Trailer_MTO_Failure_Status 0;
BA_ "GenSigTimeoutTime_HU_A" SG_ 1168 Trailer_MTO_Failure_Status 0;
BA_ "GenSigTimeoutMsg_HU_B" SG_ 1168 Trailer_MTO_Failure_Status 0;
BA_ "GenSigTimeoutMsg_HU_A" SG_ 1168 Trailer_MTO_Failure_Status 0;
BA_ "GenSigSendType" SG_ 1168 Trailer_MTO_Failure_Status 7;
BA_ "GenSigCycleTimeActive" SG_ 1168 Trailer_MTO_Failure_Status 100;
BA_ "GenSigCycleTime" SG_ 1168 Trailer_MTO_Failure_Status 100;
BA_ "GenSigTimeoutTime_HU_B" SG_ 1168 TPMS_MTO_Failure_status 0;
BA_ "GenSigTimeoutTime_HU_A" SG_ 1168 TPMS_MTO_Failure_status 0;
BA_ "GenSigTimeoutMsg_HU_B" SG_ 1168 TPMS_MTO_Failure_status 0;
BA_ "GenSigTimeoutMsg_HU_A" SG_ 1168 TPMS_MTO_Failure_status 0;
BA_ "GenSigSendType" SG_ 1168 TPMS_MTO_Failure_status 7;
BA_ "GenSigCycleTimeActive" SG_ 1168 TPMS_MTO_Failure_status 100;
BA_ "GenSigCycleTime" SG_ 1168 TPMS_MTO_Failure_status 100;
BA_ "GenSigSendType" SG_ 1169 Telematics_Invalid_FailureStatus 7;
BA_ "GenSigCycleTimeActive" SG_ 1169 Telematics_Invalid_FailureStatus 100;
BA_ "GenSigCycleTime" SG_ 1169 Telematics_Invalid_FailureStatus 100;
BA_ "GenSigTimeoutTime_HU_Mid_X451" SG_ 1169 VCUMToFailureStatus 0;
BA_ "GenSigTimeoutTime_HU_High_X451" SG_ 1169 VCUMToFailureStatus 0;
BA_ "GenSigTimeoutTime_HU_B" SG_ 1169 VCUMToFailureStatus 0;
BA_ "GenSigTimeoutTime_HU_A" SG_ 1169 VCUMToFailureStatus 0;
BA_ "GenSigTimeoutMsg_HU_Mid_X451" SG_ 1169 VCUMToFailureStatus 0;
BA_ "GenSigTimeoutMsg_HU_High_X451" SG_ 1169 VCUMToFailureStatus 0;
BA_ "GenSigTimeoutMsg_HU_B" SG_ 1169 VCUMToFailureStatus 0;
BA_ "GenSigTimeoutMsg_HU_A" SG_ 1169 VCUMToFailureStatus 0;
BA_ "GenSigSendType" SG_ 1169 VCUMToFailureStatus 7;
BA_ "GenSigCycleTimeActive" SG_ 1169 VCUMToFailureStatus 100;
BA_ "GenSigCycleTime" SG_ 1169 VCUMToFailureStatus 100;
BA_ "GenSigTimeoutTime_HU_Mid_X451" SG_ 1169 VCUInvalidFailureStatus 0;
BA_ "GenSigTimeoutTime_HU_High_X451" SG_ 1169 VCUInvalidFailureStatus 0;
BA_ "GenSigTimeoutTime_HU_B" SG_ 1169 VCUInvalidFailureStatus 0;
BA_ "GenSigTimeoutTime_HU_A" SG_ 1169 VCUInvalidFailureStatus 0;
BA_ "GenSigTimeoutMsg_HU_Mid_X451" SG_ 1169 VCUInvalidFailureStatus 0;
BA_ "GenSigTimeoutMsg_HU_High_X451" SG_ 1169 VCUInvalidFailureStatus 0;
BA_ "GenSigTimeoutMsg_HU_B" SG_ 1169 VCUInvalidFailureStatus 0;
BA_ "GenSigTimeoutMsg_HU_A" SG_ 1169 VCUInvalidFailureStatus 0;
BA_ "GenSigSendType" SG_ 1169 VCUInvalidFailureStatus 7;
BA_ "GenSigCycleTimeActive" SG_ 1169 VCUInvalidFailureStatus 100;
BA_ "GenSigCycleTime" SG_ 1169 VCUInvalidFailureStatus 100;
BA_ "GenSigSendType" SG_ 1169 Telematics_MTO_Failure_status 7;
BA_ "GenSigCycleTimeActive" SG_ 1169 Telematics_MTO_Failure_status 100;
BA_ "GenSigCycleTime" SG_ 1169 Telematics_MTO_Failure_status 100;
BA_ "GenSigTimeoutTime_HU_B" SG_ 1169 EPAS_MTO_Failure_Status 0;
BA_ "GenSigTimeoutTime_HU_A" SG_ 1169 EPAS_MTO_Failure_Status 0;
BA_ "GenSigTimeoutMsg_HU_B" SG_ 1169 EPAS_MTO_Failure_Status 0;
BA_ "GenSigTimeoutMsg_HU_A" SG_ 1169 EPAS_MTO_Failure_Status 0;
BA_ "GenSigSendType" SG_ 1169 EPAS_MTO_Failure_Status 7;
BA_ "GenSigCycleTimeActive" SG_ 1169 EPAS_MTO_Failure_Status 100;
BA_ "GenSigCycleTime" SG_ 1169 EPAS_MTO_Failure_Status 100;
BA_ "GenSigTimeoutTime_HU_B" SG_ 1169 EPAS_Invalid_Failure_Status 0;
BA_ "GenSigTimeoutTime_HU_A" SG_ 1169 EPAS_Invalid_Failure_Status 0;
BA_ "GenSigTimeoutMsg_HU_B" SG_ 1169 EPAS_Invalid_Failure_Status 0;
BA_ "GenSigTimeoutMsg_HU_A" SG_ 1169 EPAS_Invalid_Failure_Status 0;
BA_ "GenSigSendType" SG_ 1169 EPAS_Invalid_Failure_Status 7;
BA_ "GenSigCycleTimeActive" SG_ 1169 EPAS_Invalid_Failure_Status 100;
BA_ "GenSigCycleTime" SG_ 1169 EPAS_Invalid_Failure_Status 100;
BA_ "GenSigTimeoutTime_HU_B" SG_ 1169 ESP_MTO_Failure_Status 0;
BA_ "GenSigTimeoutTime_HU_A" SG_ 1169 ESP_MTO_Failure_Status 0;
BA_ "GenSigTimeoutMsg_HU_B" SG_ 1169 ESP_MTO_Failure_Status 0;
BA_ "GenSigTimeoutMsg_HU_A" SG_ 1169 ESP_MTO_Failure_Status 0;
BA_ "GenSigSendType" SG_ 1169 ESP_MTO_Failure_Status 7;
BA_ "GenSigCycleTimeActive" SG_ 1169 ESP_MTO_Failure_Status 100;
BA_ "GenSigCycleTime" SG_ 1169 ESP_MTO_Failure_Status 100;
BA_ "GenSigTimeoutTime_HU_B" SG_ 1169 ESP_Invalid_Failure_Status 0;
BA_ "GenSigTimeoutTime_HU_A" SG_ 1169 ESP_Invalid_Failure_Status 0;
BA_ "GenSigTimeoutMsg_HU_B" SG_ 1169 ESP_Invalid_Failure_Status 0;
BA_ "GenSigTimeoutMsg_HU_A" SG_ 1169 ESP_Invalid_Failure_Status 0;
BA_ "GenSigSendType" SG_ 1169 ESP_Invalid_Failure_Status 7;
BA_ "GenSigCycleTimeActive" SG_ 1169 ESP_Invalid_Failure_Status 100;
BA_ "GenSigCycleTime" SG_ 1169 ESP_Invalid_Failure_Status 100;
BA_ "GenSigTimeoutTime_HU_B" SG_ 1169 HU_MTO_Failure_Status 0;
BA_ "GenSigTimeoutTime_HU_A" SG_ 1169 HU_MTO_Failure_Status 0;
BA_ "GenSigTimeoutMsg_HU_B" SG_ 1169 HU_MTO_Failure_Status 0;
BA_ "GenSigTimeoutMsg_HU_A" SG_ 1169 HU_MTO_Failure_Status 0;
BA_ "GenSigSendType" SG_ 1169 HU_MTO_Failure_Status 7;
BA_ "GenSigCycleTimeActive" SG_ 1169 HU_MTO_Failure_Status 100;
BA_ "GenSigCycleTime" SG_ 1169 HU_MTO_Failure_Status 100;
BA_ "GenSigTimeoutTime_HU_B" SG_ 1169 SAS_MTO_Failure_Status 0;
BA_ "GenSigTimeoutTime_HU_A" SG_ 1169 SAS_MTO_Failure_Status 0;
BA_ "GenSigTimeoutMsg_HU_B" SG_ 1169 SAS_MTO_Failure_Status 0;
BA_ "GenSigTimeoutMsg_HU_A" SG_ 1169 SAS_MTO_Failure_Status 0;
BA_ "GenSigSendType" SG_ 1169 SAS_MTO_Failure_Status 7;
BA_ "GenSigCycleTimeActive" SG_ 1169 SAS_MTO_Failure_Status 100;
BA_ "GenSigCycleTime" SG_ 1169 SAS_MTO_Failure_Status 100;
BA_ "GenSigSendType" SG_ 1170 Telematics_MTO_Failure_status 7;
BA_ "GenSigCycleTimeActive" SG_ 1170 Telematics_MTO_Failure_status 100;
BA_ "GenSigCycleTime" SG_ 1170 Telematics_MTO_Failure_status 100;
BA_ "GenSigSendType" SG_ 1170 Telematics_Invalid_FailureStatus 7;
BA_ "GenSigCycleTimeActive" SG_ 1170 Telematics_Invalid_FailureStatus 100;
BA_ "GenSigCycleTime" SG_ 1170 Telematics_Invalid_FailureStatus 100;
BA_ "GenSigTimeoutTime_HU_B" SG_ 1170 BCmInvalidFailureStatus 0;
BA_ "GenSigTimeoutTime_HU_A" SG_ 1170 BCmInvalidFailureStatus 0;
BA_ "GenSigTimeoutMsg_HU_B" SG_ 1170 BCmInvalidFailureStatus 0;
BA_ "GenSigTimeoutMsg_HU_A" SG_ 1170 BCmInvalidFailureStatus 0;
BA_ "GenSigSendType" SG_ 1170 BCmInvalidFailureStatus 7;
BA_ "GenSigCycleTimeActive" SG_ 1170 BCmInvalidFailureStatus 100;
BA_ "GenSigCycleTime" SG_ 1170 BCmInvalidFailureStatus 100;
BA_ "GenSigTimeoutTime_HU_B" SG_ 1170 CCM_SW_Version 0;
BA_ "GenSigTimeoutTime_HU_A" SG_ 1170 CCM_SW_Version 0;
BA_ "GenSigTimeoutMsg_HU_B" SG_ 1170 CCM_SW_Version 0;
BA_ "GenSigTimeoutMsg_HU_A" SG_ 1170 CCM_SW_Version 0;
BA_ "GenSigSendType" SG_ 1170 CCM_SW_Version 7;
BA_ "GenSigCycleTimeActive" SG_ 1170 CCM_SW_Version 100;
BA_ "GenSigCycleTime" SG_ 1170 CCM_SW_Version 100;
BA_ "GenSigTimeoutTime_HU_B" SG_ 1170 CCM_HW_Version 0;
BA_ "GenSigTimeoutTime_HU_A" SG_ 1170 CCM_HW_Version 0;
BA_ "GenSigTimeoutMsg_HU_B" SG_ 1170 CCM_HW_Version 0;
BA_ "GenSigTimeoutMsg_HU_A" SG_ 1170 CCM_HW_Version 0;
BA_ "GenSigSendType" SG_ 1170 CCM_HW_Version 7;
BA_ "GenSigCycleTimeActive" SG_ 1170 CCM_HW_Version 100;
BA_ "GenSigCycleTime" SG_ 1170 CCM_HW_Version 100;
BA_ "GenSigTimeoutTime_HU_B" SG_ 1170 BattVolt_FATC 0;
BA_ "GenSigTimeoutTime_HU_A" SG_ 1170 BattVolt_FATC 0;
BA_ "GenSigTimeoutMsg_HU_B" SG_ 1170 BattVolt_FATC 0;
BA_ "GenSigTimeoutMsg_HU_A" SG_ 1170 BattVolt_FATC 0;
BA_ "GenSigSendType" SG_ 1170 BattVolt_FATC 7;
BA_ "GenSigCycleTimeActive" SG_ 1170 BattVolt_FATC 100;
BA_ "GenSigCycleTime" SG_ 1170 BattVolt_FATC 100;
BA_ "GenSigTimeoutTime_HU_B" SG_ 1170 CCM_Err_State_Trans_Cntr 0;
BA_ "GenSigTimeoutTime_HU_A" SG_ 1170 CCM_Err_State_Trans_Cntr 0;
BA_ "GenSigTimeoutMsg_HU_B" SG_ 1170 CCM_Err_State_Trans_Cntr 0;
BA_ "GenSigTimeoutMsg_HU_A" SG_ 1170 CCM_Err_State_Trans_Cntr 0;
BA_ "GenSigSendType" SG_ 1170 CCM_Err_State_Trans_Cntr 7;
BA_ "GenSigCycleTimeActive" SG_ 1170 CCM_Err_State_Trans_Cntr 100;
BA_ "GenSigCycleTime" SG_ 1170 CCM_Err_State_Trans_Cntr 100;
BA_ "GenSigTimeoutTime_HU_B" SG_ 1170 BCmMToFailureStatus 0;
BA_ "GenSigTimeoutTime_HU_A" SG_ 1170 BCmMToFailureStatus 0;
BA_ "GenSigTimeoutMsg_HU_B" SG_ 1170 BCmMToFailureStatus 0;
BA_ "GenSigTimeoutMsg_HU_A" SG_ 1170 BCmMToFailureStatus 0;
BA_ "GenSigSendType" SG_ 1170 BCmMToFailureStatus 7;
BA_ "GenSigCycleTimeActive" SG_ 1170 BCmMToFailureStatus 100;
BA_ "GenSigCycleTime" SG_ 1170 BCmMToFailureStatus 100;
BA_ "GenSigTimeoutTime_HU_B" SG_ 1170 CCM_EP_Failure_Status 0;
BA_ "GenSigTimeoutTime_HU_A" SG_ 1170 CCM_EP_Failure_Status 0;
BA_ "GenSigTimeoutMsg_HU_B" SG_ 1170 CCM_EP_Failure_Status 0;
BA_ "GenSigTimeoutMsg_HU_A" SG_ 1170 CCM_EP_Failure_Status 0;
BA_ "GenSigSendType" SG_ 1170 CCM_EP_Failure_Status 7;
BA_ "GenSigCycleTimeActive" SG_ 1170 CCM_EP_Failure_Status 100;
BA_ "GenSigCycleTime" SG_ 1170 CCM_EP_Failure_Status 100;
BA_ "GenSigTimeoutTime_HU_B" SG_ 1170 CCM_BO_Failure_Status 0;
BA_ "GenSigTimeoutTime_HU_A" SG_ 1170 CCM_BO_Failure_Status 0;
BA_ "GenSigTimeoutMsg_HU_B" SG_ 1170 CCM_BO_Failure_Status 0;
BA_ "GenSigTimeoutMsg_HU_A" SG_ 1170 CCM_BO_Failure_Status 0;
BA_ "GenSigSendType" SG_ 1170 CCM_BO_Failure_Status 7;
BA_ "GenSigCycleTimeActive" SG_ 1170 CCM_BO_Failure_Status 100;
BA_ "GenSigCycleTime" SG_ 1170 CCM_BO_Failure_Status 100;
BA_ "GenSigTimeoutTime_HU_B" SG_ 1170 EMsMToFailureStatus 0;
BA_ "GenSigTimeoutTime_HU_A" SG_ 1170 EMsMToFailureStatus 0;
BA_ "GenSigTimeoutMsg_HU_B" SG_ 1170 EMsMToFailureStatus 0;
BA_ "GenSigTimeoutMsg_HU_A" SG_ 1170 EMsMToFailureStatus 0;
BA_ "GenSigSendType" SG_ 1170 EMsMToFailureStatus 7;
BA_ "GenSigCycleTimeActive" SG_ 1170 EMsMToFailureStatus 100;
BA_ "GenSigCycleTime" SG_ 1170 EMsMToFailureStatus 100;
BA_ "GenSigTimeoutTime_HU_B" SG_ 1170 EMsInvalidFailureStatus 0;
BA_ "GenSigTimeoutTime_HU_A" SG_ 1170 EMsInvalidFailureStatus 0;
BA_ "GenSigTimeoutMsg_HU_B" SG_ 1170 EMsInvalidFailureStatus 0;
BA_ "GenSigTimeoutMsg_HU_A" SG_ 1170 EMsInvalidFailureStatus 0;
BA_ "GenSigSendType" SG_ 1170 EMsInvalidFailureStatus 7;
BA_ "GenSigCycleTimeActive" SG_ 1170 EMsInvalidFailureStatus 100;
BA_ "GenSigCycleTime" SG_ 1170 EMsInvalidFailureStatus 100;
BA_ "GenSigTimeoutTime_HU_B" SG_ 1170 IPcInvalidFailureStatus 0;
BA_ "GenSigTimeoutTime_HU_A" SG_ 1170 IPcInvalidFailureStatus 0;
BA_ "GenSigTimeoutMsg_HU_B" SG_ 1170 IPcInvalidFailureStatus 0;
BA_ "GenSigTimeoutMsg_HU_A" SG_ 1170 IPcInvalidFailureStatus 0;
BA_ "GenSigSendType" SG_ 1170 IPcInvalidFailureStatus 7;
BA_ "GenSigCycleTimeActive" SG_ 1170 IPcInvalidFailureStatus 100;
BA_ "GenSigCycleTime" SG_ 1170 IPcInvalidFailureStatus 100;
BA_ "GenSigTimeoutTime_HU_B" SG_ 1170 HU_MTO_Failure_Status 0;
BA_ "GenSigTimeoutTime_HU_A" SG_ 1170 HU_MTO_Failure_Status 0;
BA_ "GenSigTimeoutMsg_HU_B" SG_ 1170 HU_MTO_Failure_Status 0;
BA_ "GenSigTimeoutMsg_HU_A" SG_ 1170 HU_MTO_Failure_Status 0;
BA_ "GenSigSendType" SG_ 1170 HU_MTO_Failure_Status 7;
BA_ "GenSigCycleTimeActive" SG_ 1170 HU_MTO_Failure_Status 100;
BA_ "GenSigCycleTime" SG_ 1170 HU_MTO_Failure_Status 100;
BA_ "GenSigTimeoutTime_HU_B" SG_ 1170 IPcMToFailureStatus 0;
BA_ "GenSigTimeoutTime_HU_A" SG_ 1170 IPcMToFailureStatus 0;
BA_ "GenSigTimeoutMsg_HU_B" SG_ 1170 IPcMToFailureStatus 0;
BA_ "GenSigTimeoutMsg_HU_A" SG_ 1170 IPcMToFailureStatus 0;
BA_ "GenSigSendType" SG_ 1170 IPcMToFailureStatus 7;
BA_ "GenSigCycleTimeActive" SG_ 1170 IPcMToFailureStatus 100;
BA_ "GenSigCycleTime" SG_ 1170 IPcMToFailureStatus 100;
BA_ "GenSigSendType" SG_ 1173 SRR_MTO_Failure_Status 7;
BA_ "GenSigCycleTimeActive" SG_ 1173 SRR_MTO_Failure_Status 100;
BA_ "GenSigCycleTime" SG_ 1173 SRR_MTO_Failure_Status 100;
BA_ "GenSigTimeoutTime_HU_B" SG_ 1173 FCmMToFailureStatus 0;
BA_ "GenSigTimeoutTime_HU_A" SG_ 1173 FCmMToFailureStatus 0;
BA_ "GenSigTimeoutMsg_HU_B" SG_ 1173 FCmMToFailureStatus 0;
BA_ "GenSigTimeoutMsg_HU_A" SG_ 1173 FCmMToFailureStatus 0;
BA_ "GenSigSendType" SG_ 1173 FCmMToFailureStatus 7;
BA_ "GenSigCycleTimeActive" SG_ 1173 FCmMToFailureStatus 100;
BA_ "GenSigCycleTime" SG_ 1173 FCmMToFailureStatus 100;
BA_ "GenSigSendType" SG_ 1173 Telematics_Invalid_FailureStatus 7;
BA_ "GenSigCycleTimeActive" SG_ 1173 Telematics_Invalid_FailureStatus 100;
BA_ "GenSigCycleTime" SG_ 1173 Telematics_Invalid_FailureStatus 100;
BA_ "GenSigSendType" SG_ 1173 VCUMToFailureStatus 7;
BA_ "GenSigCycleTimeActive" SG_ 1173 VCUMToFailureStatus 100;
BA_ "GenSigCycleTime" SG_ 1173 VCUMToFailureStatus 100;
BA_ "GenSigSendType" SG_ 1173 VCUInvalidFailureStatus 7;
BA_ "GenSigCycleTimeActive" SG_ 1173 VCUInvalidFailureStatus 100;
BA_ "GenSigCycleTime" SG_ 1173 VCUInvalidFailureStatus 100;
BA_ "GenSigSendType" SG_ 1173 Telematics_MTO_Failure_status 7;
BA_ "GenSigCycleTimeActive" SG_ 1173 Telematics_MTO_Failure_status 100;
BA_ "GenSigCycleTime" SG_ 1173 Telematics_MTO_Failure_status 100;
BA_ "GenSigSendType" SG_ 1173 HU_SW_Version 7;
BA_ "GenSigCycleTimeActive" SG_ 1173 HU_SW_Version 100;
BA_ "GenSigCycleTime" SG_ 1173 HU_SW_Version 100;
BA_ "GenSigSendType" SG_ 1173 EMsInvalidFailureStatus 7;
BA_ "GenSigCycleTimeActive" SG_ 1173 EMsInvalidFailureStatus 100;
BA_ "GenSigCycleTime" SG_ 1173 EMsInvalidFailureStatus 100;
BA_ "GenSigSendType" SG_ 1173 AMT_AT_DCT_MTO_Failure_Status 7;
BA_ "GenSigCycleTimeActive" SG_ 1173 AMT_AT_DCT_MTO_Failure_Status 100;
BA_ "GenSigCycleTime" SG_ 1173 AMT_AT_DCT_MTO_Failure_Status 100;
BA_ "GenSigSendType" SG_ 1173 AMT_AT_DCT_Invalid_Failure__0003 7;
BA_ "GenSigCycleTimeActive" SG_ 1173 AMT_AT_DCT_Invalid_Failure__0003 100;
BA_ "GenSigCycleTime" SG_ 1173 AMT_AT_DCT_Invalid_Failure__0003 100;
BA_ "SystemSignalLongSymbol" SG_ 1173 AMT_AT_DCT_Invalid_Failure__0003 "AMT_AT_DCT_Invalid_Failure_Status";
BA_ "GenSigSendType" SG_ 1173 ESpMToFailureStatus 7;
BA_ "GenSigCycleTimeActive" SG_ 1173 ESpMToFailureStatus 100;
BA_ "GenSigCycleTime" SG_ 1173 ESpMToFailureStatus 100;
BA_ "GenSigSendType" SG_ 1173 ESpInvalidFailureStatus 7;
BA_ "GenSigCycleTimeActive" SG_ 1173 ESpInvalidFailureStatus 100;
BA_ "GenSigCycleTime" SG_ 1173 ESpInvalidFailureStatus 100;
BA_ "GenSigSendType" SG_ 1173 CCM_Invalid_Failure_Status 7;
BA_ "GenSigCycleTimeActive" SG_ 1173 CCM_Invalid_Failure_Status 100;
BA_ "GenSigCycleTime" SG_ 1173 CCM_Invalid_Failure_Status 100;
BA_ "GenSigSendType" SG_ 1173 SRS_MTO_Failure_Status 7;
BA_ "GenSigCycleTimeActive" SG_ 1173 SRS_MTO_Failure_Status 100;
BA_ "GenSigCycleTime" SG_ 1173 SRS_MTO_Failure_Status 100;
BA_ "GenSigSendType" SG_ 1173 EMsMToFailureStatus 7;
BA_ "GenSigCycleTimeActive" SG_ 1173 EMsMToFailureStatus 100;
BA_ "GenSigCycleTime" SG_ 1173 EMsMToFailureStatus 100;
BA_ "GenSigSendType" SG_ 1173 PDC_MTO_Failure_Status 7;
BA_ "GenSigCycleTimeActive" SG_ 1173 PDC_MTO_Failure_Status 100;
BA_ "GenSigCycleTime" SG_ 1173 PDC_MTO_Failure_Status 100;
BA_ "GenSigSendType" SG_ 1173 IPcMToFailureStatus 7;
BA_ "GenSigCycleTimeActive" SG_ 1173 IPcMToFailureStatus 100;
BA_ "GenSigCycleTime" SG_ 1173 IPcMToFailureStatus 100;
BA_ "GenSigSendType" SG_ 1173 IPcInvalidFailureStatus 7;
BA_ "GenSigCycleTimeActive" SG_ 1173 IPcInvalidFailureStatus 100;
BA_ "GenSigCycleTime" SG_ 1173 IPcInvalidFailureStatus 100;
BA_ "GenSigSendType" SG_ 1173 PDC_Invalid_Failure_Status 7;
BA_ "GenSigCycleTimeActive" SG_ 1173 PDC_Invalid_Failure_Status 100;
BA_ "GenSigCycleTime" SG_ 1173 PDC_Invalid_Failure_Status 100;
BA_ "GenSigSendType" SG_ 1173 SAS_Invalid_Failure_Status 7;
BA_ "GenSigCycleTimeActive" SG_ 1173 SAS_Invalid_Failure_Status 100;
BA_ "GenSigCycleTime" SG_ 1173 SAS_Invalid_Failure_Status 100;
BA_ "GenSigSendType" SG_ 1173 SAS_MTO_Failure_Status 7;
BA_ "GenSigCycleTimeActive" SG_ 1173 SAS_MTO_Failure_Status 100;
BA_ "GenSigCycleTime" SG_ 1173 SAS_MTO_Failure_Status 100;
BA_ "GenSigSendType" SG_ 1173 EPAS_MTO_Failure_Status 7;
BA_ "GenSigCycleTimeActive" SG_ 1173 EPAS_MTO_Failure_Status 100;
BA_ "GenSigCycleTime" SG_ 1173 EPAS_MTO_Failure_Status 100;
BA_ "GenSigSendType" SG_ 1173 EPAS_Invalid_Failure_Status 7;
BA_ "GenSigCycleTimeActive" SG_ 1173 EPAS_Invalid_Failure_Status 100;
BA_ "GenSigCycleTime" SG_ 1173 EPAS_Invalid_Failure_Status 100;
BA_ "GenSigSendType" SG_ 1173 TPMS_MTO_Failure_status 7;
BA_ "GenSigCycleTimeActive" SG_ 1173 TPMS_MTO_Failure_status 100;
BA_ "GenSigCycleTime" SG_ 1173 TPMS_MTO_Failure_status 100;
BA_ "GenSigSendType" SG_ 1173 CCM_MTO_Failure_Status 7;
BA_ "GenSigCycleTimeActive" SG_ 1173 CCM_MTO_Failure_Status 100;
BA_ "GenSigCycleTime" SG_ 1173 CCM_MTO_Failure_Status 100;
BA_ "GenSigSendType" SG_ 1173 HU_EP_Failure_Status 7;
BA_ "GenSigCycleTimeActive" SG_ 1173 HU_EP_Failure_Status 100;
BA_ "GenSigCycleTime" SG_ 1173 HU_EP_Failure_Status 100;
BA_ "GenSigSendType" SG_ 1173 PEPS_MTO_Failure_Status 7;
BA_ "GenSigCycleTimeActive" SG_ 1173 PEPS_MTO_Failure_Status 100;
BA_ "GenSigCycleTime" SG_ 1173 PEPS_MTO_Failure_Status 100;
BA_ "GenSigSendType" SG_ 1173 BCmMToFailureStatus 7;
BA_ "GenSigCycleTimeActive" SG_ 1173 BCmMToFailureStatus 100;
BA_ "GenSigCycleTime" SG_ 1173 BCmMToFailureStatus 100;
BA_ "GenSigSendType" SG_ 1173 HU_BO_Failure_Status 7;
BA_ "GenSigCycleTimeActive" SG_ 1173 HU_BO_Failure_Status 100;
BA_ "GenSigCycleTime" SG_ 1173 HU_BO_Failure_Status 100;
BA_ "GenSigSendType" SG_ 1174 PEPS_Invalid_failure_status 7;
BA_ "GenSigCycleTimeActive" SG_ 1174 PEPS_Invalid_failure_status 100;
BA_ "GenSigCycleTime" SG_ 1174 PEPS_Invalid_failure_status 100;
BA_ "GenSigSendType" SG_ 1174 BCM_Invalid_Status_Failure 7;
BA_ "GenSigCycleTimeActive" SG_ 1174 BCM_Invalid_Status_Failure 100;
BA_ "GenSigCycleTime" SG_ 1174 BCM_Invalid_Status_Failure 100;
BA_ "GenSigSendType" SG_ 1176 FCmInvalidFailureStatus 7;
BA_ "GenSigCycleTimeActive" SG_ 1176 FCmInvalidFailureStatus 100;
BA_ "GenSigCycleTime" SG_ 1176 FCmInvalidFailureStatus 100;
BA_ "GenSigSendType" SG_ 1176 SRR_MTO_Failure_Status 7;
BA_ "GenSigCycleTimeActive" SG_ 1176 SRR_MTO_Failure_Status 100;
BA_ "GenSigCycleTime" SG_ 1176 SRR_MTO_Failure_Status 100;
BA_ "GenSigTimeoutTime_HU_B" SG_ 1176 FCmMToFailureStatus 0;
BA_ "GenSigTimeoutTime_HU_A" SG_ 1176 FCmMToFailureStatus 0;
BA_ "GenSigTimeoutMsg_HU_B" SG_ 1176 FCmMToFailureStatus 0;
BA_ "GenSigTimeoutMsg_HU_A" SG_ 1176 FCmMToFailureStatus 0;
BA_ "GenSigSendType" SG_ 1176 FCmMToFailureStatus 7;
BA_ "GenSigCycleTimeActive" SG_ 1176 FCmMToFailureStatus 100;
BA_ "GenSigCycleTime" SG_ 1176 FCmMToFailureStatus 100;
BA_ "GenSigSendType" SG_ 1176 BCM_Invalid_Status_Failure 7;
BA_ "GenSigCycleTimeActive" SG_ 1176 BCM_Invalid_Status_Failure 100;
BA_ "GenSigCycleTime" SG_ 1176 BCM_Invalid_Status_Failure 100;
BA_ "GenSigSendType" SG_ 1176 BCmMToFailureStatus 7;
BA_ "GenSigCycleTimeActive" SG_ 1176 BCmMToFailureStatus 100;
BA_ "GenSigCycleTime" SG_ 1176 BCmMToFailureStatus 100;
BA_ "GenSigSendType" SG_ 1176 CCM_Invalid_Failure_Status 7;
BA_ "GenSigCycleTimeActive" SG_ 1176 CCM_Invalid_Failure_Status 100;
BA_ "GenSigCycleTime" SG_ 1176 CCM_Invalid_Failure_Status 100;
BA_ "GenSigSendType" SG_ 1176 CCM_MTO_Failure_Status 7;
BA_ "GenSigCycleTimeActive" SG_ 1176 CCM_MTO_Failure_Status 100;
BA_ "GenSigCycleTime" SG_ 1176 CCM_MTO_Failure_Status 100;
BA_ "GenSigSendType" SG_ 1176 EMsInvalidFailureStatus 7;
BA_ "GenSigCycleTimeActive" SG_ 1176 EMsInvalidFailureStatus 100;
BA_ "GenSigCycleTime" SG_ 1176 EMsInvalidFailureStatus 100;
BA_ "GenSigSendType" SG_ 1176 EMsMToFailureStatus 7;
BA_ "GenSigCycleTimeActive" SG_ 1176 EMsMToFailureStatus 100;
BA_ "GenSigCycleTime" SG_ 1176 EMsMToFailureStatus 100;
BA_ "GenSigSendType" SG_ 1176 EPAS_Invalid_Failure_Status 7;
BA_ "GenSigCycleTimeActive" SG_ 1176 EPAS_Invalid_Failure_Status 100;
BA_ "GenSigCycleTime" SG_ 1176 EPAS_Invalid_Failure_Status 100;
BA_ "GenSigSendType" SG_ 1176 EPAS_MTO_Failure_Status 7;
BA_ "GenSigCycleTimeActive" SG_ 1176 EPAS_MTO_Failure_Status 100;
BA_ "GenSigCycleTime" SG_ 1176 EPAS_MTO_Failure_Status 100;
BA_ "GenSigSendType" SG_ 1176 ESpInvalidFailureStatus 7;
BA_ "GenSigCycleTimeActive" SG_ 1176 ESpInvalidFailureStatus 100;
BA_ "GenSigCycleTime" SG_ 1176 ESpInvalidFailureStatus 100;
BA_ "GenSigSendType" SG_ 1176 ESpMToFailureStatus 7;
BA_ "GenSigCycleTimeActive" SG_ 1176 ESpMToFailureStatus 100;
BA_ "GenSigCycleTime" SG_ 1176 ESpMToFailureStatus 100;
BA_ "GenSigSendType" SG_ 1176 HU_MTO_Failure_Status 7;
BA_ "GenSigCycleTimeActive" SG_ 1176 HU_MTO_Failure_Status 100;
BA_ "GenSigCycleTime" SG_ 1176 HU_MTO_Failure_Status 100;
BA_ "GenSigSendType" SG_ 1176 IPC_BO_Failure_Status 7;
BA_ "GenSigCycleTimeActive" SG_ 1176 IPC_BO_Failure_Status 100;
BA_ "GenSigCycleTime" SG_ 1176 IPC_BO_Failure_Status 100;
BA_ "GenSigSendType" SG_ 1176 IPC_EP_Failure_Status 7;
BA_ "GenSigCycleTimeActive" SG_ 1176 IPC_EP_Failure_Status 100;
BA_ "GenSigCycleTime" SG_ 1176 IPC_EP_Failure_Status 100;
BA_ "GenSigSendType" SG_ 1176 IPC_Err_State_Trans_Cntr 7;
BA_ "GenSigCycleTimeActive" SG_ 1176 IPC_Err_State_Trans_Cntr 100;
BA_ "GenSigCycleTime" SG_ 1176 IPC_Err_State_Trans_Cntr 100;
BA_ "GenSigSendType" SG_ 1176 IPC_SW_Version 7;
BA_ "GenSigCycleTimeActive" SG_ 1176 IPC_SW_Version 100;
BA_ "GenSigCycleTime" SG_ 1176 IPC_SW_Version 100;
BA_ "GenSigSendType" SG_ 1176 SRS_MTO_Failure_Status 7;
BA_ "GenSigCycleTimeActive" SG_ 1176 SRS_MTO_Failure_Status 100;
BA_ "GenSigCycleTime" SG_ 1176 SRS_MTO_Failure_Status 100;
BA_ "GenSigSendType" SG_ 1176 AMT_AT_DCT_Invalid_Failure__0004 7;
BA_ "GenSigCycleTimeActive" SG_ 1176 AMT_AT_DCT_Invalid_Failure__0004 100;
BA_ "GenSigCycleTime" SG_ 1176 AMT_AT_DCT_Invalid_Failure__0004 100;
BA_ "SystemSignalLongSymbol" SG_ 1176 AMT_AT_DCT_Invalid_Failure__0004 "AMT_AT_DCT_Invalid_Failure_Status";
BA_ "GenSigSendType" SG_ 1176 AMT_AT_DCT_MTO_Failure_Status 7;
BA_ "GenSigCycleTimeActive" SG_ 1176 AMT_AT_DCT_MTO_Failure_Status 100;
BA_ "GenSigCycleTime" SG_ 1176 AMT_AT_DCT_MTO_Failure_Status 100;
BA_ "GenSigSendType" SG_ 1176 TPMS_MTO_Failure_status 7;
BA_ "GenSigCycleTimeActive" SG_ 1176 TPMS_MTO_Failure_status 100;
BA_ "GenSigCycleTime" SG_ 1176 TPMS_MTO_Failure_status 100;
BA_ "GenSigSendType" SG_ 1177 LINA_EP_Failure_Status 7;
BA_ "GenSigCycleTimeActive" SG_ 1177 LINA_EP_Failure_Status 100;
BA_ "GenSigCycleTime" SG_ 1177 LINA_EP_Failure_Status 100;
BA_ "GenSigSendType" SG_ 1177 LINA_DustSensor_MTO_Failure_Stat 7;
BA_ "GenSigCycleTimeActive" SG_ 1177 LINA_DustSensor_MTO_Failure_Stat 100;
BA_ "GenSigCycleTime" SG_ 1177 LINA_DustSensor_MTO_Failure_Stat 100;
BA_ "SystemSignalLongSymbol" SG_ 1177 LINA_DustSensor_MTO_Failure_Stat "LINA_DustSensor_MTO_Failure_Status";
BA_ "GenSigSendType" SG_ 1177 LINA_BO_Failure_Status 7;
BA_ "GenSigCycleTimeActive" SG_ 1177 LINA_BO_Failure_Status 100;
BA_ "GenSigCycleTime" SG_ 1177 LINA_BO_Failure_Status 100;
BA_ "GenSigSendType" SG_ 1177 DCS_MTO_Failure_Status 7;
BA_ "GenSigCycleTimeActive" SG_ 1177 DCS_MTO_Failure_Status 100;
BA_ "GenSigCycleTime" SG_ 1177 DCS_MTO_Failure_Status 100;
BA_ "GenSigSendType" SG_ 1177 ESClMToFailureStatus 7;
BA_ "GenSigCycleTimeActive" SG_ 1177 ESClMToFailureStatus 100;
BA_ "GenSigCycleTime" SG_ 1177 ESClMToFailureStatus 100;
BA_ "GenSigSendType" SG_ 1177 PEPS_Invalid_failure_status 7;
BA_ "GenSigCycleTimeActive" SG_ 1177 PEPS_Invalid_failure_status 100;
BA_ "GenSigCycleTime" SG_ 1177 PEPS_Invalid_failure_status 100;
BA_ "GenSigSendType" SG_ 1177 PEPS_MTO_Failure_Status 7;
BA_ "GenSigCycleTimeActive" SG_ 1177 PEPS_MTO_Failure_Status 100;
BA_ "GenSigCycleTime" SG_ 1177 PEPS_MTO_Failure_Status 100;
BA_ "GenSigSendType" SG_ 1177 SAS_MTO_Failure_Status 7;
BA_ "GenSigCycleTimeActive" SG_ 1177 SAS_MTO_Failure_Status 100;
BA_ "GenSigCycleTime" SG_ 1177 SAS_MTO_Failure_Status 100;
BA_ "GenSigSendType" SG_ 1178 Telematics_Invalid_Failure__0003 7;
BA_ "GenSigCycleTimeActive" SG_ 1178 Telematics_Invalid_Failure__0003 100;
BA_ "GenSigCycleTime" SG_ 1178 Telematics_Invalid_Failure__0003 100;
BA_ "SystemSignalLongSymbol" SG_ 1178 Telematics_Invalid_Failure__0003 "Telematics_Invalid_Failure_Status";
BA_ "GenSigSendType" SG_ 1178 Telematics_MTO_Failure 7;
BA_ "GenSigCycleTimeActive" SG_ 1178 Telematics_MTO_Failure 100;
BA_ "GenSigCycleTime" SG_ 1178 Telematics_MTO_Failure 100;
BA_ "GenSigTimeoutTime_HU_Mid_X451" SG_ 1178 VCUInvalidFailureStatus 0;
BA_ "GenSigTimeoutTime_HU_High_X451" SG_ 1178 VCUInvalidFailureStatus 0;
BA_ "GenSigTimeoutTime_HU_B" SG_ 1178 VCUInvalidFailureStatus 0;
BA_ "GenSigTimeoutTime_HU_A" SG_ 1178 VCUInvalidFailureStatus 0;
BA_ "GenSigTimeoutMsg_HU_Mid_X451" SG_ 1178 VCUInvalidFailureStatus 0;
BA_ "GenSigTimeoutMsg_HU_High_X451" SG_ 1178 VCUInvalidFailureStatus 0;
BA_ "GenSigTimeoutMsg_HU_B" SG_ 1178 VCUInvalidFailureStatus 0;
BA_ "GenSigTimeoutMsg_HU_A" SG_ 1178 VCUInvalidFailureStatus 0;
BA_ "GenSigSendType" SG_ 1178 VCUInvalidFailureStatus 7;
BA_ "GenSigCycleTimeActive" SG_ 1178 VCUInvalidFailureStatus 100;
BA_ "GenSigCycleTime" SG_ 1178 VCUInvalidFailureStatus 100;
BA_ "GenSigTimeoutTime_HU_Mid_X451" SG_ 1178 VCUMToFailureStatus 0;
BA_ "GenSigTimeoutTime_HU_High_X451" SG_ 1178 VCUMToFailureStatus 0;
BA_ "GenSigTimeoutTime_HU_B" SG_ 1178 VCUMToFailureStatus 0;
BA_ "GenSigTimeoutTime_HU_A" SG_ 1178 VCUMToFailureStatus 0;
BA_ "GenSigTimeoutMsg_HU_Mid_X451" SG_ 1178 VCUMToFailureStatus 0;
BA_ "GenSigTimeoutMsg_HU_High_X451" SG_ 1178 VCUMToFailureStatus 0;
BA_ "GenSigTimeoutMsg_HU_B" SG_ 1178 VCUMToFailureStatus 0;
BA_ "GenSigTimeoutMsg_HU_A" SG_ 1178 VCUMToFailureStatus 0;
BA_ "GenSigSendType" SG_ 1178 VCUMToFailureStatus 7;
BA_ "GenSigCycleTimeActive" SG_ 1178 VCUMToFailureStatus 100;
BA_ "GenSigCycleTime" SG_ 1178 VCUMToFailureStatus 100;
BA_ "GenSigTimeoutTime_HU_B" SG_ 1178 PEPsSwVersion 0;
BA_ "GenSigTimeoutTime_HU_A" SG_ 1178 PEPsSwVersion 0;
BA_ "GenSigTimeoutMsg_HU_B" SG_ 1178 PEPsSwVersion 0;
BA_ "GenSigTimeoutMsg_HU_A" SG_ 1178 PEPsSwVersion 0;
BA_ "GenSigSendType" SG_ 1178 PEPsSwVersion 7;
BA_ "GenSigCycleTimeActive" SG_ 1178 PEPsSwVersion 100;
BA_ "GenSigCycleTime" SG_ 1178 PEPsSwVersion 100;
BA_ "GenSigTimeoutTime_HU_B" SG_ 1178 BattVoltPEPS 0;
BA_ "GenSigTimeoutTime_HU_A" SG_ 1178 BattVoltPEPS 0;
BA_ "GenSigTimeoutMsg_HU_B" SG_ 1178 BattVoltPEPS 0;
BA_ "GenSigTimeoutMsg_HU_A" SG_ 1178 BattVoltPEPS 0;
BA_ "GenSigSendType" SG_ 1178 BattVoltPEPS 7;
BA_ "GenSigCycleTimeActive" SG_ 1178 BattVoltPEPS 100;
BA_ "GenSigCycleTime" SG_ 1178 BattVoltPEPS 100;
BA_ "GenSigTimeoutTime_HU_B" SG_ 1178 PEPsEpFailureStatus 0;
BA_ "GenSigTimeoutTime_HU_A" SG_ 1178 PEPsEpFailureStatus 0;
BA_ "GenSigTimeoutMsg_HU_B" SG_ 1178 PEPsEpFailureStatus 0;
BA_ "GenSigTimeoutMsg_HU_A" SG_ 1178 PEPsEpFailureStatus 0;
BA_ "GenSigSendType" SG_ 1178 PEPsEpFailureStatus 7;
BA_ "GenSigCycleTimeActive" SG_ 1178 PEPsEpFailureStatus 100;
BA_ "GenSigCycleTime" SG_ 1178 PEPsEpFailureStatus 100;
BA_ "GenSigTimeoutTime_HU_B" SG_ 1178 PEPsBoFailureStatus 0;
BA_ "GenSigTimeoutTime_HU_A" SG_ 1178 PEPsBoFailureStatus 0;
BA_ "GenSigTimeoutMsg_HU_B" SG_ 1178 PEPsBoFailureStatus 0;
BA_ "GenSigTimeoutMsg_HU_A" SG_ 1178 PEPsBoFailureStatus 0;
BA_ "GenSigSendType" SG_ 1178 PEPsBoFailureStatus 7;
BA_ "GenSigCycleTimeActive" SG_ 1178 PEPsBoFailureStatus 100;
BA_ "GenSigCycleTime" SG_ 1178 PEPsBoFailureStatus 100;
BA_ "GenSigTimeoutTime_HU_B" SG_ 1178 ESClInvalidFailureStatus 0;
BA_ "GenSigTimeoutTime_HU_A" SG_ 1178 ESClInvalidFailureStatus 0;
BA_ "GenSigTimeoutMsg_HU_B" SG_ 1178 ESClInvalidFailureStatus 0;
BA_ "GenSigTimeoutMsg_HU_A" SG_ 1178 ESClInvalidFailureStatus 0;
BA_ "GenSigSendType" SG_ 1178 ESClInvalidFailureStatus 7;
BA_ "GenSigCycleTimeActive" SG_ 1178 ESClInvalidFailureStatus 100;
BA_ "GenSigCycleTime" SG_ 1178 ESClInvalidFailureStatus 100;
BA_ "GenSigTimeoutTime_HU_B" SG_ 1178 ESClMToFailureStatus 0;
BA_ "GenSigTimeoutTime_HU_A" SG_ 1178 ESClMToFailureStatus 0;
BA_ "GenSigTimeoutMsg_HU_B" SG_ 1178 ESClMToFailureStatus 0;
BA_ "GenSigTimeoutMsg_HU_A" SG_ 1178 ESClMToFailureStatus 0;
BA_ "GenSigSendType" SG_ 1178 ESClMToFailureStatus 7;
BA_ "GenSigCycleTimeActive" SG_ 1178 ESClMToFailureStatus 100;
BA_ "GenSigCycleTime" SG_ 1178 ESClMToFailureStatus 100;
BA_ "GenSigTimeoutTime_HU_B" SG_ 1178 BCmCRcFailureStatus 0;
BA_ "GenSigTimeoutTime_HU_A" SG_ 1178 BCmCRcFailureStatus 0;
BA_ "GenSigTimeoutMsg_HU_B" SG_ 1178 BCmCRcFailureStatus 0;
BA_ "GenSigTimeoutMsg_HU_A" SG_ 1178 BCmCRcFailureStatus 0;
BA_ "GenSigSendType" SG_ 1178 BCmCRcFailureStatus 7;
BA_ "GenSigCycleTimeActive" SG_ 1178 BCmCRcFailureStatus 100;
BA_ "GenSigCycleTime" SG_ 1178 BCmCRcFailureStatus 100;
BA_ "GenSigTimeoutTime_HU_B" SG_ 1178 BCmMRcFailureStatus 0;
BA_ "GenSigTimeoutTime_HU_A" SG_ 1178 BCmMRcFailureStatus 0;
BA_ "GenSigTimeoutMsg_HU_B" SG_ 1178 BCmMRcFailureStatus 0;
BA_ "GenSigTimeoutMsg_HU_A" SG_ 1178 BCmMRcFailureStatus 0;
BA_ "GenSigSendType" SG_ 1178 BCmMRcFailureStatus 7;
BA_ "GenSigCycleTimeActive" SG_ 1178 BCmMRcFailureStatus 100;
BA_ "GenSigCycleTime" SG_ 1178 BCmMRcFailureStatus 100;
BA_ "GenSigTimeoutTime_HU_B" SG_ 1178 BCmInvalidFailureStatus 0;
BA_ "GenSigTimeoutTime_HU_A" SG_ 1178 BCmInvalidFailureStatus 0;
BA_ "GenSigTimeoutMsg_HU_B" SG_ 1178 BCmInvalidFailureStatus 0;
BA_ "GenSigTimeoutMsg_HU_A" SG_ 1178 BCmInvalidFailureStatus 0;
BA_ "GenSigSendType" SG_ 1178 BCmInvalidFailureStatus 7;
BA_ "GenSigCycleTimeActive" SG_ 1178 BCmInvalidFailureStatus 100;
BA_ "GenSigCycleTime" SG_ 1178 BCmInvalidFailureStatus 100;
BA_ "GenSigTimeoutTime_HU_Mid_X451" SG_ 1178 BCmMToFailureStatus 0;
BA_ "GenSigTimeoutTime_HU_High_X451" SG_ 1178 BCmMToFailureStatus 0;
BA_ "GenSigTimeoutTime_HU_B" SG_ 1178 BCmMToFailureStatus 0;
BA_ "GenSigTimeoutTime_HU_A" SG_ 1178 BCmMToFailureStatus 0;
BA_ "GenSigTimeoutMsg_HU_Mid_X451" SG_ 1178 BCmMToFailureStatus 0;
BA_ "GenSigTimeoutMsg_HU_High_X451" SG_ 1178 BCmMToFailureStatus 0;
BA_ "GenSigTimeoutMsg_HU_B" SG_ 1178 BCmMToFailureStatus 0;
BA_ "GenSigTimeoutMsg_HU_A" SG_ 1178 BCmMToFailureStatus 0;
BA_ "GenSigSendType" SG_ 1178 BCmMToFailureStatus 7;
BA_ "GenSigCycleTimeActive" SG_ 1178 BCmMToFailureStatus 100;
BA_ "GenSigCycleTime" SG_ 1178 BCmMToFailureStatus 100;
BA_ "GenSigTimeoutTime_HU_B" SG_ 1178 ESpCRcFailureStatus 0;
BA_ "GenSigTimeoutTime_HU_A" SG_ 1178 ESpCRcFailureStatus 0;
BA_ "GenSigTimeoutMsg_HU_B" SG_ 1178 ESpCRcFailureStatus 0;
BA_ "GenSigTimeoutMsg_HU_A" SG_ 1178 ESpCRcFailureStatus 0;
BA_ "GenSigSendType" SG_ 1178 ESpCRcFailureStatus 7;
BA_ "GenSigCycleTimeActive" SG_ 1178 ESpCRcFailureStatus 100;
BA_ "GenSigCycleTime" SG_ 1178 ESpCRcFailureStatus 100;
BA_ "GenSigTimeoutTime_HU_B" SG_ 1178 ESpMRcFailureStutus 0;
BA_ "GenSigTimeoutTime_HU_A" SG_ 1178 ESpMRcFailureStutus 0;
BA_ "GenSigTimeoutMsg_HU_B" SG_ 1178 ESpMRcFailureStutus 0;
BA_ "GenSigTimeoutMsg_HU_A" SG_ 1178 ESpMRcFailureStutus 0;
BA_ "GenSigSendType" SG_ 1178 ESpMRcFailureStutus 7;
BA_ "GenSigCycleTimeActive" SG_ 1178 ESpMRcFailureStutus 100;
BA_ "GenSigCycleTime" SG_ 1178 ESpMRcFailureStutus 100;
BA_ "GenSigTimeoutTime_HU_B" SG_ 1178 ESpInvalidFailureStatus 0;
BA_ "GenSigTimeoutTime_HU_A" SG_ 1178 ESpInvalidFailureStatus 0;
BA_ "GenSigTimeoutMsg_HU_B" SG_ 1178 ESpInvalidFailureStatus 0;
BA_ "GenSigTimeoutMsg_HU_A" SG_ 1178 ESpInvalidFailureStatus 0;
BA_ "GenSigSendType" SG_ 1178 ESpInvalidFailureStatus 7;
BA_ "GenSigCycleTimeActive" SG_ 1178 ESpInvalidFailureStatus 100;
BA_ "GenSigCycleTime" SG_ 1178 ESpInvalidFailureStatus 100;
BA_ "GenSigTimeoutTime_HU_B" SG_ 1178 ESpMToFailureStatus 0;
BA_ "GenSigTimeoutTime_HU_A" SG_ 1178 ESpMToFailureStatus 0;
BA_ "GenSigTimeoutMsg_HU_B" SG_ 1178 ESpMToFailureStatus 0;
BA_ "GenSigTimeoutMsg_HU_A" SG_ 1178 ESpMToFailureStatus 0;
BA_ "GenSigSendType" SG_ 1178 ESpMToFailureStatus 7;
BA_ "GenSigCycleTimeActive" SG_ 1178 ESpMToFailureStatus 100;
BA_ "GenSigCycleTime" SG_ 1178 ESpMToFailureStatus 100;
BA_ "GenSigTimeoutTime_HU_B" SG_ 1178 EMsCRcFailureStatus 0;
BA_ "GenSigTimeoutTime_HU_A" SG_ 1178 EMsCRcFailureStatus 0;
BA_ "GenSigTimeoutMsg_HU_B" SG_ 1178 EMsCRcFailureStatus 0;
BA_ "GenSigTimeoutMsg_HU_A" SG_ 1178 EMsCRcFailureStatus 0;
BA_ "GenSigSendType" SG_ 1178 EMsCRcFailureStatus 7;
BA_ "GenSigCycleTimeActive" SG_ 1178 EMsCRcFailureStatus 100;
BA_ "GenSigCycleTime" SG_ 1178 EMsCRcFailureStatus 100;
BA_ "GenSigTimeoutTime_HU_B" SG_ 1178 EMsMRcFailureStatus 0;
BA_ "GenSigTimeoutTime_HU_A" SG_ 1178 EMsMRcFailureStatus 0;
BA_ "GenSigTimeoutMsg_HU_B" SG_ 1178 EMsMRcFailureStatus 0;
BA_ "GenSigTimeoutMsg_HU_A" SG_ 1178 EMsMRcFailureStatus 0;
BA_ "GenSigSendType" SG_ 1178 EMsMRcFailureStatus 7;
BA_ "GenSigCycleTimeActive" SG_ 1178 EMsMRcFailureStatus 100;
BA_ "GenSigCycleTime" SG_ 1178 EMsMRcFailureStatus 100;
BA_ "GenSigTimeoutTime_HU_B" SG_ 1178 EMsInvalidFailureStatus 0;
BA_ "GenSigTimeoutTime_HU_A" SG_ 1178 EMsInvalidFailureStatus 0;
BA_ "GenSigTimeoutMsg_HU_B" SG_ 1178 EMsInvalidFailureStatus 0;
BA_ "GenSigTimeoutMsg_HU_A" SG_ 1178 EMsInvalidFailureStatus 0;
BA_ "GenSigSendType" SG_ 1178 EMsInvalidFailureStatus 7;
BA_ "GenSigCycleTimeActive" SG_ 1178 EMsInvalidFailureStatus 100;
BA_ "GenSigCycleTime" SG_ 1178 EMsInvalidFailureStatus 100;
BA_ "GenSigTimeoutTime_HU_B" SG_ 1178 EMsMToFailureStatus 0;
BA_ "GenSigTimeoutTime_HU_A" SG_ 1178 EMsMToFailureStatus 0;
BA_ "GenSigTimeoutMsg_HU_B" SG_ 1178 EMsMToFailureStatus 0;
BA_ "GenSigTimeoutMsg_HU_A" SG_ 1178 EMsMToFailureStatus 0;
BA_ "GenSigSendType" SG_ 1178 EMsMToFailureStatus 7;
BA_ "GenSigCycleTimeActive" SG_ 1178 EMsMToFailureStatus 100;
BA_ "GenSigCycleTime" SG_ 1178 EMsMToFailureStatus 100;
BA_ "GenSigTimeoutTime_HU_B" SG_ 1178 AMT_AT_DCT_MTO_Failure_Status 0;
BA_ "GenSigTimeoutTime_HU_A" SG_ 1178 AMT_AT_DCT_MTO_Failure_Status 0;
BA_ "GenSigTimeoutMsg_HU_B" SG_ 1178 AMT_AT_DCT_MTO_Failure_Status 0;
BA_ "GenSigTimeoutMsg_HU_A" SG_ 1178 AMT_AT_DCT_MTO_Failure_Status 0;
BA_ "GenSigSendType" SG_ 1178 AMT_AT_DCT_MTO_Failure_Status 7;
BA_ "GenSigCycleTimeActive" SG_ 1178 AMT_AT_DCT_MTO_Failure_Status 100;
BA_ "GenSigCycleTime" SG_ 1178 AMT_AT_DCT_MTO_Failure_Status 100;
BA_ "GenSigTimeoutTime_HU_B" SG_ 1178 AMT_AT_DCT_Invalid_Failure__0005 0;
BA_ "GenSigTimeoutTime_HU_A" SG_ 1178 AMT_AT_DCT_Invalid_Failure__0005 0;
BA_ "GenSigTimeoutMsg_HU_B" SG_ 1178 AMT_AT_DCT_Invalid_Failure__0005 0;
BA_ "GenSigTimeoutMsg_HU_A" SG_ 1178 AMT_AT_DCT_Invalid_Failure__0005 0;
BA_ "GenSigSendType" SG_ 1178 AMT_AT_DCT_Invalid_Failure__0005 7;
BA_ "GenSigCycleTimeActive" SG_ 1178 AMT_AT_DCT_Invalid_Failure__0005 100;
BA_ "GenSigCycleTime" SG_ 1178 AMT_AT_DCT_Invalid_Failure__0005 100;
BA_ "SystemSignalLongSymbol" SG_ 1178 AMT_AT_DCT_Invalid_Failure__0005 "AMT_AT_DCT_Invalid_Failure_Status";
BA_ "GenSigTimeoutTime_HU_B" SG_ 1179 PDC_SW_Version 0;
BA_ "GenSigTimeoutTime_HU_A" SG_ 1179 PDC_SW_Version 0;
BA_ "GenSigTimeoutMsg_HU_B" SG_ 1179 PDC_SW_Version 0;
BA_ "GenSigTimeoutMsg_HU_A" SG_ 1179 PDC_SW_Version 0;
BA_ "GenSigSendType" SG_ 1179 PDC_SW_Version 7;
BA_ "GenSigCycleTimeActive" SG_ 1179 PDC_SW_Version 100;
BA_ "GenSigCycleTime" SG_ 1179 PDC_SW_Version 100;
BA_ "GenSigTimeoutTime_HU_B" SG_ 1179 PDC_HW_Version 0;
BA_ "GenSigTimeoutTime_HU_A" SG_ 1179 PDC_HW_Version 0;
BA_ "GenSigTimeoutMsg_HU_B" SG_ 1179 PDC_HW_Version 0;
BA_ "GenSigTimeoutMsg_HU_A" SG_ 1179 PDC_HW_Version 0;
BA_ "GenSigSendType" SG_ 1179 PDC_HW_Version 7;
BA_ "GenSigCycleTimeActive" SG_ 1179 PDC_HW_Version 100;
BA_ "GenSigCycleTime" SG_ 1179 PDC_HW_Version 100;
BA_ "GenSigTimeoutTime_HU_B" SG_ 1179 AMT_AT_DCT_Invalid_Failure__0006 0;
BA_ "GenSigTimeoutTime_HU_A" SG_ 1179 AMT_AT_DCT_Invalid_Failure__0006 0;
BA_ "GenSigTimeoutMsg_HU_B" SG_ 1179 AMT_AT_DCT_Invalid_Failure__0006 0;
BA_ "GenSigTimeoutMsg_HU_A" SG_ 1179 AMT_AT_DCT_Invalid_Failure__0006 0;
BA_ "GenSigSendType" SG_ 1179 AMT_AT_DCT_Invalid_Failure__0006 7;
BA_ "GenSigCycleTimeActive" SG_ 1179 AMT_AT_DCT_Invalid_Failure__0006 100;
BA_ "GenSigCycleTime" SG_ 1179 AMT_AT_DCT_Invalid_Failure__0006 100;
BA_ "SystemSignalLongSymbol" SG_ 1179 AMT_AT_DCT_Invalid_Failure__0006 "AMT_AT_DCT_Invalid_Failure_Status";
BA_ "GenSigTimeoutTime_HU_B" SG_ 1179 PDC_Err_State_Trans_Cntr 0;
BA_ "GenSigTimeoutTime_HU_A" SG_ 1179 PDC_Err_State_Trans_Cntr 0;
BA_ "GenSigTimeoutMsg_HU_B" SG_ 1179 PDC_Err_State_Trans_Cntr 0;
BA_ "GenSigTimeoutMsg_HU_A" SG_ 1179 PDC_Err_State_Trans_Cntr 0;
BA_ "GenSigSendType" SG_ 1179 PDC_Err_State_Trans_Cntr 7;
BA_ "GenSigCycleTimeActive" SG_ 1179 PDC_Err_State_Trans_Cntr 100;
BA_ "GenSigCycleTime" SG_ 1179 PDC_Err_State_Trans_Cntr 100;
BA_ "GenSigTimeoutTime_HU_B" SG_ 1179 BattVolt_PDC 0;
BA_ "GenSigTimeoutTime_HU_A" SG_ 1179 BattVolt_PDC 0;
BA_ "GenSigTimeoutMsg_HU_B" SG_ 1179 BattVolt_PDC 0;
BA_ "GenSigTimeoutMsg_HU_A" SG_ 1179 BattVolt_PDC 0;
BA_ "GenSigSendType" SG_ 1179 BattVolt_PDC 7;
BA_ "GenSigCycleTimeActive" SG_ 1179 BattVolt_PDC 100;
BA_ "GenSigCycleTime" SG_ 1179 BattVolt_PDC 100;
BA_ "GenSigTimeoutTime_HU_B" SG_ 1179 BCmMToFailureStatus 0;
BA_ "GenSigTimeoutTime_HU_A" SG_ 1179 BCmMToFailureStatus 0;
BA_ "GenSigTimeoutMsg_HU_B" SG_ 1179 BCmMToFailureStatus 0;
BA_ "GenSigTimeoutMsg_HU_A" SG_ 1179 BCmMToFailureStatus 0;
BA_ "GenSigSendType" SG_ 1179 BCmMToFailureStatus 7;
BA_ "GenSigCycleTimeActive" SG_ 1179 BCmMToFailureStatus 100;
BA_ "GenSigCycleTime" SG_ 1179 BCmMToFailureStatus 100;
BA_ "GenSigTimeoutTime_HU_B" SG_ 1179 BCM_MM_Failure_Status 0;
BA_ "GenSigTimeoutTime_HU_A" SG_ 1179 BCM_MM_Failure_Status 0;
BA_ "GenSigTimeoutMsg_HU_B" SG_ 1179 BCM_MM_Failure_Status 0;
BA_ "GenSigTimeoutMsg_HU_A" SG_ 1179 BCM_MM_Failure_Status 0;
BA_ "GenSigSendType" SG_ 1179 BCM_MM_Failure_Status 7;
BA_ "GenSigCycleTimeActive" SG_ 1179 BCM_MM_Failure_Status 100;
BA_ "GenSigCycleTime" SG_ 1179 BCM_MM_Failure_Status 100;
BA_ "GenSigTimeoutTime_HU_B" SG_ 1179 PDC_EP_Failure_Status 0;
BA_ "GenSigTimeoutTime_HU_A" SG_ 1179 PDC_EP_Failure_Status 0;
BA_ "GenSigTimeoutMsg_HU_B" SG_ 1179 PDC_EP_Failure_Status 0;
BA_ "GenSigTimeoutMsg_HU_A" SG_ 1179 PDC_EP_Failure_Status 0;
BA_ "GenSigSendType" SG_ 1179 PDC_EP_Failure_Status 7;
BA_ "GenSigCycleTimeActive" SG_ 1179 PDC_EP_Failure_Status 100;
BA_ "GenSigCycleTime" SG_ 1179 PDC_EP_Failure_Status 100;
BA_ "GenSigTimeoutTime_HU_B" SG_ 1179 PDC_BO_Failure_Status 0;
BA_ "GenSigTimeoutTime_HU_A" SG_ 1179 PDC_BO_Failure_Status 0;
BA_ "GenSigTimeoutMsg_HU_B" SG_ 1179 PDC_BO_Failure_Status 0;
BA_ "GenSigTimeoutMsg_HU_A" SG_ 1179 PDC_BO_Failure_Status 0;
BA_ "GenSigSendType" SG_ 1179 PDC_BO_Failure_Status 7;
BA_ "GenSigCycleTimeActive" SG_ 1179 PDC_BO_Failure_Status 100;
BA_ "GenSigCycleTime" SG_ 1179 PDC_BO_Failure_Status 100;
BA_ "GenSigTimeoutTime_HU_B" SG_ 1179 HU_MTO_Failure_Status 0;
BA_ "GenSigTimeoutTime_HU_A" SG_ 1179 HU_MTO_Failure_Status 0;
BA_ "GenSigTimeoutMsg_HU_B" SG_ 1179 HU_MTO_Failure_Status 0;
BA_ "GenSigTimeoutMsg_HU_A" SG_ 1179 HU_MTO_Failure_Status 0;
BA_ "GenSigSendType" SG_ 1179 HU_MTO_Failure_Status 7;
BA_ "GenSigCycleTimeActive" SG_ 1179 HU_MTO_Failure_Status 100;
BA_ "GenSigCycleTime" SG_ 1179 HU_MTO_Failure_Status 100;
BA_ "GenSigTimeoutTime_HU_B" SG_ 1179 HU_MM_Failure_Status 0;
BA_ "GenSigTimeoutTime_HU_A" SG_ 1179 HU_MM_Failure_Status 0;
BA_ "GenSigTimeoutMsg_HU_B" SG_ 1179 HU_MM_Failure_Status 0;
BA_ "GenSigTimeoutMsg_HU_A" SG_ 1179 HU_MM_Failure_Status 0;
BA_ "GenSigSendType" SG_ 1179 HU_MM_Failure_Status 7;
BA_ "GenSigCycleTimeActive" SG_ 1179 HU_MM_Failure_Status 100;
BA_ "GenSigCycleTime" SG_ 1179 HU_MM_Failure_Status 100;
BA_ "GenSigTimeoutTime_HU_B" SG_ 1179 AMT_AT_DCT_MTO_Failure_Status 0;
BA_ "GenSigTimeoutTime_HU_A" SG_ 1179 AMT_AT_DCT_MTO_Failure_Status 0;
BA_ "GenSigTimeoutMsg_HU_B" SG_ 1179 AMT_AT_DCT_MTO_Failure_Status 0;
BA_ "GenSigTimeoutMsg_HU_A" SG_ 1179 AMT_AT_DCT_MTO_Failure_Status 0;
BA_ "GenSigSendType" SG_ 1179 AMT_AT_DCT_MTO_Failure_Status 7;
BA_ "GenSigCycleTimeActive" SG_ 1179 AMT_AT_DCT_MTO_Failure_Status 100;
BA_ "GenSigCycleTime" SG_ 1179 AMT_AT_DCT_MTO_Failure_Status 100;
BA_ "GenSigTimeoutTime_HU_B" SG_ 1179 IPC_MM_Failure_Status 0;
BA_ "GenSigTimeoutTime_HU_A" SG_ 1179 IPC_MM_Failure_Status 0;
BA_ "GenSigTimeoutMsg_HU_B" SG_ 1179 IPC_MM_Failure_Status 0;
BA_ "GenSigTimeoutMsg_HU_A" SG_ 1179 IPC_MM_Failure_Status 0;
BA_ "GenSigSendType" SG_ 1179 IPC_MM_Failure_Status 7;
BA_ "GenSigCycleTimeActive" SG_ 1179 IPC_MM_Failure_Status 100;
BA_ "GenSigCycleTime" SG_ 1179 IPC_MM_Failure_Status 100;
BA_ "GenSigTimeoutTime_HU_B" SG_ 1179 IPcMToFailureStatus 0;
BA_ "GenSigTimeoutTime_HU_A" SG_ 1179 IPcMToFailureStatus 0;
BA_ "GenSigTimeoutMsg_HU_B" SG_ 1179 IPcMToFailureStatus 0;
BA_ "GenSigTimeoutMsg_HU_A" SG_ 1179 IPcMToFailureStatus 0;
BA_ "GenSigSendType" SG_ 1179 IPcMToFailureStatus 7;
BA_ "GenSigCycleTimeActive" SG_ 1179 IPcMToFailureStatus 100;
BA_ "GenSigCycleTime" SG_ 1179 IPcMToFailureStatus 100;
BA_ "GenSigTimeoutTime_HU_B" SG_ 1179 IPcInvalidFailureStatus 0;
BA_ "GenSigTimeoutTime_HU_A" SG_ 1179 IPcInvalidFailureStatus 0;
BA_ "GenSigTimeoutMsg_HU_B" SG_ 1179 IPcInvalidFailureStatus 0;
BA_ "GenSigTimeoutMsg_HU_A" SG_ 1179 IPcInvalidFailureStatus 0;
BA_ "GenSigSendType" SG_ 1179 IPcInvalidFailureStatus 7;
BA_ "GenSigCycleTimeActive" SG_ 1179 IPcInvalidFailureStatus 100;
BA_ "GenSigCycleTime" SG_ 1179 IPcInvalidFailureStatus 100;
BA_ "GenSigTimeoutTime_HU_B" SG_ 1180 Trailer_SW_Version 0;
BA_ "GenSigTimeoutTime_HU_A" SG_ 1180 Trailer_SW_Version 0;
BA_ "GenSigTimeoutMsg_HU_B" SG_ 1180 Trailer_SW_Version 0;
BA_ "GenSigTimeoutMsg_HU_A" SG_ 1180 Trailer_SW_Version 0;
BA_ "GenSigSendType" SG_ 1180 Trailer_SW_Version 7;
BA_ "GenSigCycleTimeActive" SG_ 1180 Trailer_SW_Version 100;
BA_ "GenSigCycleTime" SG_ 1180 Trailer_SW_Version 100;
BA_ "GenSigTimeoutTime_HU_B" SG_ 1180 Trailer_HW_Version 0;
BA_ "GenSigTimeoutTime_HU_A" SG_ 1180 Trailer_HW_Version 0;
BA_ "GenSigTimeoutMsg_HU_B" SG_ 1180 Trailer_HW_Version 0;
BA_ "GenSigTimeoutMsg_HU_A" SG_ 1180 Trailer_HW_Version 0;
BA_ "GenSigSendType" SG_ 1180 Trailer_HW_Version 7;
BA_ "GenSigCycleTimeActive" SG_ 1180 Trailer_HW_Version 100;
BA_ "GenSigCycleTime" SG_ 1180 Trailer_HW_Version 100;
BA_ "GenSigTimeoutTime_HU_B" SG_ 1180 Trailer_Err_State_Trans_Cntr 0;
BA_ "GenSigTimeoutTime_HU_A" SG_ 1180 Trailer_Err_State_Trans_Cntr 0;
BA_ "GenSigTimeoutMsg_HU_B" SG_ 1180 Trailer_Err_State_Trans_Cntr 0;
BA_ "GenSigTimeoutMsg_HU_A" SG_ 1180 Trailer_Err_State_Trans_Cntr 0;
BA_ "GenSigSendType" SG_ 1180 Trailer_Err_State_Trans_Cntr 7;
BA_ "GenSigCycleTimeActive" SG_ 1180 Trailer_Err_State_Trans_Cntr 100;
BA_ "GenSigCycleTime" SG_ 1180 Trailer_Err_State_Trans_Cntr 100;
BA_ "GenSigTimeoutTime_HU_B" SG_ 1180 BattVolt_Trailer 0;
BA_ "GenSigTimeoutTime_HU_A" SG_ 1180 BattVolt_Trailer 0;
BA_ "GenSigTimeoutMsg_HU_B" SG_ 1180 BattVolt_Trailer 0;
BA_ "GenSigTimeoutMsg_HU_A" SG_ 1180 BattVolt_Trailer 0;
BA_ "GenSigSendType" SG_ 1180 BattVolt_Trailer 7;
BA_ "GenSigCycleTimeActive" SG_ 1180 BattVolt_Trailer 100;
BA_ "GenSigCycleTime" SG_ 1180 BattVolt_Trailer 100;
BA_ "GenSigTimeoutTime_HU_B" SG_ 1180 Trailer_EP_Failure_Status 0;
BA_ "GenSigTimeoutTime_HU_A" SG_ 1180 Trailer_EP_Failure_Status 0;
BA_ "GenSigTimeoutMsg_HU_B" SG_ 1180 Trailer_EP_Failure_Status 0;
BA_ "GenSigTimeoutMsg_HU_A" SG_ 1180 Trailer_EP_Failure_Status 0;
BA_ "GenSigSendType" SG_ 1180 Trailer_EP_Failure_Status 7;
BA_ "GenSigCycleTimeActive" SG_ 1180 Trailer_EP_Failure_Status 100;
BA_ "GenSigCycleTime" SG_ 1180 Trailer_EP_Failure_Status 100;
BA_ "GenSigTimeoutTime_HU_B" SG_ 1180 Trailer_BO_Failure_Status 0;
BA_ "GenSigTimeoutTime_HU_A" SG_ 1180 Trailer_BO_Failure_Status 0;
BA_ "GenSigTimeoutMsg_HU_B" SG_ 1180 Trailer_BO_Failure_Status 0;
BA_ "GenSigTimeoutMsg_HU_A" SG_ 1180 Trailer_BO_Failure_Status 0;
BA_ "GenSigSendType" SG_ 1180 Trailer_BO_Failure_Status 7;
BA_ "GenSigCycleTimeActive" SG_ 1180 Trailer_BO_Failure_Status 100;
BA_ "GenSigCycleTime" SG_ 1180 Trailer_BO_Failure_Status 100;
BA_ "GenSigTimeoutTime_HU_B" SG_ 1180 BCmMToFailureStatus 0;
BA_ "GenSigTimeoutTime_HU_A" SG_ 1180 BCmMToFailureStatus 0;
BA_ "GenSigTimeoutMsg_HU_B" SG_ 1180 BCmMToFailureStatus 0;
BA_ "GenSigTimeoutMsg_HU_A" SG_ 1180 BCmMToFailureStatus 0;
BA_ "GenSigSendType" SG_ 1180 BCmMToFailureStatus 7;
BA_ "GenSigCycleTimeActive" SG_ 1180 BCmMToFailureStatus 100;
BA_ "GenSigCycleTime" SG_ 1180 BCmMToFailureStatus 100;
BA_ "GenSigTimeoutTime_HU_B" SG_ 1180 BCM_MM_Failure_Status 0;
BA_ "GenSigTimeoutTime_HU_A" SG_ 1180 BCM_MM_Failure_Status 0;
BA_ "GenSigTimeoutMsg_HU_B" SG_ 1180 BCM_MM_Failure_Status 0;
BA_ "GenSigTimeoutMsg_HU_A" SG_ 1180 BCM_MM_Failure_Status 0;
BA_ "GenSigSendType" SG_ 1180 BCM_MM_Failure_Status 7;
BA_ "GenSigCycleTimeActive" SG_ 1180 BCM_MM_Failure_Status 100;
BA_ "GenSigCycleTime" SG_ 1180 BCM_MM_Failure_Status 100;
VAL_ 1158 EPAS_Invalid_Failure_Status 3 "Reserved" 2 "Ageing in progress" 1 "fail detected and DTC memory" 0 "failure not detected" ;
VAL_ 1158 SAS_MTO_Failure_Status 3 "Reserved" 2 "Failure healed aging in progress" 1 "Failure detected; DTC in memory" 0 "Failure is not detected" ;
VAL_ 1158 EPAS_MRC_Failure_Status 3 "Reserved" 2 "Failurehealed Ageing in progress" 1 "Failure matured & DTC in memory" 0 "Faiulure is not detected " ;
VAL_ 1158 EPAS_CRC_Failure_Status 3 "Reserved" 2 "Failurehealed Ageing in progress" 1 "Failure matured & DTC in memory" 0 "Faiulure is not detected " ;
VAL_ 1158 EPAS_MTO_Failure_Status 3 "Reserved" 2 "Failure healed aging in progress" 1 "Failrue detected DTC in mem" 0 "Failure is not detected" ;
VAL_ 1158 ESP_BO_Failure_Status 3 "Reserved" 2 "Failure healed; aging in progress" 1 "Failure detected and DTC in memory" 0 "Failure not detected" ;
VAL_ 1158 ESP_EP_Failure_Status 3 "Reserved" 2 "Failure healed aging in progress" 1 "Failure is detected; DTC in mem" 0 "Failrue is not detected" ;
VAL_ 1158 DCS_MTO_Failure_Status 3 "Reserved" 2 "Failure Healed; aging in progress" 1 "Failure Detected; DTC in memory" 0 "Failure is not Detected" ;
VAL_ 1158 AMT_AT_DCT_MTO_Failure_Status 3 "Reserved" 2 "Failure healed Ageing in progress" 1 "Failure matured & DTC in memory" 0 "Failure is not detected" ;
VAL_ 1158 DCS_Invalid_Failure_Status 3 "Reserved" 2 "Failure healed Ageing in progress" 1 "Failure matured & DTC in memory" 0 "Failure is not detected" ;
VAL_ 1158 AMT_AT_DCT_Invalid_Failure__0000 3 "Reserved" 2 "Failure healed Ageing in progress" 1 "Failure matured & DTC in memory" 0 "Failure is not detected" ;
VAL_ 1158 EMsMToFailureStatus 3 "Historic DTC" 2 "Failurehealed Ageing in progress" 1 "Failure matured & DTC in memory" 0 "Faiulure is not detected " ;
VAL_ 1158 ESClMToFailureStatus 3 "Reserved" 2 "Failure healed Ageing in progress" 1 "Failure matured & DTC in memory" 0 "Failure is not detected" ;
VAL_ 1158 EMsInvalidFailureStatus 3 "Reserved" 2 "Failure healed Ageing in progress" 1 "Failure matured & DTC in memory" 0 "Failure is not detected" ;
VAL_ 1158 BCmMToFailureStatus 3 "Reserved" 2 "Failure healed aging in progress" 1 "Failure detected; DTC in memory" 0 "Failrue is not detected" ;
VAL_ 1158 BCM_Invalid_Status_Failure 3 "Reserved" 2 "Failure healed aging in progress" 1 "Failure detected DTC in memory" 0 "Failure is not detected" ;
VAL_ 1158 IPcInvalidFailureStatus 3 "Reserved" 2 "Failure healed Ageing in progress" 1 "Failure matured & DTC in memory" 0 "Failure is not detected" ;
VAL_ 1158 IPcMToFailureStatus 3 "Reserved" 2 "Failure healed Ageing in progress" 1 "Failure matured & DTC in memory" 0 "Failure is not detected" ;
VAL_ 1158 EMsCRcFailureStatus 3 "Reserved" 2 "Failure healed Ageing in progress" 1 "Failure matured & DTC in memory" 0 "Failure is not detected" ;
VAL_ 1158 EMsMRcFailureStatus 3 "Reserved" 2 "Failure healed Ageing in progress" 1 "Failure matured & DTC in memory" 0 "Failure is not detected" ;
VAL_ 1159 FCmMToFailureStatus 3 "Reserved" 2 "Failure is cleared and DTC is moved to history." 1 "Failure is detected and active DTC is stored in the error memory." 0 "Failure is currently not detected." ;
VAL_ 1159 SRS_MTO_Failure_Status 3 "Reserved" 2 "Failure healed aging in progress" 1 "Failure detected DTC in Memory" 0 "Failure is not detected" ;
VAL_ 1159 BCM_Invalid_Status_Failure 3 "Reserved" 2 "Failure healed aging in progress" 1 "Failure detected DTC in memory" 0 "Failure is not detected" ;
VAL_ 1159 BCM_MTO_Failure_status 3 "Reserved" 2 "Failure is cleared and DTC is moved to history." 1 "Failure is detected and active DTC is stored in the error memory." 0 "Failure is currently not detected." ;
VAL_ 1159 EMS_Invalid_Failure_Status 3 "Reserved" 2 "Failure healed aging in progress" 1 "Failure detected DTC in memory" 0 "Failure is not detected" ;
VAL_ 1159 EMS_MTO_Failure_Status 3 "Reserved" 2 "Failure is cleared and DTC is moved to history." 1 "Failure is detected and active DTC is stored in the error memory." 0 "Failure is currently not detected." ;
VAL_ 1159 IPC_Invalid_Failure_Status 3 "Reserved" 2 "Failure healed Ageing in progress" 1 "Failure matured & DTC in memory" 0 "Failure is not detected" ;
VAL_ 1159 ESP_Invalid_Failure_Status 3 "Reserved" 2 "Ageing in progress" 1 "fail detected and DTC  in memory" 0 "failure not detected" ;
VAL_ 1159 AT_BO_Failure_Status 3 "Reserved" 2 "Failure healed Ageing in progress" 1 "Failure matured & DTC in memory" 0 "Failure is not detected" ;
VAL_ 1159 EMS_MRC_Failure_Status 3 "Reserved" 2 "Failure healed Ageing in progress" 1 "Failure matured & DTC in memory" 0 "Failure is not detected" ;
VAL_ 1159 EMS_CRC_Failure_Status 3 "Reserved" 2 "Failure healed Ageing in progress" 1 "Failure matured & DTC in memory" 0 "Failure is not detected" ;
VAL_ 1159 IPC_MTO_Failure_Status 3 "Reserved" 2 "Failure healed Ageing in progress" 1 "Failure matured & DTC in memory" 0 "Failure is not detected" ;
VAL_ 1159 AT_EP_Failure_Status 3 "Reserved" 2 "Failure healed Ageing in progress" 1 "Failure matured & DTC in memory" 0 "Failure is not detected" ;
VAL_ 1159 ESP_MTO_Failure_Status 3 "Reserved" 2 "Failure healed aging in progress" 1 "Failrue detected DTC in memory" 0 "Failure is not detected" ;
VAL_ 1160 Telematics_MTO_Failure_status 3 "Reserved" 2 "Failure healed aging in progress" 1 "Failure matured & DTC in memory" 0 "Failure is not detected" ;
VAL_ 1160 Telematics_Invalid_Failure__0001 3 "Reserved" 2 "Failure healed aging in progress" 1 "Failure matured & DTC in memory" 0 "Failure is not detected" ;
VAL_ 1160 BCmMToFailureStatus 3 "Reserved" 2 "Failure healed aging in progress" 1 "Failure detected; DTC in memory" 0 "Failrue is not detected" ;
VAL_ 1160 BCmInvalidFailureStatus 3 "Reserved" 2 "Failure healed Ageing in progress" 1 "Failure matured & DTC in memory" 0 "Failure is not detected" ;
VAL_ 1160 DCS_MTO_Failure_Status 3 "Reserved" 2 "Failure Healed; aging in progress" 1 "Failure Detected; DTC in memory" 0 "Failure is not Detected" ;
VAL_ 1160 DCS_Invalid_Failure_Status 3 "Reserved" 2 "Failure healed Ageing in progress" 1 "Failure matured & DTC in memory" 0 "Failure is not detected" ;
VAL_ 1160 AMT_DCT_EP_Failure_Status 3 "Reserved" 2 "Failurehealed Ageing in progress" 1 "Failure matured & DTC in memory" 0 "Faiulure is not detected " ;
VAL_ 1160 AMT_DCT_BO_Failure_Status 3 "Reserved" 2 "Failurehealed Ageing in progress" 1 "Failure matured & DTC in memory" 0 "Faiulure is not detected " ;
VAL_ 1160 EMsMToFailureStatus 3 "Historic DTC" 2 "Failurehealed Ageing in progress" 1 "Failure matured & DTC in memory" 0 "Faiulure is not detected " ;
VAL_ 1160 EMsInvalidFailureStatus 3 "Reserved" 2 "Failure healed Ageing in progress" 1 "Failure matured & DTC in memory" 0 "Failure is not detected" ;
VAL_ 1160 IPC_MRC_failure_status 3 "Reserved" 2 "Failure healed Ageing in progress" 1 "Failure matured & DTC in memory" 0 "Failure is not detected" ;
VAL_ 1160 IPcMToFailureStatus 3 "Reserved" 2 "Failure healed Ageing in progress" 1 "Failure matured & DTC in memory" 0 "Failure is not detected" ;
VAL_ 1160 IPcInvalidFailureStatus 3 "Reserved" 2 "Failure healed Ageing in progress" 1 "Failure matured & DTC in memory" 0 "Failure is not detected" ;
VAL_ 1160 ESP_Invalid_Failure_Status 3 "Reserved" 2 "Failure healed aging in progress" 1 "Failure detected DTC in memory" 0 "Failure is not detected" ;
VAL_ 1160 EMsMRcFailureStatus 3 "Reserved" 2 "Failure healed Ageing in progress" 1 "Failure matured & DTC in memory" 0 "Failure is not detected" ;
VAL_ 1160 EMsCRcFailureStatus 3 "Reserved" 2 "Failure healed Ageing in progress" 1 "Failure matured & DTC in memory" 0 "Failure is not detected" ;
VAL_ 1160 IPC_CRC_failure_status 3 "Reserved" 2 "Failure healed Ageing in progress" 1 "Failure matured & DTC in memory" 0 "Failure is not detected" ;
VAL_ 1160 ESpMToFailureStatus 3 "Reserved" 2 "Failure healed aging in progress" 1 "Failrue detected DTC in memory" 0 "Failure is not detected" ;
VAL_ 1161 Telematics_MTO_Failure_status 3 "Reserved" 2 "Failure healed aging in progress" 1 "Failure matured & DTC in memory" 0 "Failure is not detected" ;
VAL_ 1161 Telematics_Invalid_Failure__0002 3 "Reserved" 2 "Failure healed aging in progress" 1 "Failure matured & DTC in memory" 0 "Failure is not detected" ;
VAL_ 1161 BCmInvalidFailureStatus 3 "Reserved" 2 "Failure healed Ageing in progress" 1 "Failure matured & DTC in memory" 0 "Failure is not detected" ;
VAL_ 1161 EMsCRcFailureStatus 3 "Reserved" 2 "Failure healed Ageing in progress" 1 "Failure matured & DTC in memory" 0 "Failure is not detected" ;
VAL_ 1161 ESpMToFailureStatus 3 "Reserved" 2 "Failure healed aging in progress" 1 "Failrue detected DTC in memory" 0 "Failure is not detected" ;
VAL_ 1161 ESpInvalidFailureStatus 3 "Reserved" 2 "Failure healed ageing in progress" 1 "fail detected and DTC  in memory" 0 "failure not detected" ;
VAL_ 1161 BCmMToFailureStatus 3 "Reserved" 2 "Failure healed aging in progress" 1 "Failure detected; DTC in memory" 0 "Failrue is not detected" ;
VAL_ 1161 IPcInvalidFailureStatus 3 "Reserved" 2 "Failure healed Ageing in progress" 1 "Failure matured & DTC in memory" 0 "Failure is not detected" ;
VAL_ 1161 EMsMToFailureStatus 3 "Historic DTC" 2 "Failurehealed Ageing in progress" 1 "Failure matured & DTC in memory" 0 "Faiulure is not detected " ;
VAL_ 1161 EMsInvalidFailureStatus 3 "Reserved" 2 "Failure healed Ageing in progress" 1 "Failure matured & DTC in memory" 0 "Failure is not detected" ;
VAL_ 1161 IPC_MRC_failure_status 3 "Reserved" 2 "Failure healed Ageing in progress" 1 "Failure matured & DTC in memory" 0 "Failure is not detected" ;
VAL_ 1161 IPC_CRC_failure_status 3 "Reserved" 2 "Failure healed Ageing in progress" 1 "Failure matured & DTC in memory" 0 "Failure is not detected" ;
VAL_ 1161 IPcMToFailureStatus 3 "Reserved" 2 "Failure healed Ageing in progress" 1 "Failure matured & DTC in memory" 0 "Failure is not detected" ;
VAL_ 1162 VICM_BO_Failure_Status 3 "Reserved" 2 "Failurehealed Ageing in progress" 1 "Failure matured & DTC in memory" 0 "Faiulure is not detected " ;
VAL_ 1162 VICM_EP_Failure_Status 3 "Reserved" 2 "Failurehealed Ageing in progress" 1 "Failure matured & DTC in memory" 0 "Faiulure is not detected " ;
VAL_ 1162 EMS_MM_Failure_Status 3 "Fail healed & DTC history" 2 "Ageing in progress " 1 "Fail detected & DTC memory" 0 "Failure not detected" ;
VAL_ 1162 EMsMToFailureStatus 3 "Historic DTC" 2 "Failurehealed Ageing in progress" 1 "Failure matured & DTC in memory" 0 "Faiulure is not detected " ;
VAL_ 1164 FCmInvalidFailureStatus 3 "Reserved" 2 "Failure healed ageing in progress" 1 "fail detected and DTC  in memory" 0 "failure not detected" ;
VAL_ 1164 FCmMToFailureStatus 3 "Reserved" 2 "Failure is cleared and DTC is moved to history." 1 "Failure is detected and active DTC is stored in the error memory." 0 "Failure is currently not detected." ;
VAL_ 1164 VCUMToFailureStatus 3 "Reserved" 2 "Failure healed aging in progress" 1 "Failure matured & DTC in memory" 0 "Failure is not detected" ;
VAL_ 1164 VCUInvalidFailureStatus 3 "Reserved" 2 "Failure healed aging in progress" 1 "Failure matured & DTC in memory" 0 "Failure is not detected" ;
VAL_ 1164 EMsMToFailureStatus 3 "Historic DTC" 2 "Failurehealed Ageing in progress" 1 "Failure matured & DTC in memory" 0 "Faiulure is not detected " ;
VAL_ 1164 EMsInvalidFailureStatus 3 "Reserved" 2 "Failure healed Ageing in progress" 1 "Failure matured & DTC in memory" 0 "Failure is not detected" ;
VAL_ 1164 ESP_MTO_Failure_Status 3 "Reserved" 2 "Failure healed aging in progress" 1 "Failrue detected DTC in memory" 0 "Failure is not detected" ;
VAL_ 1164 ESP_Invalid_Failure_Status 3 "Reserved" 2 "Ageing in progress" 1 "fail detected and DTC  in memory" 0 "failure not detected" ;
VAL_ 1164 SRS_BO_Failure_Status 3 "Reserved" 2 "Failurehealed Ageing in progress" 1 "Failure matured & DTC in memory" 0 "Faiulure is not detected " ;
VAL_ 1164 SRS_EP_Failure_Status 3 "Reserved" 2 "Failurehealed Ageing in progress" 1 "Failure matured & DTC in memory" 0 "Faiulure is not detected " ;
VAL_ 1164 IPcMToFailureStatus 3 "Reserved" 2 "Failure healed Ageing in progress" 1 "Failure matured & DTC in memory" 0 "Failure is not detected" ;
VAL_ 1164 IPcInvalidFailureStatus 3 "Reserved" 2 "Failure healed Ageing in progress" 1 "Failure matured & DTC in memory" 0 "Failure is not detected" ;
VAL_ 1164 BCmMToFailureStatus 3 "Reserved" 2 "Failure healed aging in progress" 1 "Failure detected; DTC in memory" 0 "Failrue is not detected" ;
VAL_ 1167 EEM_BO_Failure_Status 3 "Reserved" 2 "Failurehealed Ageing in progress" 1 "Failure matured & DTC in memory" 0 "Faiulure is not detected " ;
VAL_ 1167 EEM_EP_Failure_Status 3 "Reserved" 2 "Failurehealed Ageing in progress" 1 "Failure matured & DTC in memory" 0 "Faiulure is not detected " ;
VAL_ 1167 EMsMToFailureStatus 3 "Historic DTC" 2 "Failurehealed Ageing in progress" 1 "Failure matured & DTC in memory" 0 "Faiulure is not detected " ;
VAL_ 1167 EMS_MM_Failure_Status 3 "Fail healed & DTC history" 2 "Ageing in progress " 1 "Fail detected & DTC memory" 0 "Failure not detected" ;
VAL_ 1167 EMsInvalidFailureStatus 3 "Reserved" 2 "Failure healed Ageing in progress" 1 "Failure matured & DTC in memory" 0 "Failure is not detected" ;
VAL_ 1167 IPcMToFailureStatus 3 "Reserved" 2 "Failure healed Ageing in progress" 1 "Failure matured & DTC in memory" 0 "Failure is not detected" ;
VAL_ 1167 IPC_MM_Failure_Status 3 "Reserved" 2 "Failure healed Ageing in progress" 1 "Failure matured & DTC in memory" 0 "Failure is not detected" ;
VAL_ 1167 IPcInvalidFailureStatus 3 "Reserved" 2 "Failure healed Ageing in progress" 1 "Failure matured & DTC in memory" 0 "Failure is not detected" ;
VAL_ 1167 AMT_AT_DCT_MTO_Failure_Status 3 "Reserved" 2 "Failure healed Ageing in progress" 1 "Failure matured & DTC in memory" 0 "Failure is not detected" ;
VAL_ 1167 AMT_AT_DCT_MM_Failure_Status 3 "Reserved" 2 "Failure healed Ageing in progress" 1 "Failure matured & DTC in memory" 0 "Failure is not detected" ;
VAL_ 1167 AMT_AT_DCT_Invalid_Failure__0001 3 "Reserved" 2 "Failure healed Ageing in progress" 1 "Failure matured & DTC in memory" 0 "Failure is not detected" ;
VAL_ 1168 SRR_MTO_Failure_Status 3 "Reserved" 2 "Failure healed aging in progress" 1 "Failrue detected DTC in memory" 0 "Failure is not detected" ;
VAL_ 1168 FCmMToFailureStatus 3 "Reserved" 2 "Failure is cleared and DTC is moved to history." 1 "Failure is detected and active DTC is stored in the error memory." 0 "Failure is currently not detected." ;
VAL_ 1168 AMT_AT_DCT_MTO_Failure_Status 3 "Reserved" 2 "Failure healed Ageing in progress" 1 "Failure matured & DTC in memory" 0 "Failure is not detected" ;
VAL_ 1168 PEPS_MRC_Failure_Status 3 "Reserved" 2 "Failurehealed Ageing in progress" 1 "Failure matured & DTC in memory" 0 "Faiulure is not detected " ;
VAL_ 1168 AMT_AT_DCT_Invalid_Failure__0002 3 "Reserved" 2 "Failure healed Ageing in progress" 1 "Failure matured & DTC in memory" 0 "Failure is not detected" ;
VAL_ 1168 PEPS_CRC_Failure_Status 3 "Reserved" 2 "Failurehealed Ageing in progress" 1 "Failure matured & DTC in memory" 0 "Faiulure is not detected " ;
VAL_ 1168 BCM_EP_Failure_Status 3 "Reserved" 2 "Failure healed Ageing in progress" 1 "Failure matured & DTC in memory" 0 "Failure is not detected" ;
VAL_ 1168 EMsInvalidFailureStatus 3 "Reserved" 2 "Failure healed Ageing in progress" 1 "Failure matured & DTC in memory" 0 "Failure is not detected" ;
VAL_ 1168 EMsMToFailureStatus 3 "Historic DTC" 2 "Failurehealed Ageing in progress" 1 "Failure matured & DTC in memory" 0 "Faiulure is not detected " ;
VAL_ 1168 BCM_BO_Failure_Status 3 "Reserved" 2 "Failure healed Ageing in progress" 1 "Failure matured & DTC in memory" 0 "Failure is not detected" ;
VAL_ 1168 IPcMToFailureStatus 3 "Reserved" 2 "Failure healed Ageing in progress" 1 "Failure matured & DTC in memory" 0 "Failure is not detected" ;
VAL_ 1168 IPcInvalidFailureStatus 3 "Reserved" 2 "Failure healed Ageing in progress" 1 "Failure matured & DTC in memory" 0 "Failure is not detected" ;
VAL_ 1168 SRS_MTO_Failure_Status 3 "Reserved" 2 "Failure healed aging in progress" 1 "Failure detected DTC in Memory" 0 "Failure is not detected" ;
VAL_ 1168 VICM_Invalid_Failure_Status 3 "Reserved" 2 "Failure healed Ageing in progress" 1 "Failure matured & DTC in memory" 0 "Failure is not detected" ;
VAL_ 1168 CCM_MTO_Failure_Status 3 "Reserved" 2 "Failure healed & Ageing in progress" 1 "failure is detected & DTC in memeory" 0 "Failure is not detected" ;
VAL_ 1168 CCM_Invalid_Failure_Status 3 "Reserved" 2 "Failure healed Ageing in progress" 1 "Failure matured & DTC in memory" 0 "Failure is not detected" ;
VAL_ 1168 VICM_MTO_Failure_Status 3 "Reserved" 2 "Failure healed aging in progress" 1 "Failure detected DTC in Memory" 0 "Failure is not detected" ;
VAL_ 1168 PEPS_Invalid_failure_status 3 "Reserved" 2 "Failure healed Ageing in progress" 1 "Failure matured & DTC in memory" 0 "Failure is not detected" ;
VAL_ 1168 PEPS_MTO_Failure_Status 3 "Reserved" 2 "Failure healed aging in progress" 1 "Failure detected DTC in Memory" 0 "Failure is not detected" ;
VAL_ 1168 Trailer_MTO_Failure_Status 3 "Reserved" 2 "Failure healed aging in progress" 1 "Failure detected DTC in Memory" 0 "Failure is not detected" ;
VAL_ 1168 TPMS_MTO_Failure_status 3 "Reseved" 2 "Failure healed and ageing in process" 1 "Failure is detected and DTC in memory" 0 "Failure is not detected" ;
VAL_ 1169 Telematics_Invalid_FailureStatus 3 "Reserved" 2 "Failure healed aging in progress" 1 "Failure matured & DTC in memory" 0 "Failure is not detected" ;
VAL_ 1169 VCUMToFailureStatus 3 "Reserved" 2 "Failure healed aging in progress" 1 "Failure matured & DTC in memory" 0 "Failure is not detected" ;
VAL_ 1169 VCUInvalidFailureStatus 3 "Reserved" 2 "Failure healed aging in progress" 1 "Failure matured & DTC in memory" 0 "Failure is not detected" ;
VAL_ 1169 Telematics_MTO_Failure_status 3 "Reserved" 2 "Failure healed aging in progress" 1 "Failure matured & DTC in memory" 0 "Failure is not detected" ;
VAL_ 1169 EPAS_MTO_Failure_Status 3 "Reserved" 2 "Failure healed aging in progress" 1 "Failrue detected DTC in mem" 0 "Failure is not detected" ;
VAL_ 1169 EPAS_Invalid_Failure_Status 3 "Reserved" 2 "Ageing in progress" 1 "fail detected and DTC memory" 0 "failure not detected" ;
VAL_ 1169 ESP_MTO_Failure_Status 3 "Reserved" 2 "Failure healed aging in progress" 1 "Failrue detected DTC in memory" 0 "Failure is not detected" ;
VAL_ 1169 ESP_Invalid_Failure_Status 3 "Reserved" 2 "Ageing in progress" 1 "fail detected and DTC  in memory" 0 "failure not detected" ;
VAL_ 1169 HU_MTO_Failure_Status 3 "Reserved" 2 "Failure healed aging in progress" 1 "Failrue detected DTC in mem" 0 "Failure is not detected" ;
VAL_ 1169 SAS_MTO_Failure_Status 3 "Reserved" 2 "Failure healed aging in progress" 1 "Failure detected; DTC in memory" 0 "Failure is not detected" ;
VAL_ 1170 Telematics_MTO_Failure_status 3 "Reserved" 2 "Failure healed aging in progress" 1 "Failure matured & DTC in memory" 0 "Failure is not detected" ;
VAL_ 1170 Telematics_Invalid_FailureStatus 3 "Reserved" 2 "Failure healed aging in progress" 1 "Failure matured & DTC in memory" 0 "Failure is not detected" ;
VAL_ 1170 BCmInvalidFailureStatus 3 "Reserved" 2 "Failure healed Ageing in progress" 1 "Failure matured & DTC in memory" 0 "Failure is not detected" ;
VAL_ 1170 BCmMToFailureStatus 3 "Reserved" 2 "Failure healed aging in progress" 1 "Failure detected; DTC in memory" 0 "Failrue is not detected" ;
VAL_ 1170 CCM_EP_Failure_Status 3 "Reserved" 2 "Failurehealed Ageing in progress" 1 "Failure matured & DTC in memory" 0 "Faiulure is not detected " ;
VAL_ 1170 CCM_BO_Failure_Status 3 "Reserved" 2 "Failure healed; aging in progress" 1 "Failure detected and DTC in memory" 0 "Failure not detected" ;
VAL_ 1170 EMsMToFailureStatus 3 "Historic DTC" 2 "Failurehealed Ageing in progress" 1 "Failure matured & DTC in memory" 0 "Faiulure is not detected " ;
VAL_ 1170 EMsInvalidFailureStatus 3 "Reserved" 2 "Failure healed Ageing in progress" 1 "Failure matured & DTC in memory" 0 "Failure is not detected" ;
VAL_ 1170 IPcInvalidFailureStatus 3 "Reserved" 2 "Failure healed Ageing in progress" 1 "Failure matured & DTC in memory" 0 "Failure is not detected" ;
VAL_ 1170 HU_MTO_Failure_Status 3 "Reserved" 2 "Failure healed aging in progress" 1 "Failrue detected DTC in mem" 0 "Failure is not detected" ;
VAL_ 1170 IPcMToFailureStatus 3 "Reserved" 2 "Failure healed Ageing in progress" 1 "Failure matured & DTC in memory" 0 "Failure is not detected" ;
VAL_ 1173 SRR_MTO_Failure_Status 3 "Reserved" 2 "Failure healed aging in progress" 1 "Failrue detected DTC in memory" 0 "Failure is not detected" ;
VAL_ 1173 FCmMToFailureStatus 3 "Reserved" 2 "Failure is cleared and DTC is moved to history." 1 "Failure is detected and active DTC is stored in the error memory." 0 "Failure is currently not detected." ;
VAL_ 1173 Telematics_Invalid_FailureStatus 3 "Reserved" 2 "Failure healed aging in progress" 1 "Failure matured & DTC in memory" 0 "Failure is not detected" ;
VAL_ 1173 VCUMToFailureStatus 3 "Reserved" 2 "Failure healed aging in progress" 1 "Failure matured & DTC in memory" 0 "Failure is not detected" ;
VAL_ 1173 VCUInvalidFailureStatus 3 "Reserved" 2 "Failure healed aging in progress" 1 "Failure matured & DTC in memory" 0 "Failure is not detected" ;
VAL_ 1173 Telematics_MTO_Failure_status 3 "Reserved" 2 "Failure healed aging in progress" 1 "Failure matured & DTC in memory" 0 "Failure is not detected" ;
VAL_ 1173 EMsInvalidFailureStatus 3 "Reserved" 2 "Failure healed Ageing in progress" 1 "Failure matured & DTC in memory" 0 "Failure is not detected" ;
VAL_ 1173 AMT_AT_DCT_MTO_Failure_Status 3 "Reserved" 2 "Failure healed Ageing in progress" 1 "Failure matured & DTC in memory" 0 "Failure is not detected" ;
VAL_ 1173 AMT_AT_DCT_Invalid_Failure__0003 3 "Reserved" 2 "Failure healed Ageing in progress" 1 "Failure matured & DTC in memory" 0 "Failure is not detected" ;
VAL_ 1173 ESpMToFailureStatus 3 "Reserved" 2 "Failure healed aging in progress" 1 "Failrue detected DTC in memory" 0 "Failure is not detected" ;
VAL_ 1173 ESpInvalidFailureStatus 3 "Reserved" 2 "Failure healed ageing in progress" 1 "fail detected and DTC  in memory" 0 "failure not detected" ;
VAL_ 1173 CCM_Invalid_Failure_Status 3 "Reserved" 2 "Failure healed Ageing in progress" 1 "Failure matured & DTC in memory" 0 "Failure is not detected" ;
VAL_ 1173 SRS_MTO_Failure_Status 3 "Reserved" 2 "Failure healed aging in progress" 1 "Failure detected DTC in Memory" 0 "Failure is not detected" ;
VAL_ 1173 EMsMToFailureStatus 3 "Historic DTC" 2 "Failurehealed Ageing in progress" 1 "Failure matured & DTC in memory" 0 "Faiulure is not detected " ;
VAL_ 1173 PDC_MTO_Failure_Status 3 "Reserved" 2 "Failure healed aging in progress" 1 "Failrue detected DTC in memory" 0 "Failure is not detected" ;
VAL_ 1173 IPcMToFailureStatus 3 "Reserved" 2 "Failure healed Ageing in progress" 1 "Failure matured & DTC in memory" 0 "Failure is not detected" ;
VAL_ 1173 IPcInvalidFailureStatus 3 "Reserved" 2 "Failure healed Ageing in progress" 1 "Failure matured & DTC in memory" 0 "Failure is not detected" ;
VAL_ 1173 PDC_Invalid_Failure_Status 3 "Reserved" 2 "Failure healed Ageing in progress" 1 "Failure matured & DTC in memory" 0 "Failure is not detected" ;
VAL_ 1173 SAS_Invalid_Failure_Status 3 "Reserved" 2 "Failure healed Ageing in progress" 1 "Failure matured & DTC in memory" 0 "Failure is not detected" ;
VAL_ 1173 SAS_MTO_Failure_Status 3 "Reserved" 2 "Failure healed aging in progress" 1 "Failure detected; DTC in memory" 0 "Failure is not detected" ;
VAL_ 1173 EPAS_MTO_Failure_Status 3 "Reserved" 2 "Failure healed aging in progress" 1 "Failrue detected DTC in mem" 0 "Failure is not detected" ;
VAL_ 1173 EPAS_Invalid_Failure_Status 3 "Reserved" 2 "Ageing in progress" 1 "fail detected and DTC memory" 0 "failure not detected" ;
VAL_ 1173 TPMS_MTO_Failure_status 3 "Reserved" 2 "Failure healed and ageing in process" 1 "Failure is detected and DTC in memory" 0 "Failure is not detected" ;
VAL_ 1173 CCM_MTO_Failure_Status 3 "Reserved" 2 "Failure healed & Ageing in progress" 1 "failure is detected & DTC in memeory" 0 "Failure is not detected" ;
VAL_ 1173 HU_EP_Failure_Status 3 "Reserved" 2 "Failurehealed Ageing in progress" 1 "Failure matured & DTC in memory" 0 "Faiulure is not detected " ;
VAL_ 1173 PEPS_MTO_Failure_Status 3 "Reserved" 2 "Failure healed aging in progress" 1 "Failure detected DTC in Memory" 0 "Failure is not detected" ;
VAL_ 1173 BCmMToFailureStatus 3 "Reserved" 2 "Failure healed aging in progress" 1 "Failure detected; DTC in memory" 0 "Failrue is not detected" ;
VAL_ 1173 HU_BO_Failure_Status 3 "Reserved" 2 "Failure healed; aging in progress" 1 "Failure detected and DTC in memory" 0 "Failure not detected" ;
VAL_ 1174 PEPS_Invalid_failure_status 3 "Reserved" 2 "Failure healed Ageing in progress" 1 "Failure matured & DTC in memory" 0 "Failure is not detected" ;
VAL_ 1174 BCM_Invalid_Status_Failure 3 "Reserved" 2 "Failure healed aging in progress" 1 "Failure detected DTC in memory" 0 "Failure is not detected" ;
VAL_ 1176 FCmInvalidFailureStatus 3 "Reserved" 2 "Failure healed ageing in progress" 1 "fail detected and DTC  in memory" 0 "failure not detected" ;
VAL_ 1176 SRR_MTO_Failure_Status 3 "Reserved" 2 "Failure healed aging in progress" 1 "Failrue detected DTC in memory" 0 "Failure is not detected" ;
VAL_ 1176 FCmMToFailureStatus 3 "Reserved" 2 "Failure is cleared and DTC is moved to history." 1 "Failure is detected and active DTC is stored in the error memory." 0 "Failure is currently not detected." ;
VAL_ 1176 BCM_Invalid_Status_Failure 3 "Reserved" 2 "Failure healed aging in progress" 1 "Failure detected DTC in memory" 0 "Failure is not detected" ;
VAL_ 1176 BCmMToFailureStatus 3 "Reserved" 2 "Failure healed aging in progress" 1 "Failure detected; DTC in memory" 0 "Failrue is not detected" ;
VAL_ 1176 CCM_Invalid_Failure_Status 3 "Reserved" 2 "Failure healed Ageing in progress" 1 "Failure matured & DTC in memory" 0 "Failure is not detected" ;
VAL_ 1176 CCM_MTO_Failure_Status 3 "Reserved" 2 "Failure healed & Ageing in progress" 1 "failure is detected & DTC in memeory" 0 "Failure is not detected" ;
VAL_ 1176 EMsInvalidFailureStatus 3 "Reserved" 2 "Failure healed Ageing in progress" 1 "Failure matured & DTC in memory" 0 "Failure is not detected" ;
VAL_ 1176 EMsMToFailureStatus 3 "Historic DTC" 2 "Failurehealed Ageing in progress" 1 "Failure matured & DTC in memory" 0 "Faiulure is not detected " ;
VAL_ 1176 EPAS_Invalid_Failure_Status 3 "Reserved" 2 "Ageing in progress" 1 "fail detected and DTC memory" 0 "failure not detected" ;
VAL_ 1176 EPAS_MTO_Failure_Status 3 "Reserved" 2 "Failure healed aging in progress" 1 "Failrue detected DTC in mem" 0 "Failure is not detected" ;
VAL_ 1176 ESpInvalidFailureStatus 3 "Reserved" 2 "Failure healed ageing in progress" 1 "fail detected and DTC  in memory" 0 "failure not detected" ;
VAL_ 1176 ESpMToFailureStatus 3 "Reserved" 2 "Failure healed aging in progress" 1 "Failrue detected DTC in memory" 0 "Failure is not detected" ;
VAL_ 1176 HU_MTO_Failure_Status 3 "Reserved" 2 "Failure healed aging in progress" 1 "Failrue detected DTC in mem" 0 "Failure is not detected" ;
VAL_ 1176 IPC_BO_Failure_Status 3 "Reserved" 2 "Failurehealed Ageing in progress" 1 "Failure matured & DTC in memory" 0 "Faiulure is not detected " ;
VAL_ 1176 IPC_EP_Failure_Status 3 "Reserved" 2 "Ageing in progress" 1 "Fail detected & DTC  in memory" 0 "Failure not detected" ;
VAL_ 1176 SRS_MTO_Failure_Status 3 "Reserved" 2 "Failure healed aging in progress" 1 "Failure detected DTC in Memory" 0 "Failure is not detected" ;
VAL_ 1176 AMT_AT_DCT_Invalid_Failure__0004 3 "Reserved" 2 "Failure healed Ageing in progress" 1 "Failure matured & DTC in memory" 0 "Failure is not detected" ;
VAL_ 1176 AMT_AT_DCT_MTO_Failure_Status 3 "Reserved" 2 "Failure healed Ageing in progress" 1 "Failure matured & DTC in memory" 0 "Failure is not detected" ;
VAL_ 1176 TPMS_MTO_Failure_status 3 "Reseved" 2 "Failure healed and ageing in process" 1 "Failure is detected and DTC in memory" 0 "Failure is not detected" ;
VAL_ 1177 LINA_EP_Failure_Status 3 "Reserved" 2 "Failure healed aging in progress" 1 "Failure is detected; DTC in mem" 0 "Failrue is not detected" ;
VAL_ 1177 LINA_DustSensor_MTO_Failure_Stat 3 "Reserved" 2 "Failure healed aging in progress" 1 "Failure detected DTC in Memory" 0 "Failure is not detected" ;
VAL_ 1177 LINA_BO_Failure_Status 3 "Reserved" 2 "Failure healed; aging in progress" 1 "Failure detected and DTC in memory" 0 "Failure not detected" ;
VAL_ 1177 DCS_MTO_Failure_Status 3 "Reserved" 2 "Failure Healed; aging in progress" 1 "Failure Detected; DTC in memory" 0 "Failure is not Detected" ;
VAL_ 1177 ESClMToFailureStatus 3 "Reserved" 2 "Failure healed Ageing in progress" 1 "Failure matured & DTC in memory" 0 "Failure is not detected" ;
VAL_ 1177 PEPS_Invalid_failure_status 3 "Reserved" 2 "Failure healed Ageing in progress" 1 "Failure matured & DTC in memory" 0 "Failure is not detected" ;
VAL_ 1177 PEPS_MTO_Failure_Status 3 "Reserved" 2 "Failure healed aging in progress" 1 "Failure detected DTC in Memory" 0 "Failure is not detected" ;
VAL_ 1177 SAS_MTO_Failure_Status 3 "Reserved" 2 "Failure healed aging in progress" 1 "Failure detected; DTC in memory" 0 "Failure is not detected" ;
VAL_ 1178 Telematics_Invalid_Failure__0003 3 "Reserved" 2 "Failure healed aging in progress" 1 "Failure matured & DTC in memory" 0 "Failure is not detected" ;
VAL_ 1178 Telematics_MTO_Failure 3 "Reserved" 2 "Failure healed aging in progress" 1 "Failure matured & DTC in memory" 0 "Failure is not detected" ;
VAL_ 1178 VCUInvalidFailureStatus 3 "Reserved" 2 "Failure healed aging in progress" 1 "Failure matured & DTC in memory" 0 "Failure is not detected" ;
VAL_ 1178 VCUMToFailureStatus 3 "Reserved" 2 "Failure healed aging in progress" 1 "Failure matured & DTC in memory" 0 "Failure is not detected" ;
VAL_ 1178 PEPsEpFailureStatus 3 "Reserved" 2 "Failurehealed Ageing in progress" 1 "Failure matured & DTC in memory" 0 "Faiulure is not detected " ;
VAL_ 1178 PEPsBoFailureStatus 3 "Reserved" 2 "Failurehealed Ageing in progress" 1 "Failure matured & DTC in memory" 0 "Faiulure is not detected " ;
VAL_ 1178 ESClInvalidFailureStatus 3 "Reserved" 2 "Failure healed Ageing in progress" 1 "Failure matured & DTC in memory" 0 "Failure is not detected" ;
VAL_ 1178 ESClMToFailureStatus 3 "Reserved" 2 "Failure healed Ageing in progress" 1 "Failure matured & DTC in memory" 0 "Failure is not detected" ;
VAL_ 1178 BCmCRcFailureStatus 3 "Reserved" 2 "Failure healed Ageing in progress" 1 "Failure matured & DTC in memory" 0 "Failure is not detected" ;
VAL_ 1178 BCmMRcFailureStatus 3 "Reserved" 2 "Failure healed Ageing in progress" 1 "Failure matured & DTC in memory" 0 "Failure is not detected" ;
VAL_ 1178 BCmInvalidFailureStatus 3 "Reserved" 2 "Failure healed Ageing in progress" 1 "Failure matured & DTC in memory" 0 "Failure is not detected" ;
VAL_ 1178 BCmMToFailureStatus 3 "Reserved" 2 "Failure healed aging in progress" 1 "Failure detected; DTC in memory" 0 "Failrue is not detected" ;
VAL_ 1178 ESpCRcFailureStatus 3 "Reserved" 2 "Failure healed Ageing in progress" 1 "Failure matured & DTC in memory" 0 "Failure is not detected" ;
VAL_ 1178 ESpMRcFailureStutus 3 "Reserved" 2 "Failure healed Ageing in progress" 1 "Failure matured & DTC in memory" 0 "Failure is not detected" ;
VAL_ 1178 ESpInvalidFailureStatus 3 "Reserved" 2 "Failure healed ageing in progress" 1 "fail detected and DTC  in memory" 0 "failure not detected" ;
VAL_ 1178 ESpMToFailureStatus 3 "Reserved" 2 "Failure healed aging in progress" 1 "Failrue detected DTC in memory" 0 "Failure is not detected" ;
VAL_ 1178 EMsCRcFailureStatus 3 "Reserved" 2 "Failure healed Ageing in progress" 1 "Failure matured & DTC in memory" 0 "Failure is not detected" ;
VAL_ 1178 EMsMRcFailureStatus 3 "Reserved" 2 "Failure healed Ageing in progress" 1 "Failure matured & DTC in memory" 0 "Failure is not detected" ;
VAL_ 1178 EMsInvalidFailureStatus 3 "Reserved" 2 "Failure healed Ageing in progress" 1 "Failure matured & DTC in memory" 0 "Failure is not detected" ;
VAL_ 1178 EMsMToFailureStatus 3 "Historic DTC" 2 "Failurehealed Ageing in progress" 1 "Failure matured & DTC in memory" 0 "Faiulure is not detected " ;
VAL_ 1178 AMT_AT_DCT_MTO_Failure_Status 3 "Reserved" 2 "Failure healed Ageing in progress" 1 "Failure matured & DTC in memory" 0 "Failure is not detected" ;
VAL_ 1178 AMT_AT_DCT_Invalid_Failure__0005 3 "Reserved" 2 "Failure healed Ageing in progress" 1 "Failure matured & DTC in memory" 0 "Failure is not detected" ;
VAL_ 1179 AMT_AT_DCT_Invalid_Failure__0006 3 "Reserved" 2 "Failure healed Ageing in progress" 1 "Failure matured & DTC in memory" 0 "Failure is not detected" ;
VAL_ 1179 BCmMToFailureStatus 3 "Reserved" 2 "Failure healed aging in progress" 1 "Failure detected; DTC in memory" 0 "Failrue is not detected" ;
VAL_ 1179 BCM_MM_Failure_Status 3 "Reserved" 2 "Failure healed aging in progress" 1 "Failure detected DTC in Memory" 0 "Failure is not detected" ;
VAL_ 1179 PDC_EP_Failure_Status 3 "Reserved " 2 "Failure healed Ageing in progress" 1 "Failure matured & DTC in memory" 0 "Faiulure is not detected " ;
VAL_ 1179 PDC_BO_Failure_Status 3 "Reserved" 2 "failure healed ageing in progress" 1 "failure is detected and DTC in memory" 0 "Failure is not detected" ;
VAL_ 1179 HU_MTO_Failure_Status 3 "Reserved" 2 "Failure healed aging in progress" 1 "Failrue detected DTC in mem" 0 "Failure is not detected" ;
VAL_ 1179 HU_MM_Failure_Status 3 "Reserved" 2 "Failure healed aging in progress" 1 "Failure detected DTC in memory" 0 "Failure is not detected" ;
VAL_ 1179 AMT_AT_DCT_MTO_Failure_Status 3 "Reserved" 2 "Failure healed Ageing in progress" 1 "Failure matured & DTC in memory" 0 "Failure is not detected" ;
VAL_ 1179 IPC_MM_Failure_Status 3 "Reserved" 2 "Failure healed Ageing in progress" 1 "Failure matured & DTC in memory" 0 "Failure is not detected" ;
VAL_ 1179 IPcMToFailureStatus 3 "Reserved" 2 "Failure healed Ageing in progress" 1 "Failure matured & DTC in memory" 0 "Failure is not detected" ;
VAL_ 1179 IPcInvalidFailureStatus 3 "Reserved" 2 "Failure healed Ageing in progress" 1 "Failure matured & DTC in memory" 0 "Failure is not detected" ;
VAL_ 1180 Trailer_EP_Failure_Status 3 "Reserved" 2 "Failurehealed Ageing in progress" 1 "Failure matured & DTC in memory" 0 "Faiulure is not detected " ;
VAL_ 1180 Trailer_BO_Failure_Status 3 "Reserved" 2 "Failurehealed Ageing in progress" 1 "Failure matured & DTC in memory" 0 "Faiulure is not detected " ;
VAL_ 1180 BCmMToFailureStatus 3 "Reserved" 2 "Failure healed aging in progress" 1 "Failure detected; DTC in memory" 0 "Failrue is not detected" ;
VAL_ 1180 BCM_MM_Failure_Status 3 "Reserved" 2 "Failure healed aging in progress" 1 "Failure detected DTC in Memory" 0 "Failure is not detected" ;
